VERSION ""

NS_ :

BS_:

BU_: WRCS SRS LECM3 LECM1 ECUspare6 CMS CIOM CCM AlcoLock2

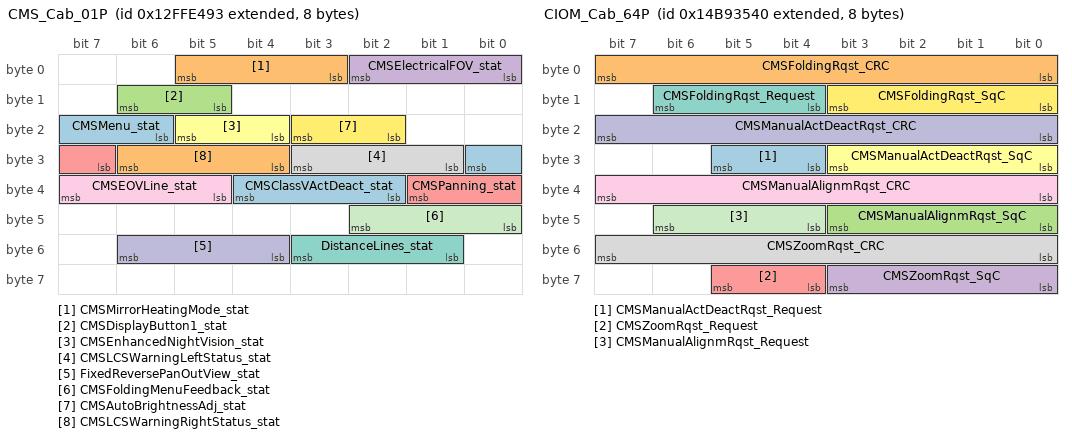
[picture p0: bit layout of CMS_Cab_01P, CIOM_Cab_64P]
BO_ 2466243731 CMS_Cab_01P: 8 CMS
 SG_ CMSMenu_stat : 22|3@1+ (1,0) [0|0] ""  CIOM
 SG_ CMSMirrorHeatingMode_stat : 3|3@1+ (1,0) [0|0] ""  CIOM
 SG_ CMSDisplayButton1_stat : 13|2@1+ (1,0) [0|0] ""  CIOM
 SG_ CMSElectricalFOV_stat : 0|3@1+ (1,0) [0|0] ""  CIOM
 SG_ CMSPanning_stat : 31|3@1+ (1,0) [0|0] ""  CIOM
 SG_ CMSEnhancedNightVision_stat : 20|2@1+ (1,0) [0|0] ""  CIOM
 SG_ DistanceLines_stat : 49|3@1+ (1,0) [0|0] ""  CIOM
 SG_ CMSLCSWarningLeftStatus_stat : 25|3@1+ (1,0) [0|0] ""  CIOM
 SG_ CMSEOVLine_stat : 37|3@1+ (1,0) [0|0] ""  CIOM
 SG_ FixedReversePanOutView_stat : 52|3@1+ (1,0) [0|0] ""  CIOM
 SG_ CMSFoldingMenuFeedback_stat : 40|3@1+ (1,0) [0|0] ""  CIOM
 SG_ CMSAutoBrightnessAdj_stat : 18|2@1+ (1,0) [0|0] ""  CIOM
 SG_ CMSClassVActDeact_stat : 34|3@1+ (1,0) [0|0] ""  CIOM
 SG_ CMSLCSWarningRightStatus_stat : 28|3@1+ (1,0) [0|0] ""  CIOM

BO_ 2495165760 CIOM_Cab_64P: 8 CIOM
 SG_ CMSManualActDeactRqst_Request : 28|2@1+ (1,0) [0|0] ""  CMS
 SG_ CMSFoldingRqst_CRC : 0|8@1+ (1,0) [0|255] ""  CMS
 SG_ CMSManualAlignmRqst_SqC : 40|4@1+ (1,0) [0|14] "NotApplicable"  CMS
 SG_ CMSZoomRqst_SqC : 56|4@1+ (1,0) [0|14] "NotApplicable"  CMS
 SG_ CMSZoomRqst_Request : 60|2@1+ (1,0) [0|0] ""  CMS
 SG_ CMSManualActDeactRqst_SqC : 24|4@1+ (1,0) [0|14] "NotApplicable"  CMS
 SG_ CMSFoldingRqst_Request : 12|3@1+ (1,0) [0|0] ""  CMS
 SG_ CMSZoomRqst_CRC : 48|8@1+ (1,0) [0|255] ""  CMS
 SG_ CMSManualAlignmRqst_CRC : 32|8@1+ (1,0) [0|255] ""  CMS
 SG_ CMSManualActDeactRqst_CRC : 16|8@1+ (1,0) [0|255] ""  CMS
 SG_ CMSManualAlignmRqst_Request : 44|3@1+ (1,0) [0|0] ""  CMS
 SG_ CMSFoldingRqst_SqC : 8|4@1+ (1,0) [0|14] "NotApplicable"  CMS

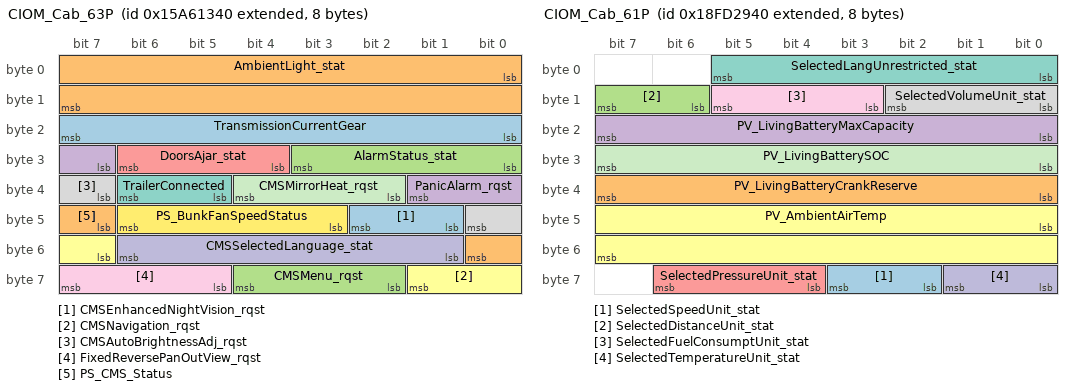
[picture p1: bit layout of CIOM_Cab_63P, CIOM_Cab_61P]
BO_ 2510689088 CIOM_Cab_63P: 8 CIOM
 SG_ CMSEnhancedNightVision_rqst : 41|2@1+ (1,0) [0|0] ""  CMS
 SG_ AmbientLight_stat : 0|16@1+ (1,0) [0|65535] "lx"  CMS
 SG_ CMSMenu_rqst : 58|3@1+ (1,0) [0|0] ""  CMS
 SG_ PanicAlarm_rqst : 31|3@1+ (1,0) [0|0] ""  CMS
 SG_ DoorsAjar_stat : 28|3@1+ (1,0) [0|0] ""  CMS
 SG_ CMSNavigation_rqst : 55|3@1+ (1,0) [0|0] ""  CMS
 SG_ TrailerConnected : 37|2@1+ (1,0) [0|0] ""  CMS
 SG_ CMSAutoBrightnessAdj_rqst : 39|2@1+ (1,0) [0|0] ""  CMS
 SG_ FixedReversePanOutView_rqst : 61|3@1+ (1,0) [0|0] ""  CMS
 SG_ CMSSelectedLanguage_stat : 49|6@1+ (1,0) [0|0] ""  CMS
 SG_ CMSMirrorHeat_rqst : 34|3@1+ (1,0) [0|0] ""  CMS
 SG_ PS_BunkFanSpeedStatus : 43|4@1+ (1,0) [0|0] ""  LECM3
 SG_ TransmissionCurrentGear : 16|8@1+ (1,-125) [-125|130] "GearValue"  CMS
 SG_ PS_CMS_Status : 47|2@1+ (1,0) [0|0] ""  LECM3
 SG_ AlarmStatus_stat : 24|4@1+ (1,0) [0|0] ""  CMS

BO_ 2566730048 CIOM_Cab_62P: 8 CIOM
 SG_ BunkACRequest : 14|2@1+ (1,0) [0|0] ""  CCM
 SG_ ClimateAirDistRequest_Vent : 8|4@1+ (1,0) [0|15] "NotApplicable"  CCM
 SG_ OpLevelItem3 : 56|8@1+ (0.5,0) [0|127.5] "Percent"  CCM
 SG_ AirRecirculationRequest : 28|2@1+ (1,0) [0|0] ""  CCM
 SG_ MaxDefrostRequest : 24|2@1+ (1,0) [0|0] ""  CCM
 SG_ CabTempRequest : 30|7@1+ (0.5,0) [0|63.5] "DegreeC"  CCM
 SG_ HVACBlowerRequest : 44|5@1+ (1,0) [0|31] "NotApplicable"  CCM
 SG_ ClimateAirDistRequest_Defrost : 4|4@1+ (1,0) [0|15] "NotApplicable"  CCM
 SG_ BunkParkClimateRequest : 54|2@1+ (1,0) [0|0] ""  CCM
 SG_ ParkingClimateRequest : 26|2@1+ (1,0) [0|0] ""  CCM
 SG_ BunkClimatePowerRequest : 22|2@1+ (1,0) [0|0] ""  CCM
 SG_ BunkClimateAutoRequest : 18|2@1+ (1,0) [0|0] ""  CCM
 SG_ ClimatePowerRequest : 20|2@1+ (1,0) [0|0] ""  CCM
 SG_ ClimateAirDistRequest_Floor : 0|4@1+ (1,0) [0|15] "NotApplicable"  CCM
 SG_ BunkHVACBlowerRequest : 49|5@1+ (1,0) [0|31] "NotApplicable"  CCM
 SG_ BunkTempRequest : 37|7@1+ (0.5,0) [0|63.5] "DegreeC"  CCM
 SG_ ClimateAutoRequest : 16|2@1+ (1,0) [0|0] ""  CCM
 SG_ ACRequest : 12|2@1+ (1,0) [0|0] ""  CCM

BO_ 2566728000 CIOM_Cab_61P: 8 CIOM
 SG_ SelectedSpeedUnit_stat : 58|2@1+ (1,0) [0|0] ""  LECM3
 SG_ PV_LivingBatteryCrankReserve : 32|8@1+ (0.5,0) [0|127.5] "Percent"  LECM3
 SG_ SelectedDistanceUnit_stat : 14|2@1+ (1,0) [0|0] ""  LECM3
 SG_ PV_LivingBatteryMaxCapacity : 16|8@1+ (0.5,0) [0|127.5] "Percent"  LECM3
 SG_ SelectedPressureUnit_stat : 60|3@1+ (1,0) [0|0] ""  LECM3
 SG_ PV_AmbientAirTemp : 40|16@1+ (0.03125,-273) [-273|1774.96875] "DegreeC"  LECM3
 SG_ SelectedLangUnrestricted_stat : 0|6@1+ (1,0) [0|0] ""  LECM3
 SG_ SelectedVolumeUnit_stat : 8|3@1+ (1,0) [0|0] ""  LECM3
 SG_ SelectedFuelConsumptUnit_stat : 11|3@1+ (1,0) [0|0] ""  LECM3
 SG_ SelectedTemperatureUnit_stat : 56|2@1+ (1,0) [0|0] ""  LECM3
 SG_ PV_LivingBatterySOC : 24|8@1+ (0.5,0) [0|127.5] "Percent"  LECM3

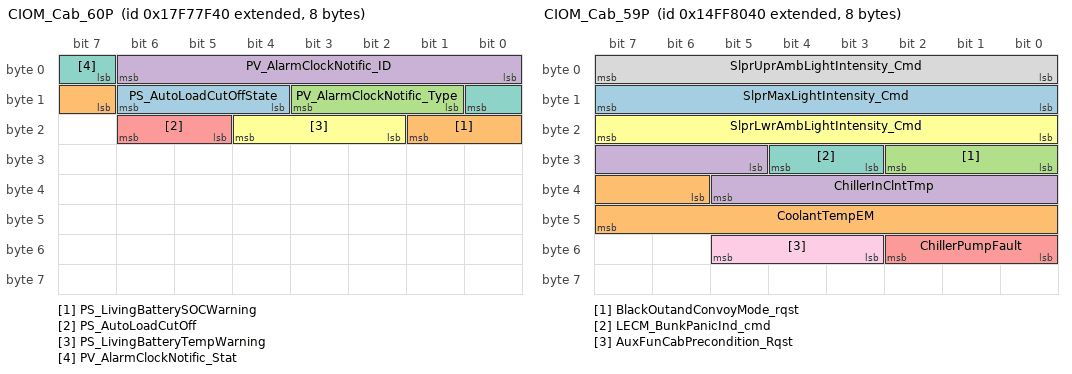
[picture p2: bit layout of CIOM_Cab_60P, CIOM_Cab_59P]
BO_ 2549579584 CIOM_Cab_60P: 8 CIOM
 SG_ PS_AutoLoadCutOffState : 12|3@1+ (1,0) [0|0] ""  LECM3
 SG_ PS_LivingBatterySOCWarning : 15|3@1+ (1,0) [0|0] ""  LECM3
 SG_ PV_AlarmClockNotific_Type : 9|3@1+ (1,0) [0|0] ""  LECM3
 SG_ PV_AlarmClockNotific_ID : 0|7@1+ (1,0) [0|0] ""  LECM3
 SG_ PS_AutoLoadCutOff : 21|2@1+ (1,0) [0|0] ""  LECM3
 SG_ PS_LivingBatteryTempWarning : 18|3@1+ (1,0) [0|0] ""  LECM3
 SG_ PV_AlarmClockNotific_Stat : 7|2@1+ (1,0) [0|0] ""  LECM3

BO_ 2499772480 CIOM_Cab_59P: 8 CIOM
 SG_ SlprMaxLightIntensity_Cmd : 8|8@1+ (1,0) [0|255] "Percent"  LECM3
 SG_ CoolantTempEM : 38|10@1+ (0.1,-10) [-10|92.3] "DegreeC"  CCM
 SG_ BlackOutandConvoyMode_rqst : 24|3@1+ (1,0) [0|0] ""  LECM3
 SG_ ChillerInClntTmp : 29|9@1+ (0.1,0) [0|51.1] "DegreeC"  CCM
 SG_ ChillerPumpFault : 48|3@1+ (1,0) [0|0] ""  CCM
 SG_ SlprLwrAmbLightIntensity_Cmd : 16|8@1+ (1,0) [0|255] "Percent"  LECM3
 SG_ LECM_BunkPanicInd_cmd : 27|2@1+ (1,0) [0|0] ""  LECM3
 SG_ SlprUprAmbLightIntensity_Cmd : 0|8@1+ (1,0) [0|255] "Percent"  LECM3
 SG_ AuxFunCabPrecondition_Rqst : 51|3@1+ (1,0) [0|0] ""  CCM

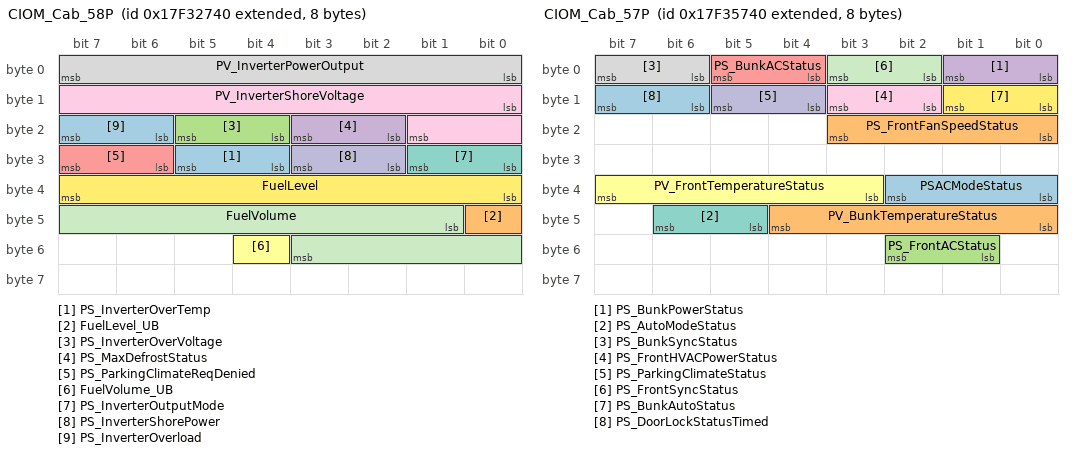
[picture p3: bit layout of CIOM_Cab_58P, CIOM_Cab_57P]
BO_ 2549294912 CIOM_Cab_58P: 8 CIOM
 SG_ PS_InverterOverTemp : 28|2@1+ (1,0) [0|0] ""  LECM3
 SG_ FuelLevel_UB : 40|1@1+ (1,0) [0|0] "" Vector__XXX
 SG_ PS_InverterOverVoltage : 20|2@1+ (1,0) [0|0] ""  LECM3
 SG_ PS_MaxDefrostStatus : 18|2@1+ (1,0) [0|0] ""  LECM3
 SG_ PS_ParkingClimateReqDenied : 30|2@1+ (1,0) [0|0] ""  LECM3
 SG_ FuelVolume_UB : 52|1@1+ (1,0) [0|0] "" Vector__XXX
 SG_ PS_InverterOutputMode : 24|2@1+ (1,0) [0|0] ""  LECM3
 SG_ PV_InverterPowerOutput : 0|8@1+ (10,0) [0|2550] "W"  LECM3
 SG_ PV_InverterShoreVoltage : 8|10@1+ (1,0) [0|1023] "V"  LECM3
 SG_ PS_InverterShorePower : 26|2@1+ (1,0) [0|0] ""  LECM3
 SG_ FuelVolume : 41|11@1+ (1,0) [0|2047] "l"  CCM
 SG_ FuelLevel : 32|8@1+ (0.4,0) [0|102] "Percent"  CCM
 SG_ PS_InverterOverload : 22|2@1+ (1,0) [0|0] ""  LECM3

BO_ 2549307200 CIOM_Cab_57P: 8 CIOM
 SG_ PSACModeStatus : 32|3@1+ (1,0) [0|0] ""  LECM3
 SG_ PS_FrontFanSpeedStatus : 16|4@1+ (1,0) [0|0] ""  LECM3
 SG_ PS_FrontACStatus : 49|2@1+ (1,0) [0|0] ""  LECM3
 SG_ PS_BunkPowerStatus : 0|2@1+ (1,0) [0|0] ""  LECM3
 SG_ PS_BunkACStatus : 4|2@1+ (1,0) [0|0] ""  LECM3
 SG_ PV_FrontTemperatureStatus : 35|5@1+ (1,0) [0|0] ""  LECM3
 SG_ PS_AutoModeStatus : 45|2@1+ (1,0) [0|0] ""  LECM3
 SG_ PS_BunkSyncStatus : 6|2@1+ (1,0) [0|0] ""  LECM3
 SG_ PS_FrontHVACPowerStatus : 10|2@1+ (1,0) [0|0] ""  LECM3
 SG_ PS_ParkingClimateStatus : 12|2@1+ (1,0) [0|0] ""  LECM3
 SG_ PS_FrontSyncStatus : 2|2@1+ (1,0) [0|0] ""  LECM3
 SG_ PS_BunkAutoStatus : 8|2@1+ (1,0) [0|0] ""  LECM3
 SG_ PS_DoorLockStatusTimed : 14|2@1+ (1,0) [0|0] ""  LECM3
 SG_ PV_BunkTemperatureStatus : 40|5@1+ (1,0) [0|0] ""  LECM3

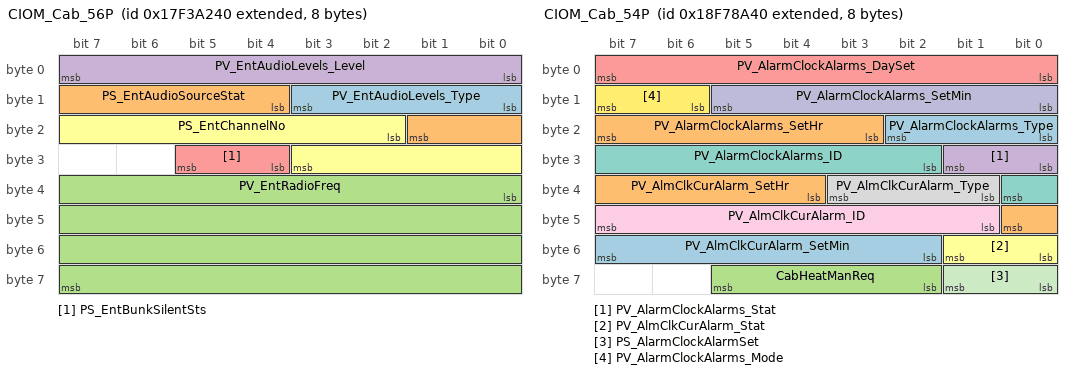
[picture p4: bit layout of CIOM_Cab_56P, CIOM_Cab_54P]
BO_ 2549326400 CIOM_Cab_56P: 8 CIOM
 SG_ PV_EntAudioLevels_Type : 8|4@1+ (1,0) [0|0] ""  LECM3
 SG_ PS_EntAudioSourceStat : 12|6@1+ (1,0) [0|0] ""  LECM3
 SG_ PV_EntRadioFreq : 32|32@1+ (1000,0) [0|4294967295000] "Hz"  LECM3
 SG_ PV_EntAudioLevels_Level : 0|8@1+ (1,-100) [-100|155] "Percent"  LECM3
 SG_ PS_EntBunkSilentSts : 28|2@1+ (1,0) [0|0] ""  LECM3
 SG_ PS_EntChannelNo : 18|10@1+ (1,0) [0|1023] "NotApplicable"  LECM3

BO_ 2566293568 CIOM_Cab_55P: 8 CIOM
 SG_ PSPClimTimStatus_Tue : 3|1@1+ (1,0) [0|0] ""  LECM3
 SG_ PSPClimTimStatus_Min : 8|8@1+ (1,0) [0|255] "min"  LECM3
 SG_ PSPClimTimStatus_TotalNoTimers : 32|8@1+ (1,0) [0|0] ""  LECM3
 SG_ PSPClimTimStatus_TimerNr : 40|8@1+ (1,0) [0|0] ""  LECM3
 SG_ PSPClimTimStatus_Rec : 0|1@1+ (1,0) [0|0] ""  LECM3
 SG_ PSPClimTimStatus_Status : 22|2@1+ (1,0) [0|0] ""  LECM3
 SG_ PSPClimTimStatus_Dur : 56|7@1+ (1,0) [0|127] "min"  LECM3
 SG_ PSPClimTimStatus_Type : 19|3@1+ (1,0) [0|0] ""  LECM3
 SG_ PSPClimTimStatus_Wed : 6|1@1+ (1,0) [0|0] ""  LECM3
 SG_ PSPClimTimStatus_Fri : 1|1@1+ (1,0) [0|0] ""  LECM3
 SG_ PSPClimTimStatus_Thu : 2|1@1+ (1,0) [0|0] ""  LECM3
 SG_ PSPClimTimStatus_Sat : 7|1@1+ (1,0) [0|0] ""  LECM3
 SG_ PSPClimTimStatus_Hrs : 24|8@1+ (1,0) [0|255] "h"  LECM3
 SG_ PSPClimTimStatus_MinRes : 16|3@1+ (1,0) [0|0] ""  LECM3
 SG_ PSPClimTimStatus_Temp : 48|8@1+ (0.5,0) [0|127.5] "DegreeC"  LECM3
 SG_ PSPClimTimStatus_Sun : 5|1@1+ (1,0) [0|0] ""  LECM3
 SG_ PSPClimTimStatus_Mon : 4|1@1+ (1,0) [0|0] ""  LECM3

BO_ 2566359616 CIOM_Cab_54P: 8 CIOM
 SG_ PV_AlarmClockAlarms_Type : 16|3@1+ (1,0) [0|0] ""  LECM3
 SG_ PV_AlmClkCurAlarm_SetHr : 36|5@1+ (1,0) [0|31] "h"  LECM3
 SG_ CabHeatManReq : 58|4@1+ (1,0) [0|15] "NotApplicable"  CCM
 SG_ PV_AlarmClockAlarms_Stat : 24|2@1+ (1,0) [0|0] ""  LECM3
 SG_ PV_AlarmClockAlarms_DaySet : 0|8@1+ (1,0) [0|255] ""  LECM3
 SG_ PV_AlmClkCurAlarm_Stat : 48|2@1+ (1,0) [0|0] ""  LECM3
 SG_ PV_AlarmClockAlarms_ID : 26|7@1+ (1,0) [0|0] ""  LECM3
 SG_ PV_AlmClkCurAlarm_Type : 33|3@1+ (1,0) [0|0] ""  LECM3
 SG_ PV_AlmClkCurAlarm_ID : 41|7@1+ (1,0) [0|0] ""  LECM3
 SG_ PV_AlarmClockAlarms_SetMin : 8|6@1+ (1,0) [0|63] "min"  LECM3
 SG_ PS_AlarmClockAlarmSet : 56|2@1+ (1,0) [0|0] ""  LECM3
 SG_ PV_AlarmClockAlarms_Mode : 14|2@1+ (1,0) [0|0] ""  LECM3
 SG_ PV_AlmClkCurAlarm_SetMin : 50|6@1+ (1,0) [0|63] "min"  LECM3
 SG_ PV_AlarmClockAlarms_SetHr : 19|5@1+ (1,0) [0|31] "h"  LECM3

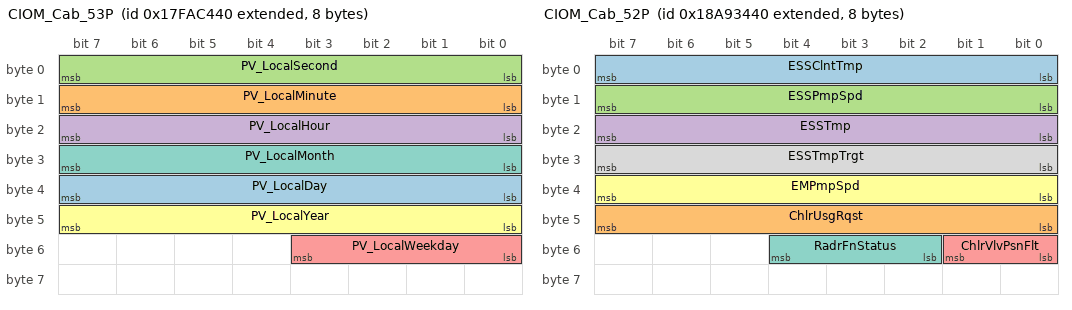
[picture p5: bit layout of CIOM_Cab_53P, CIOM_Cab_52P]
BO_ 2549793856 CIOM_Cab_53P: 8 CIOM
 SG_ PV_LocalDay : 32|8@1+ (1,0) [0|255] "Days"  LECM3
 SG_ PV_LocalMinute : 8|8@1+ (1,0) [0|255] "min"  LECM3
 SG_ PV_LocalSecond : 0|8@1+ (1,0) [0|255] "s"  LECM3
 SG_ PV_LocalHour : 16|8@1+ (1,0) [0|255] "h"  LECM3
 SG_ PV_LocalWeekday : 48|4@1+ (1,0) [0|0] ""  LECM3
 SG_ PV_LocalYear : 40|8@1+ (1,1985) [1985|2240] "Years"  LECM3
 SG_ PV_LocalMonth : 24|8@1+ (1,0) [0|255] "Months"  LECM3

BO_ 2561225792 CIOM_Cab_52P: 8 CIOM
 SG_ ESSClntTmp : 0|8@1+ (0.5,-25) [-25|102.5] "DegreeC"  CCM
 SG_ ChlrUsgRqst : 40|8@1+ (1,0) [0|255] "Percent"  CCM
 SG_ ESSPmpSpd : 8|8@1+ (1,0) [0|255] "Percent"  CCM
 SG_ ESSTmp : 16|8@1+ (0.5,-25) [-25|102.5] "DegreeC"  CCM
 SG_ ChlrVlvPsnFlt : 48|2@1+ (1,0) [0|0] ""  CCM
 SG_ EMPmpSpd : 32|8@1+ (1,0) [0|255] "Percent"  CCM
 SG_ RadrFnStatus : 50|3@1+ (1,0) [0|0] ""  CCM
 SG_ ESSTmpTrgt : 24|8@1+ (1,0) [0|255] "DegreeC"  CCM

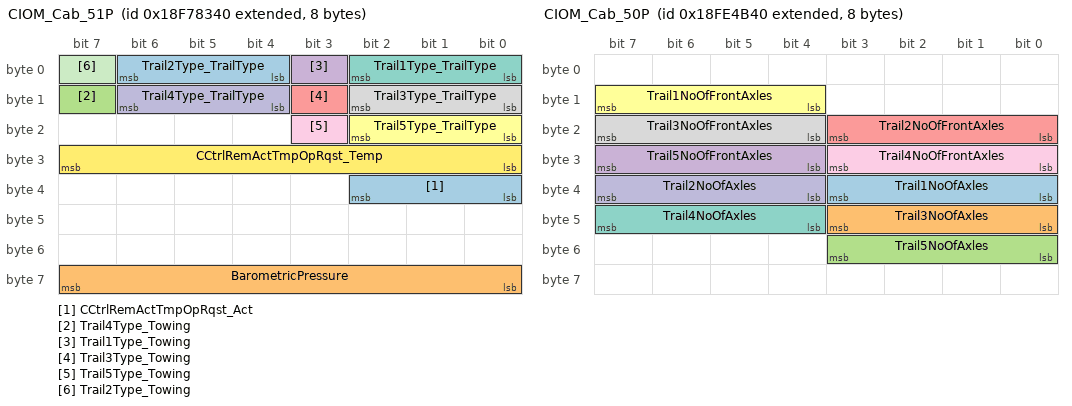
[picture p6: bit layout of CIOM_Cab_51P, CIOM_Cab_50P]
BO_ 2566357824 CIOM_Cab_51P: 8 CIOM
 SG_ CCtrlRemActTmpOpRqst_Act : 32|3@1+ (1,0) [0|0] ""  CCM
 SG_ BarometricPressure : 56|8@1+ (0.5,0) [0|127.5] "kPa"  CCM
 SG_ Trail4Type_Towing : 15|1@1+ (1,0) [0|0] ""  WRCS
 SG_ Trail1Type_Towing : 3|1@1+ (1,0) [0|0] ""  WRCS
 SG_ Trail3Type_Towing : 11|1@1+ (1,0) [0|0] ""  WRCS
 SG_ Trail5Type_TrailType : 16|3@1+ (1,0) [0|0] ""  WRCS
 SG_ Trail1Type_TrailType : 0|3@1+ (1,0) [0|0] ""  WRCS
 SG_ Trail3Type_TrailType : 8|3@1+ (1,0) [0|0] ""  WRCS
 SG_ Trail5Type_Towing : 19|1@1+ (1,0) [0|0] ""  WRCS
 SG_ Trail4Type_TrailType : 12|3@1+ (1,0) [0|0] ""  WRCS
 SG_ Trail2Type_Towing : 7|1@1+ (1,0) [0|0] ""  WRCS
 SG_ CCtrlRemActTmpOpRqst_Temp : 24|8@1+ (0.5,0) [0|127.5] "DegreeC"  CCM
 SG_ Trail2Type_TrailType : 4|3@1+ (1,0) [0|0] ""  WRCS

BO_ 2566802240 CIOM_Cab_50P: 8 CIOM
 SG_ Trail1NoOfAxles : 32|4@1+ (1,0) [0|15] "NotApplicable"  WRCS
 SG_ Trail3NoOfAxles : 40|4@1+ (1,0) [0|15] "NotApplicable"  WRCS
 SG_ Trail5NoOfAxles : 48|4@1+ (1,0) [0|15] "NotApplicable"  WRCS
 SG_ Trail5NoOfFrontAxles : 28|4@1+ (1,0) [0|15] "NotApplicable"  WRCS
 SG_ Trail2NoOfFrontAxles : 16|4@1+ (1,0) [0|15] "NotApplicable"  WRCS
 SG_ Trail1NoOfFrontAxles : 12|4@1+ (1,0) [0|15] "NotApplicable"  WRCS
 SG_ Trail4NoOfAxles : 44|4@1+ (1,0) [0|15] "NotApplicable"  WRCS
 SG_ Trail3NoOfFrontAxles : 20|4@1+ (1,0) [0|15] "NotApplicable"  WRCS
 SG_ Trail4NoOfFrontAxles : 24|4@1+ (1,0) [0|15] "NotApplicable"  WRCS
 SG_ Trail2NoOfAxles : 36|4@1+ (1,0) [0|15] "NotApplicable"  WRCS

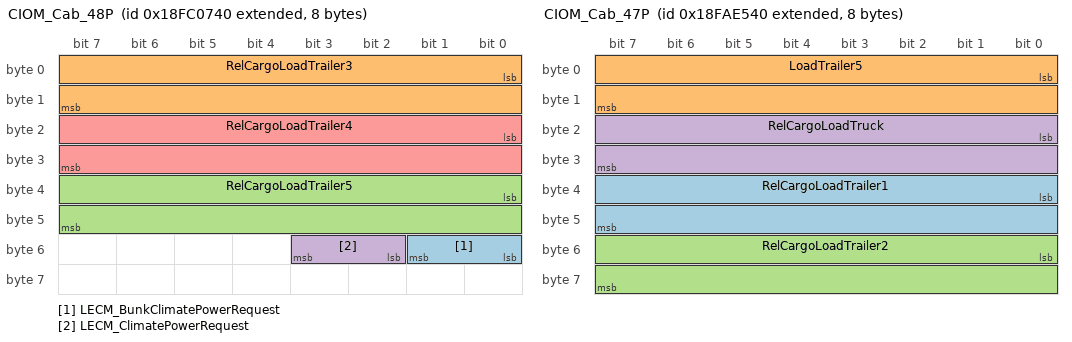
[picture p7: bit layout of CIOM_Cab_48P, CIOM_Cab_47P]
BO_ 2566653760 CIOM_Cab_48P: 8 CIOM
 SG_ LECM_BunkClimatePowerRequest : 48|2@1+ (1,0) [0|0] ""  CCM
 SG_ RelCargoLoadTrailer3 : 0|16@1+ (4,-128508) [-128508|133632] "kg"  WRCS
 SG_ RelCargoLoadTrailer5 : 32|16@1+ (4,-128508) [-128508|133632] "kg"  WRCS
 SG_ LECM_ClimatePowerRequest : 50|2@1+ (1,0) [0|0] ""  CCM
 SG_ RelCargoLoadTrailer4 : 16|16@1+ (4,-128508) [-128508|133632] "kg"  WRCS

BO_ 2566579520 CIOM_Cab_47P: 8 CIOM
 SG_ RelCargoLoadTrailer1 : 32|16@1+ (4,-128508) [-128508|133632] "kg"  WRCS
 SG_ LoadTrailer5 : 0|16@1+ (2,0) [0|131070] "kg"  WRCS
 SG_ RelCargoLoadTrailer2 : 48|16@1+ (4,-128508) [-128508|133632] "kg"  WRCS
 SG_ RelCargoLoadTruck : 16|16@1+ (4,-128508) [-128508|133632] "kg"  WRCS

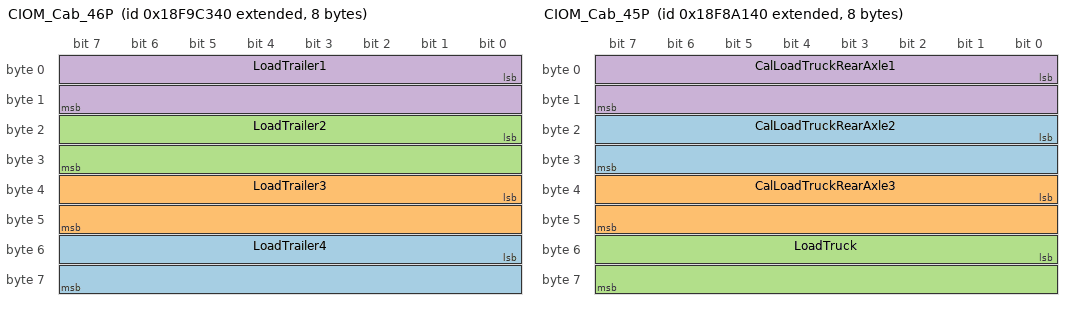
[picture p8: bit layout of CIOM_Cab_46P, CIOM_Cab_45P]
BO_ 2566505280 CIOM_Cab_46P: 8 CIOM
 SG_ LoadTrailer4 : 48|16@1+ (2,0) [0|131070] "kg"  WRCS
 SG_ LoadTrailer3 : 32|16@1+ (2,0) [0|131070] "kg"  WRCS
 SG_ LoadTrailer2 : 16|16@1+ (2,0) [0|131070] "kg"  WRCS
 SG_ LoadTrailer1 : 0|16@1+ (2,0) [0|131070] "kg"  WRCS

BO_ 2566431040 CIOM_Cab_45P: 8 CIOM
 SG_ CalLoadTruckRearAxle2 : 16|16@1+ (0.5,0) [0|32767.5] "kg"  WRCS
 SG_ CalLoadTruckRearAxle3 : 32|16@1+ (0.5,0) [0|32767.5] "kg"  WRCS
 SG_ LoadTruck : 48|16@1+ (2,0) [0|131070] "kg"  WRCS
 SG_ CalLoadTruckRearAxle1 : 0|16@1+ (0.5,0) [0|32767.5] "kg"  WRCS

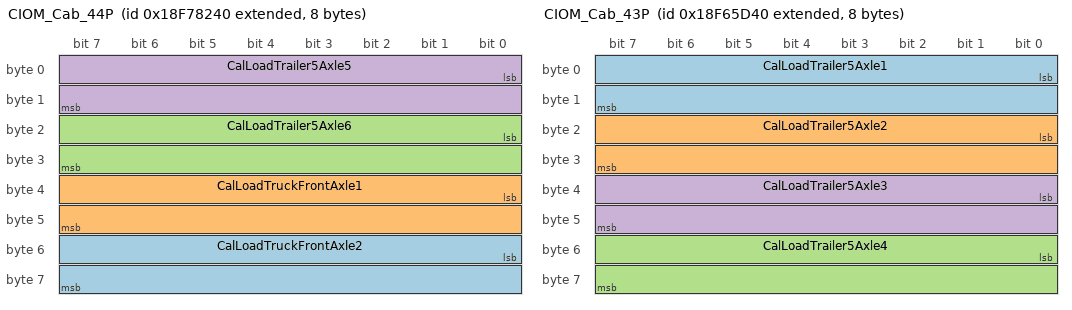
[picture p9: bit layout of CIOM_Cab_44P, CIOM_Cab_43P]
BO_ 2566357568 CIOM_Cab_44P: 8 CIOM
 SG_ CalLoadTruckFrontAxle2 : 48|16@1+ (0.5,0) [0|32767.5] "kg"  WRCS
 SG_ CalLoadTruckFrontAxle1 : 32|16@1+ (0.5,0) [0|32767.5] "kg"  WRCS
 SG_ CalLoadTrailer5Axle6 : 16|16@1+ (0.5,0) [0|32767.5] "kg"  WRCS
 SG_ CalLoadTrailer5Axle5 : 0|16@1+ (0.5,0) [0|32767.5] "kg"  WRCS

BO_ 2566282560 CIOM_Cab_43P: 8 CIOM
 SG_ CalLoadTrailer5Axle1 : 0|16@1+ (0.5,0) [0|32767.5] "kg"  WRCS
 SG_ CalLoadTrailer5Axle2 : 16|16@1+ (0.5,0) [0|32767.5] "kg"  WRCS
 SG_ CalLoadTrailer5Axle4 : 48|16@1+ (0.5,0) [0|32767.5] "kg"  WRCS
 SG_ CalLoadTrailer5Axle3 : 32|16@1+ (0.5,0) [0|32767.5] "kg"  WRCS

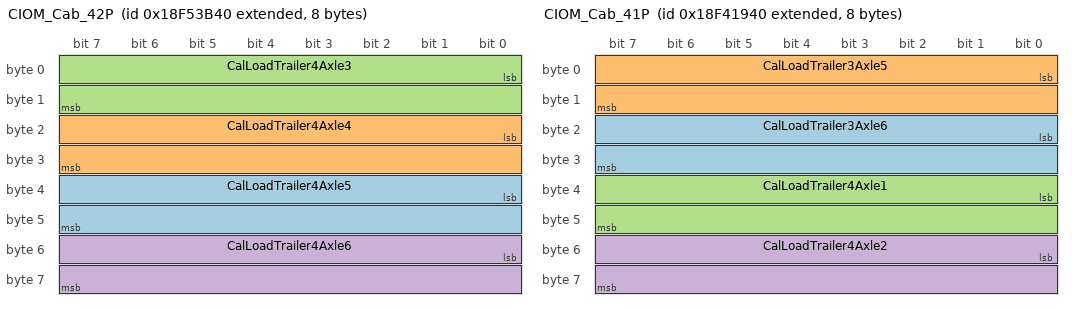
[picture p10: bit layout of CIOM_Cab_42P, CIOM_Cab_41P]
BO_ 2566208320 CIOM_Cab_42P: 8 CIOM
 SG_ CalLoadTrailer4Axle5 : 32|16@1+ (0.5,0) [0|32767.5] "kg"  WRCS
 SG_ CalLoadTrailer4Axle4 : 16|16@1+ (0.5,0) [0|32767.5] "kg"  WRCS
 SG_ CalLoadTrailer4Axle3 : 0|16@1+ (0.5,0) [0|32767.5] "kg"  WRCS
 SG_ CalLoadTrailer4Axle6 : 48|16@1+ (0.5,0) [0|32767.5] "kg"  WRCS

BO_ 2566134080 CIOM_Cab_41P: 8 CIOM
 SG_ CalLoadTrailer3Axle6 : 16|16@1+ (0.5,0) [0|32767.5] "kg"  WRCS
 SG_ CalLoadTrailer3Axle5 : 0|16@1+ (0.5,0) [0|32767.5] "kg"  WRCS
 SG_ CalLoadTrailer4Axle1 : 32|16@1+ (0.5,0) [0|32767.5] "kg"  WRCS
 SG_ CalLoadTrailer4Axle2 : 48|16@1+ (0.5,0) [0|32767.5] "kg"  WRCS

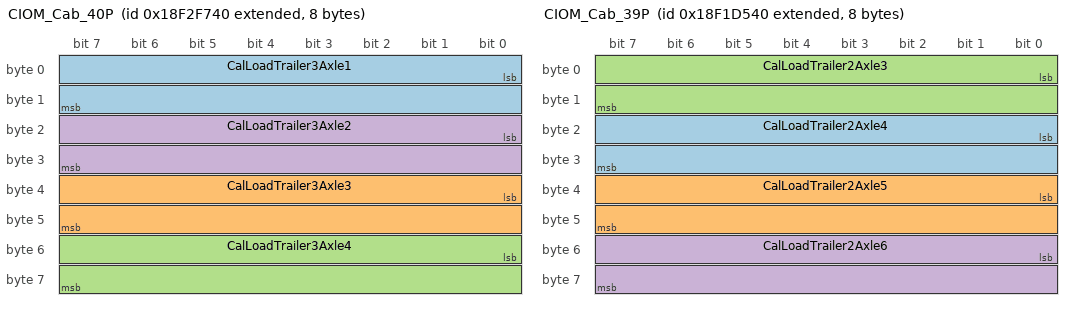
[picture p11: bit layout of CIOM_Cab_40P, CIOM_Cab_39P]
BO_ 2566059840 CIOM_Cab_40P: 8 CIOM
 SG_ CalLoadTrailer3Axle1 : 0|16@1+ (0.5,0) [0|32767.5] "kg"  WRCS
 SG_ CalLoadTrailer3Axle3 : 32|16@1+ (0.5,0) [0|32767.5] "kg"  WRCS
 SG_ CalLoadTrailer3Axle4 : 48|16@1+ (0.5,0) [0|32767.5] "kg"  WRCS
 SG_ CalLoadTrailer3Axle2 : 16|16@1+ (0.5,0) [0|32767.5] "kg"  WRCS

BO_ 2565985600 CIOM_Cab_39P: 8 CIOM
 SG_ CalLoadTrailer2Axle4 : 16|16@1+ (0.5,0) [0|32767.5] "kg"  WRCS
 SG_ CalLoadTrailer2Axle5 : 32|16@1+ (0.5,0) [0|32767.5] "kg"  WRCS
 SG_ CalLoadTrailer2Axle3 : 0|16@1+ (0.5,0) [0|32767.5] "kg"  WRCS
 SG_ CalLoadTrailer2Axle6 : 48|16@1+ (0.5,0) [0|32767.5] "kg"  WRCS

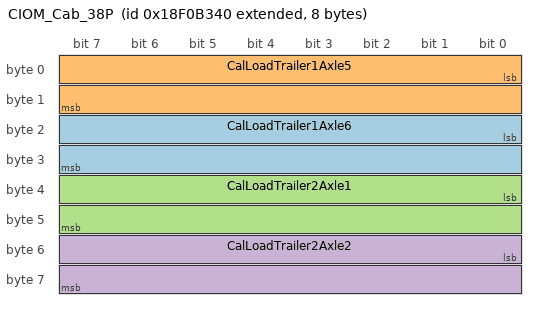
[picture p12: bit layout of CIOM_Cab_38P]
BO_ 2565911360 CIOM_Cab_38P: 8 CIOM
 SG_ CalLoadTrailer1Axle6 : 16|16@1+ (0.5,0) [0|32767.5] "kg"  WRCS
 SG_ CalLoadTrailer1Axle5 : 0|16@1+ (0.5,0) [0|32767.5] "kg"  WRCS
 SG_ CalLoadTrailer2Axle1 : 32|16@1+ (0.5,0) [0|32767.5] "kg"  WRCS
 SG_ CalLoadTrailer2Axle2 : 48|16@1+ (0.5,0) [0|32767.5] "kg"  WRCS

CM_ SG_ 2510689088 TransmissionCurrentGear "254 Error ; 255 Not available";
CM_ SG_ 2549294912 FuelLevel "254 Error ; 255 Not available";
CM_ SG_ 2566357824 BarometricPressure "254 Error ; 255 Not available";
CM_ SG_ 2566802240 Trail1NoOfAxles "15 Not available";
CM_ SG_ 2566802240 Trail3NoOfAxles "15 Not available";
CM_ SG_ 2566802240 Trail5NoOfAxles "15 Not available";
CM_ SG_ 2566802240 Trail5NoOfFrontAxles "15 Not available";
CM_ SG_ 2566802240 Trail2NoOfFrontAxles "15 Not available";
CM_ SG_ 2566802240 Trail1NoOfFrontAxles "15 Not available";
CM_ SG_ 2566802240 Trail4NoOfAxles "15 Not available";
CM_ SG_ 2566802240 Trail3NoOfFrontAxles "15 Not available";
CM_ SG_ 2566802240 Trail4NoOfFrontAxles "15 Not available";
CM_ SG_ 2566802240 Trail2NoOfAxles "15 Not available";
CM_ SG_ 2566579520 LoadTrailer5 "65024 - 65279 Error ; 65280 - 65535 Not Available";
CM_ SG_ 2566505280 LoadTrailer4 "65024 - 65279 Error ; 65280 - 65535 Not Available";
CM_ SG_ 2566505280 LoadTrailer3 "65024 - 65279 Error ; 65280 - 65535 Not Available";
CM_ SG_ 2566505280 LoadTrailer2 "65024 - 65279 Error ; 65280 - 65535 Not Available";
CM_ SG_ 2566505280 LoadTrailer1 "65024 - 65279 Error ; 65280 - 65535 Not Available";
CM_ SG_ 2566431040 CalLoadTruckRearAxle2 "65024 - 65279 Error ; 65280 - 65535 Not available";
CM_ SG_ 2566431040 CalLoadTruckRearAxle3 "65024 - 65279 Error ; 65280 - 65535 Not available";
CM_ SG_ 2566431040 LoadTruck "65024 - 65279 Error ; 65280 - 65535 Not Available";
CM_ SG_ 2566431040 CalLoadTruckRearAxle1 "65024 - 65279 Error ; 65280 - 65535 Not available";
CM_ SG_ 2566357568 CalLoadTruckFrontAxle2 "65024 - 65279 Error ; 65280 - 65535 Not available";
CM_ SG_ 2566357568 CalLoadTruckFrontAxle1 "65024 - 65279 Error ; 65280 - 65535 Not available";
CM_ SG_ 2566357568 CalLoadTrailer5Axle6 "65024 - 65279 Error ; 65280 - 65535 Not available";
CM_ SG_ 2566357568 CalLoadTrailer5Axle5 "65024 - 65279 Error ; 65280 - 65535 Not available";
CM_ SG_ 2566282560 CalLoadTrailer5Axle1 "65024 - 65279 Error ; 65280 - 65535 Not available";
CM_ SG_ 2566282560 CalLoadTrailer5Axle2 "65024 - 65279 Error ; 65280 - 65535 Not available";
CM_ SG_ 2566282560 CalLoadTrailer5Axle4 "65024 - 65279 Error ; 65280 - 65535 Not available";
CM_ SG_ 2566282560 CalLoadTrailer5Axle3 "65024 - 65279 Error ; 65280 - 65535 Not available";
CM_ SG_ 2566208320 CalLoadTrailer4Axle5 "65024 - 65279 Error ; 65280 - 65535 Not available";
CM_ SG_ 2566208320 CalLoadTrailer4Axle4 "65024 - 65279 Error ; 65280 - 65535 Not available";
CM_ SG_ 2566208320 CalLoadTrailer4Axle3 "65024 - 65279 Error ; 65280 - 65535 Not available";
CM_ SG_ 2566208320 CalLoadTrailer4Axle6 "65024 - 65279 Error ; 65280 - 65535 Not available";
CM_ SG_ 2566134080 CalLoadTrailer3Axle6 "65024 - 65279 Error ; 65280 - 65535 Not available";
CM_ SG_ 2566134080 CalLoadTrailer3Axle5 "65024 - 65279 Error ; 65280 - 65535 Not available";
CM_ SG_ 2566134080 CalLoadTrailer4Axle1 "65024 - 65279 Error ; 65280 - 65535 Not available";
CM_ SG_ 2566134080 CalLoadTrailer4Axle2 "65024 - 65279 Error ; 65280 - 65535 Not available";
CM_ SG_ 2566059840 CalLoadTrailer3Axle1 "65024 - 65279 Error ; 65280 - 65535 Not available";
CM_ SG_ 2566059840 CalLoadTrailer3Axle3 "65024 - 65279 Error ; 65280 - 65535 Not available";
CM_ SG_ 2566059840 CalLoadTrailer3Axle4 "65024 - 65279 Error ; 65280 - 65535 Not available";
CM_ SG_ 2566059840 CalLoadTrailer3Axle2 "65024 - 65279 Error ; 65280 - 65535 Not available";
CM_ SG_ 2565985600 CalLoadTrailer2Axle4 "65024 - 65279 Error ; 65280 - 65535 Not available";
CM_ SG_ 2565985600 CalLoadTrailer2Axle5 "65024 - 65279 Error ; 65280 - 65535 Not available";
CM_ SG_ 2565985600 CalLoadTrailer2Axle3 "65024 - 65279 Error ; 65280 - 65535 Not available";
CM_ SG_ 2565985600 CalLoadTrailer2Axle6 "65024 - 65279 Error ; 65280 - 65535 Not available";
CM_ SG_ 2565911360 CalLoadTrailer1Axle6 "65024 - 65279 Error ; 65280 - 65535 Not available";
CM_ SG_ 2565911360 CalLoadTrailer1Axle5 "65024 - 65279 Error ; 65280 - 65535 Not available";
CM_ SG_ 2565911360 CalLoadTrailer2Axle1 "65024 - 65279 Error ; 65280 - 65535 Not available";
CM_ SG_ 2565911360 CalLoadTrailer2Axle2 "65024 - 65279 Error ; 65280 - 65535 Not available";
BA_DEF_ BO_  "GenMsgStartDelayTime" INT 0 0;
BA_DEF_ BO_  "GenMsgDelayTime" INT 0 0;
BA_DEF_ BO_  "GenMsgCycleTime" INT 0 0;
BA_DEF_ BO_  "GenMsgSendType" ENUM  "Cyclic","NotUsed","NotUsed","NotUsed","NotUsed","NotUsed","NotUsed","IfActive","NoMsgSendType","NotUsed";
BA_DEF_ SG_  "GenSigStartValue" INT 0 0;
BA_DEF_ SG_  "GenSigCycleTimeActive" INT 0 0;
BA_DEF_ SG_  "GenSigCycleTime" INT 0 0;
BA_DEF_ SG_  "GenSigSendType" ENUM  "Cyclic","OnWrite","OnWriteWithRepetition","OnChange","OnChangeWithRepetition","IfActive","IfActiveWithRepetition","NoSigSendType","NotUsed","NotUsed","NotUsed","NotUsed","NotUsed";
BA_DEF_ BO_  "VFrameFormat" ENUM  "StandardCAN","ExtendedCAN","reserved","J1939PG","reserved","reserved","reserved","reserved","reserved","reserved","reserved","reserved","reserved","reserved","StandardCAN_FD","ExtendedCAN_FD";
BA_DEF_ SG_  "SigType" ENUM  "Default","Range","RangeSigned","ASCII","Discrete","Control","ReferencePGN","DTC","StringDelimiter","StringLength","StringLengthControl";
BA_DEF_ SG_  "SeToolVersion_SIGNAL" STRING ;
BA_DEF_ SG_  "SeToolUniqueID_SIGNAL" STRING ;
BA_DEF_ SG_  "SeToolOwnerSigGroup_SIGNAL" STRING ;
BA_DEF_ SG_  "SeToolOwnerSigGroupID_SIGNAL" STRING ;
BA_DEF_ SG_  "SeToolName_SIGNAL" STRING ;
BA_DEF_ SG_  "SeToolItemID_SIGNAL" STRING ;
BA_DEF_ SG_  "SeToolAncestorID_SIGNAL" STRING ;
BA_DEF_ SG_  "Platform_VMCU1_Sig" ENUM  "No","Yes";
BA_DEF_ BO_  "NmAsrMessage" ENUM  "No","Yes";
BA_DEF_ SG_  "NeedsUpdateBit" ENUM  "No","Yes";
BA_DEF_ SG_  "MmAnSignal" ENUM  "No","Yes";
BA_DEF_ SG_  "GenSigMaxLatency" INT 0 65535;
BA_DEF_ SG_  "GenSigILSupport" ENUM  "Yes","No";
BA_DEF_ BO_  "GenMsgILSupport" ENUM  "No","Yes";
BA_DEF_ SG_  "E2EProfile" STRING ;
BA_DEF_ SG_  "E2EDataLength" INT 0 65535;
BA_DEF_ SG_  "E2EDataId" INT 0 65535;
BA_DEF_ BO_  "DiagUUDTResponse" ENUM  "No","Yes";
BA_DEF_ BO_  "DiagState" ENUM  "No","Yes";
BA_DEF_ BO_  "DiagResponse" ENUM  "No","Yes";
BA_DEF_ BO_  "DiagRequest" ENUM  "No","Yes";
BA_DEF_ BO_  "DiagConnection" HEX 0 65535;
BA_DEF_ BO_  "CanTpSTmin" INT 0 255;
BA_DEF_ BO_  "CanTpFcFrameId" HEX 0 2147483647;
BA_DEF_ BO_  "CanTpBs" INT 0 255;
BA_DEF_REL_ BU_SG_REL_  "GenSigTimeoutTime" INT 0 65535;
BA_DEF_REL_ BU_SG_REL_  "GenSigFirstTimeoutTime" INT 0 65535;
BA_DEF_DEF_  "GenMsgStartDelayTime" 0;
BA_DEF_DEF_  "GenMsgDelayTime" 0;
BA_DEF_DEF_  "GenMsgCycleTime" 0;
BA_DEF_DEF_  "GenMsgSendType" "Cyclic";
BA_DEF_DEF_  "GenSigStartValue" 0;
BA_DEF_DEF_  "GenSigCycleTimeActive" 0;
BA_DEF_DEF_  "GenSigCycleTime" 0;
BA_DEF_DEF_  "GenSigSendType" "Cyclic";
BA_DEF_DEF_  "VFrameFormat" "ExtendedCAN";
BA_DEF_DEF_  "SigType" "Default";
BA_DEF_DEF_  "SeToolVersion_SIGNAL" "";
BA_DEF_DEF_  "SeToolUniqueID_SIGNAL" "";
BA_DEF_DEF_  "SeToolOwnerSigGroup_SIGNAL" "";
BA_DEF_DEF_  "SeToolOwnerSigGroupID_SIGNAL" "";
BA_DEF_DEF_  "SeToolName_SIGNAL" "";
BA_DEF_DEF_  "SeToolItemID_SIGNAL" "";
BA_DEF_DEF_  "SeToolAncestorID_SIGNAL" "";
BA_DEF_DEF_  "Platform_VMCU1_Sig" "No";
BA_DEF_DEF_  "NmAsrMessage" "No";
BA_DEF_DEF_  "NeedsUpdateBit" "No";
BA_DEF_DEF_  "MmAnSignal" "No";
BA_DEF_DEF_  "GenSigMaxLatency" 0;
BA_DEF_DEF_  "GenSigILSupport" "Yes";
BA_DEF_DEF_  "GenMsgILSupport" "Yes";
BA_DEF_DEF_  "E2EProfile" "none";
BA_DEF_DEF_  "E2EDataLength" 0;
BA_DEF_DEF_  "E2EDataId" 0;
BA_DEF_DEF_  "DiagUUDTResponse" "No";
BA_DEF_DEF_  "DiagState" "No";
BA_DEF_DEF_  "DiagResponse" "No";
BA_DEF_DEF_  "DiagRequest" "No";
BA_DEF_DEF_  "DiagConnection" 0;
BA_DEF_DEF_  "CanTpSTmin" 0;
BA_DEF_DEF_  "CanTpFcFrameId" 2147483647;
BA_DEF_DEF_  "CanTpBs" 255;
BA_DEF_DEF_REL_ "GenSigTimeoutTime" 0;
BA_DEF_DEF_REL_ "GenSigFirstTimeoutTime" 0;
BA_ "GenMsgCycleTime" BO_ 2466243731 30;
BA_ "GenMsgStartDelayTime" BO_ 2466243731 5;
BA_ "GenMsgCycleTime" BO_ 2495165760 50;
BA_ "GenMsgStartDelayTime" BO_ 2495165760 30;
BA_ "GenMsgCycleTime" BO_ 2510689088 100;
BA_ "GenMsgStartDelayTime" BO_ 2510689088 35;
BA_ "GenMsgCycleTime" BO_ 2566730048 500;
BA_ "GenMsgDelayTime" BO_ 2566730048 50;
BA_ "GenMsgStartDelayTime" BO_ 2566730048 125;
BA_ "GenMsgCycleTime" BO_ 2566728000 500;
BA_ "GenMsgStartDelayTime" BO_ 2566728000 90;
BA_ "GenMsgCycleTime" BO_ 2549579584 250;
BA_ "GenMsgStartDelayTime" BO_ 2549579584 70;
BA_ "GenMsgCycleTime" BO_ 2499772480 50;
BA_ "GenMsgStartDelayTime" BO_ 2499772480 15;
BA_ "GenMsgCycleTime" BO_ 2549294912 200;
BA_ "GenMsgStartDelayTime" BO_ 2549294912 5;
BA_ "GenMsgCycleTime" BO_ 2549307200 200;
BA_ "GenMsgDelayTime" BO_ 2549307200 20;
BA_ "GenMsgStartDelayTime" BO_ 2549307200 25;
BA_ "GenMsgCycleTime" BO_ 2549326400 200;
BA_ "GenMsgDelayTime" BO_ 2549326400 20;
BA_ "GenMsgStartDelayTime" BO_ 2549326400 60;
BA_ "GenMsgCycleTime" BO_ 2566293568 500;
BA_ "GenMsgDelayTime" BO_ 2566293568 50;
BA_ "GenMsgStartDelayTime" BO_ 2566293568 25;
BA_ "GenMsgCycleTime" BO_ 2566359616 500;
BA_ "GenMsgDelayTime" BO_ 2566359616 50;
BA_ "GenMsgStartDelayTime" BO_ 2566359616 15;
BA_ "GenMsgCycleTime" BO_ 2549793856 250;
BA_ "GenMsgCycleTime" BO_ 2561225792 1000;
BA_ "GenMsgStartDelayTime" BO_ 2561225792 5;
BA_ "GenMsgCycleTime" BO_ 2566357824 1000;
BA_ "GenMsgStartDelayTime" BO_ 2566357824 705;
BA_ "GenMsgCycleTime" BO_ 2566802240 1000;
BA_ "GenMsgStartDelayTime" BO_ 2566802240 665;
BA_ "GenMsgCycleTime" BO_ 2566653760 1000;
BA_ "GenMsgStartDelayTime" BO_ 2566653760 570;
BA_ "GenMsgCycleTime" BO_ 2566579520 1000;
BA_ "GenMsgStartDelayTime" BO_ 2566579520 515;
BA_ "GenMsgCycleTime" BO_ 2566505280 1000;
BA_ "GenMsgStartDelayTime" BO_ 2566505280 450;
BA_ "GenMsgCycleTime" BO_ 2566431040 1000;
BA_ "GenMsgStartDelayTime" BO_ 2566431040 405;
BA_ "GenMsgCycleTime" BO_ 2566357568 1000;
BA_ "GenMsgStartDelayTime" BO_ 2566357568 365;
BA_ "GenMsgCycleTime" BO_ 2566282560 1000;
BA_ "GenMsgStartDelayTime" BO_ 2566282560 300;
BA_ "GenMsgCycleTime" BO_ 2566208320 1000;
BA_ "GenMsgStartDelayTime" BO_ 2566208320 270;
BA_ "GenMsgCycleTime" BO_ 2566134080 1000;
BA_ "GenMsgStartDelayTime" BO_ 2566134080 225;
BA_ "GenMsgCycleTime" BO_ 2566059840 1000;
BA_ "GenMsgStartDelayTime" BO_ 2566059840 190;
BA_ "GenMsgCycleTime" BO_ 2565985600 1000;
BA_ "GenMsgStartDelayTime" BO_ 2565985600 130;
BA_ "GenMsgCycleTime" BO_ 2565911360 1000;
BA_ "GenMsgStartDelayTime" BO_ 2565911360 85;
BA_ "GenSigCycleTime" SG_ 2466243731 CMSMenu_stat 100;
BA_ "GenSigCycleTimeActive" SG_ 2466243731 CMSMenu_stat 100;
BA_ "GenSigStartValue" SG_ 2466243731 CMSMenu_stat 7;
BA_ "GenSigCycleTime" SG_ 2466243731 CMSMirrorHeatingMode_stat 100;
BA_ "GenSigCycleTimeActive" SG_ 2466243731 CMSMirrorHeatingMode_stat 100;
BA_ "GenSigStartValue" SG_ 2466243731 CMSMirrorHeatingMode_stat 7;
BA_ "GenSigCycleTime" SG_ 2466243731 CMSDisplayButton1_stat 100;
BA_ "GenSigCycleTimeActive" SG_ 2466243731 CMSDisplayButton1_stat 100;
BA_ "GenSigStartValue" SG_ 2466243731 CMSDisplayButton1_stat 3;
BA_ "GenSigCycleTime" SG_ 2466243731 CMSElectricalFOV_stat 100;
BA_ "GenSigCycleTimeActive" SG_ 2466243731 CMSElectricalFOV_stat 100;
BA_ "GenSigStartValue" SG_ 2466243731 CMSElectricalFOV_stat 7;
BA_ "GenSigCycleTime" SG_ 2466243731 CMSPanning_stat 100;
BA_ "GenSigCycleTimeActive" SG_ 2466243731 CMSPanning_stat 100;
BA_ "GenSigStartValue" SG_ 2466243731 CMSPanning_stat 7;
BA_ "GenSigCycleTime" SG_ 2466243731 CMSEnhancedNightVision_stat 100;
BA_ "GenSigCycleTimeActive" SG_ 2466243731 CMSEnhancedNightVision_stat 100;
BA_ "GenSigStartValue" SG_ 2466243731 CMSEnhancedNightVision_stat 3;
BA_ "GenSigCycleTime" SG_ 2466243731 DistanceLines_stat 100;
BA_ "GenSigCycleTimeActive" SG_ 2466243731 DistanceLines_stat 100;
BA_ "GenSigStartValue" SG_ 2466243731 DistanceLines_stat 7;
BA_ "GenSigCycleTime" SG_ 2466243731 CMSLCSWarningLeftStatus_stat 100;
BA_ "GenSigCycleTimeActive" SG_ 2466243731 CMSLCSWarningLeftStatus_stat 100;
BA_ "GenSigStartValue" SG_ 2466243731 CMSLCSWarningLeftStatus_stat 7;
BA_ "GenSigCycleTime" SG_ 2466243731 CMSEOVLine_stat 100;
BA_ "GenSigCycleTimeActive" SG_ 2466243731 CMSEOVLine_stat 100;
BA_ "GenSigStartValue" SG_ 2466243731 CMSEOVLine_stat 7;
BA_ "GenSigCycleTime" SG_ 2466243731 FixedReversePanOutView_stat 100;
BA_ "GenSigCycleTimeActive" SG_ 2466243731 FixedReversePanOutView_stat 100;
BA_ "GenSigStartValue" SG_ 2466243731 FixedReversePanOutView_stat 7;
BA_ "GenSigCycleTime" SG_ 2466243731 CMSFoldingMenuFeedback_stat 100;
BA_ "GenSigCycleTimeActive" SG_ 2466243731 CMSFoldingMenuFeedback_stat 100;
BA_ "GenSigStartValue" SG_ 2466243731 CMSFoldingMenuFeedback_stat 7;
BA_ "GenSigCycleTime" SG_ 2466243731 CMSAutoBrightnessAdj_stat 100;
BA_ "GenSigCycleTimeActive" SG_ 2466243731 CMSAutoBrightnessAdj_stat 100;
BA_ "GenSigStartValue" SG_ 2466243731 CMSAutoBrightnessAdj_stat 3;
BA_ "GenSigCycleTime" SG_ 2466243731 CMSClassVActDeact_stat 100;
BA_ "GenSigCycleTimeActive" SG_ 2466243731 CMSClassVActDeact_stat 100;
BA_ "GenSigStartValue" SG_ 2466243731 CMSClassVActDeact_stat 7;
BA_ "GenSigCycleTime" SG_ 2466243731 CMSLCSWarningRightStatus_stat 100;
BA_ "GenSigCycleTimeActive" SG_ 2466243731 CMSLCSWarningRightStatus_stat 100;
BA_ "GenSigStartValue" SG_ 2466243731 CMSLCSWarningRightStatus_stat 7;
BA_ "GenSigCycleTime" SG_ 2495165760 CMSManualActDeactRqst_Request 100;
BA_ "GenSigCycleTimeActive" SG_ 2495165760 CMSManualActDeactRqst_Request 100;
BA_ "GenSigStartValue" SG_ 2495165760 CMSManualActDeactRqst_Request 3;
BA_ "GenSigCycleTime" SG_ 2495165760 CMSFoldingRqst_CRC 100;
BA_ "GenSigCycleTimeActive" SG_ 2495165760 CMSFoldingRqst_CRC 100;
BA_ "E2EDataId" SG_ 2495165760 CMSFoldingRqst_CRC 312;
BA_ "E2EDataLength" SG_ 2495165760 CMSFoldingRqst_CRC 16;
BA_ "E2EProfile" SG_ 2495165760 CMSFoldingRqst_CRC "P01";
BA_ "GenSigCycleTime" SG_ 2495165760 CMSManualAlignmRqst_SqC 100;
BA_ "GenSigCycleTimeActive" SG_ 2495165760 CMSManualAlignmRqst_SqC 100;
BA_ "GenSigCycleTime" SG_ 2495165760 CMSZoomRqst_SqC 100;
BA_ "GenSigCycleTimeActive" SG_ 2495165760 CMSZoomRqst_SqC 100;
BA_ "GenSigCycleTime" SG_ 2495165760 CMSZoomRqst_Request 100;
BA_ "GenSigCycleTimeActive" SG_ 2495165760 CMSZoomRqst_Request 100;
BA_ "GenSigStartValue" SG_ 2495165760 CMSZoomRqst_Request 3;
BA_ "GenSigCycleTime" SG_ 2495165760 CMSManualActDeactRqst_SqC 100;
BA_ "GenSigCycleTimeActive" SG_ 2495165760 CMSManualActDeactRqst_SqC 100;
BA_ "GenSigCycleTime" SG_ 2495165760 CMSFoldingRqst_Request 100;
BA_ "GenSigCycleTimeActive" SG_ 2495165760 CMSFoldingRqst_Request 100;
BA_ "GenSigStartValue" SG_ 2495165760 CMSFoldingRqst_Request 7;
BA_ "GenSigCycleTime" SG_ 2495165760 CMSZoomRqst_CRC 100;
BA_ "GenSigCycleTimeActive" SG_ 2495165760 CMSZoomRqst_CRC 100;
BA_ "E2EDataId" SG_ 2495165760 CMSZoomRqst_CRC 311;
BA_ "E2EDataLength" SG_ 2495165760 CMSZoomRqst_CRC 16;
BA_ "E2EProfile" SG_ 2495165760 CMSZoomRqst_CRC "P01";
BA_ "GenSigCycleTime" SG_ 2495165760 CMSManualAlignmRqst_CRC 100;
BA_ "GenSigCycleTimeActive" SG_ 2495165760 CMSManualAlignmRqst_CRC 100;
BA_ "E2EDataId" SG_ 2495165760 CMSManualAlignmRqst_CRC 317;
BA_ "E2EDataLength" SG_ 2495165760 CMSManualAlignmRqst_CRC 16;
BA_ "E2EProfile" SG_ 2495165760 CMSManualAlignmRqst_CRC "P01";
BA_ "GenSigCycleTime" SG_ 2495165760 CMSManualActDeactRqst_CRC 100;
BA_ "GenSigCycleTimeActive" SG_ 2495165760 CMSManualActDeactRqst_CRC 100;
BA_ "E2EDataId" SG_ 2495165760 CMSManualActDeactRqst_CRC 319;
BA_ "E2EDataLength" SG_ 2495165760 CMSManualActDeactRqst_CRC 16;
BA_ "E2EProfile" SG_ 2495165760 CMSManualActDeactRqst_CRC "P01";
BA_ "GenSigCycleTime" SG_ 2495165760 CMSManualAlignmRqst_Request 100;
BA_ "GenSigCycleTimeActive" SG_ 2495165760 CMSManualAlignmRqst_Request 100;
BA_ "GenSigStartValue" SG_ 2495165760 CMSManualAlignmRqst_Request 7;
BA_ "GenSigCycleTime" SG_ 2495165760 CMSFoldingRqst_SqC 100;
BA_ "GenSigCycleTimeActive" SG_ 2495165760 CMSFoldingRqst_SqC 100;
BA_ "GenSigCycleTime" SG_ 2510689088 CMSEnhancedNightVision_rqst 100;
BA_ "GenSigCycleTimeActive" SG_ 2510689088 CMSEnhancedNightVision_rqst 100;
BA_ "GenSigStartValue" SG_ 2510689088 CMSEnhancedNightVision_rqst 3;
BA_ "GenSigCycleTime" SG_ 2510689088 AmbientLight_stat 100;
BA_ "GenSigCycleTimeActive" SG_ 2510689088 AmbientLight_stat 100;
BA_ "GenSigStartValue" SG_ 2510689088 AmbientLight_stat 65535;
BA_ "GenSigMaxLatency" SG_ 2510689088 AmbientLight_stat 100;
BA_ "GenSigCycleTime" SG_ 2510689088 CMSMenu_rqst 100;
BA_ "GenSigCycleTimeActive" SG_ 2510689088 CMSMenu_rqst 100;
BA_ "GenSigStartValue" SG_ 2510689088 CMSMenu_rqst 7;
BA_ "GenSigCycleTime" SG_ 2510689088 PanicAlarm_rqst 100;
BA_ "GenSigCycleTimeActive" SG_ 2510689088 PanicAlarm_rqst 100;
BA_ "GenSigStartValue" SG_ 2510689088 PanicAlarm_rqst 7;
BA_ "GenSigMaxLatency" SG_ 2510689088 PanicAlarm_rqst 100;
BA_ "GenSigCycleTime" SG_ 2510689088 DoorsAjar_stat 100;
BA_ "GenSigCycleTimeActive" SG_ 2510689088 DoorsAjar_stat 100;
BA_ "GenSigStartValue" SG_ 2510689088 DoorsAjar_stat 7;
BA_ "GenSigMaxLatency" SG_ 2510689088 DoorsAjar_stat 100;
BA_ "GenSigCycleTime" SG_ 2510689088 CMSNavigation_rqst 100;
BA_ "GenSigCycleTimeActive" SG_ 2510689088 CMSNavigation_rqst 100;
BA_ "GenSigStartValue" SG_ 2510689088 CMSNavigation_rqst 7;
BA_ "GenSigCycleTime" SG_ 2510689088 TrailerConnected 100;
BA_ "GenSigCycleTimeActive" SG_ 2510689088 TrailerConnected 100;
BA_ "GenSigStartValue" SG_ 2510689088 TrailerConnected 3;
BA_ "GenSigMaxLatency" SG_ 2510689088 TrailerConnected 100;
BA_ "GenSigCycleTime" SG_ 2510689088 CMSAutoBrightnessAdj_rqst 100;
BA_ "GenSigCycleTimeActive" SG_ 2510689088 CMSAutoBrightnessAdj_rqst 100;
BA_ "GenSigStartValue" SG_ 2510689088 CMSAutoBrightnessAdj_rqst 3;
BA_ "GenSigCycleTime" SG_ 2510689088 FixedReversePanOutView_rqst 100;
BA_ "GenSigCycleTimeActive" SG_ 2510689088 FixedReversePanOutView_rqst 100;
BA_ "GenSigStartValue" SG_ 2510689088 FixedReversePanOutView_rqst 7;
BA_ "GenSigCycleTime" SG_ 2510689088 CMSSelectedLanguage_stat 100;
BA_ "GenSigCycleTimeActive" SG_ 2510689088 CMSSelectedLanguage_stat 100;
BA_ "GenSigStartValue" SG_ 2510689088 CMSSelectedLanguage_stat 63;
BA_ "GenSigCycleTime" SG_ 2510689088 CMSMirrorHeat_rqst 100;
BA_ "GenSigCycleTimeActive" SG_ 2510689088 CMSMirrorHeat_rqst 100;
BA_ "GenSigStartValue" SG_ 2510689088 CMSMirrorHeat_rqst 7;
BA_ "GenSigMaxLatency" SG_ 2510689088 CMSMirrorHeat_rqst 100;
BA_ "GenSigCycleTime" SG_ 2510689088 PS_BunkFanSpeedStatus 100;
BA_ "GenSigCycleTimeActive" SG_ 2510689088 PS_BunkFanSpeedStatus 100;
BA_ "GenSigStartValue" SG_ 2510689088 PS_BunkFanSpeedStatus 15;
BA_ "GenSigCycleTime" SG_ 2510689088 TransmissionCurrentGear 100;
BA_ "GenSigCycleTimeActive" SG_ 2510689088 TransmissionCurrentGear 100;
BA_ "GenSigStartValue" SG_ 2510689088 TransmissionCurrentGear 255;
BA_ "GenSigMaxLatency" SG_ 2510689088 TransmissionCurrentGear 100;
BA_ "SeToolAncestorID_SIGNAL" SG_ 2510689088 TransmissionCurrentGear "x0000001D0412E700";
BA_ "SeToolItemID_SIGNAL" SG_ 2510689088 TransmissionCurrentGear "x0000001D0412E700";
BA_ "SeToolName_SIGNAL" SG_ 2510689088 TransmissionCurrentGear "TransmissionCurrentGear";
BA_ "SeToolVersion_SIGNAL" SG_ 2510689088 TransmissionCurrentGear "1";
BA_ "GenSigCycleTime" SG_ 2510689088 PS_CMS_Status 100;
BA_ "GenSigCycleTimeActive" SG_ 2510689088 PS_CMS_Status 100;
BA_ "GenSigStartValue" SG_ 2510689088 PS_CMS_Status 3;
BA_ "GenSigCycleTime" SG_ 2510689088 AlarmStatus_stat 100;
BA_ "GenSigCycleTimeActive" SG_ 2510689088 AlarmStatus_stat 100;
BA_ "GenSigStartValue" SG_ 2510689088 AlarmStatus_stat 15;
BA_ "GenSigMaxLatency" SG_ 2510689088 AlarmStatus_stat 100;
BA_ "GenSigSendType" SG_ 2566730048 BunkACRequest 3;
BA_ "GenSigStartValue" SG_ 2566730048 BunkACRequest 3;
BA_ "GenSigSendType" SG_ 2566730048 ClimateAirDistRequest_Vent 3;
BA_ "GenSigStartValue" SG_ 2566730048 ClimateAirDistRequest_Vent 15;
BA_ "GenSigCycleTime" SG_ 2566730048 OpLevelItem3 100;
BA_ "GenSigCycleTimeActive" SG_ 2566730048 OpLevelItem3 100;
BA_ "GenSigStartValue" SG_ 2566730048 OpLevelItem3 255;
BA_ "GenSigSendType" SG_ 2566730048 AirRecirculationRequest 3;
BA_ "GenSigStartValue" SG_ 2566730048 AirRecirculationRequest 3;
BA_ "GenSigSendType" SG_ 2566730048 MaxDefrostRequest 3;
BA_ "GenSigStartValue" SG_ 2566730048 MaxDefrostRequest 3;
BA_ "GenSigSendType" SG_ 2566730048 CabTempRequest 3;
BA_ "GenSigStartValue" SG_ 2566730048 CabTempRequest 127;
BA_ "GenSigSendType" SG_ 2566730048 HVACBlowerRequest 3;
BA_ "GenSigStartValue" SG_ 2566730048 HVACBlowerRequest 31;
BA_ "GenSigSendType" SG_ 2566730048 ClimateAirDistRequest_Defrost 3;
BA_ "GenSigStartValue" SG_ 2566730048 ClimateAirDistRequest_Defrost 15;
BA_ "GenSigCycleTime" SG_ 2566730048 BunkParkClimateRequest 100;
BA_ "GenSigCycleTimeActive" SG_ 2566730048 BunkParkClimateRequest 100;
BA_ "GenSigStartValue" SG_ 2566730048 BunkParkClimateRequest 3;
BA_ "GenSigSendType" SG_ 2566730048 ParkingClimateRequest 3;
BA_ "GenSigStartValue" SG_ 2566730048 ParkingClimateRequest 3;
BA_ "GenSigSendType" SG_ 2566730048 BunkClimatePowerRequest 3;
BA_ "GenSigStartValue" SG_ 2566730048 BunkClimatePowerRequest 3;
BA_ "GenSigSendType" SG_ 2566730048 BunkClimateAutoRequest 3;
BA_ "GenSigStartValue" SG_ 2566730048 BunkClimateAutoRequest 3;
BA_ "GenSigSendType" SG_ 2566730048 ClimatePowerRequest 3;
BA_ "GenSigStartValue" SG_ 2566730048 ClimatePowerRequest 3;
BA_ "GenSigSendType" SG_ 2566730048 ClimateAirDistRequest_Floor 3;
BA_ "GenSigStartValue" SG_ 2566730048 ClimateAirDistRequest_Floor 15;
BA_ "GenSigSendType" SG_ 2566730048 BunkHVACBlowerRequest 3;
BA_ "GenSigStartValue" SG_ 2566730048 BunkHVACBlowerRequest 31;
BA_ "GenSigSendType" SG_ 2566730048 BunkTempRequest 3;
BA_ "GenSigStartValue" SG_ 2566730048 BunkTempRequest 127;
BA_ "GenSigSendType" SG_ 2566730048 ClimateAutoRequest 3;
BA_ "GenSigStartValue" SG_ 2566730048 ClimateAutoRequest 3;
BA_ "GenSigSendType" SG_ 2566730048 ACRequest 3;
BA_ "GenSigStartValue" SG_ 2566730048 ACRequest 3;
BA_ "GenSigCycleTime" SG_ 2566728000 SelectedSpeedUnit_stat 100;
BA_ "GenSigCycleTimeActive" SG_ 2566728000 SelectedSpeedUnit_stat 100;
BA_ "GenSigStartValue" SG_ 2566728000 SelectedSpeedUnit_stat 3;
BA_ "GenSigMaxLatency" SG_ 2566728000 SelectedSpeedUnit_stat 500;
BA_ "GenSigCycleTime" SG_ 2566728000 PV_LivingBatteryCrankReserve 100;
BA_ "GenSigCycleTimeActive" SG_ 2566728000 PV_LivingBatteryCrankReserve 100;
BA_ "GenSigStartValue" SG_ 2566728000 PV_LivingBatteryCrankReserve 255;
BA_ "GenSigMaxLatency" SG_ 2566728000 PV_LivingBatteryCrankReserve 500;
BA_ "GenSigCycleTime" SG_ 2566728000 SelectedDistanceUnit_stat 100;
BA_ "GenSigCycleTimeActive" SG_ 2566728000 SelectedDistanceUnit_stat 100;
BA_ "GenSigStartValue" SG_ 2566728000 SelectedDistanceUnit_stat 3;
BA_ "GenSigMaxLatency" SG_ 2566728000 SelectedDistanceUnit_stat 500;
BA_ "GenSigCycleTime" SG_ 2566728000 PV_LivingBatteryMaxCapacity 100;
BA_ "GenSigCycleTimeActive" SG_ 2566728000 PV_LivingBatteryMaxCapacity 100;
BA_ "GenSigStartValue" SG_ 2566728000 PV_LivingBatteryMaxCapacity 255;
BA_ "GenSigMaxLatency" SG_ 2566728000 PV_LivingBatteryMaxCapacity 500;
BA_ "GenSigCycleTime" SG_ 2566728000 SelectedPressureUnit_stat 100;
BA_ "GenSigCycleTimeActive" SG_ 2566728000 SelectedPressureUnit_stat 100;
BA_ "GenSigStartValue" SG_ 2566728000 SelectedPressureUnit_stat 7;
BA_ "GenSigMaxLatency" SG_ 2566728000 SelectedPressureUnit_stat 500;
BA_ "GenSigCycleTime" SG_ 2566728000 PV_AmbientAirTemp 100;
BA_ "GenSigCycleTimeActive" SG_ 2566728000 PV_AmbientAirTemp 100;
BA_ "GenSigStartValue" SG_ 2566728000 PV_AmbientAirTemp 65535;
BA_ "GenSigMaxLatency" SG_ 2566728000 PV_AmbientAirTemp 500;
BA_ "GenSigCycleTime" SG_ 2566728000 SelectedLangUnrestricted_stat 100;
BA_ "GenSigCycleTimeActive" SG_ 2566728000 SelectedLangUnrestricted_stat 100;
BA_ "GenSigStartValue" SG_ 2566728000 SelectedLangUnrestricted_stat 63;
BA_ "GenSigMaxLatency" SG_ 2566728000 SelectedLangUnrestricted_stat 500;
BA_ "GenSigCycleTime" SG_ 2566728000 SelectedVolumeUnit_stat 100;
BA_ "GenSigCycleTimeActive" SG_ 2566728000 SelectedVolumeUnit_stat 100;
BA_ "GenSigStartValue" SG_ 2566728000 SelectedVolumeUnit_stat 7;
BA_ "GenSigMaxLatency" SG_ 2566728000 SelectedVolumeUnit_stat 500;
BA_ "GenSigCycleTime" SG_ 2566728000 SelectedFuelConsumptUnit_stat 100;
BA_ "GenSigCycleTimeActive" SG_ 2566728000 SelectedFuelConsumptUnit_stat 100;
BA_ "GenSigStartValue" SG_ 2566728000 SelectedFuelConsumptUnit_stat 7;
BA_ "GenSigMaxLatency" SG_ 2566728000 SelectedFuelConsumptUnit_stat 500;
BA_ "GenSigCycleTime" SG_ 2566728000 SelectedTemperatureUnit_stat 100;
BA_ "GenSigCycleTimeActive" SG_ 2566728000 SelectedTemperatureUnit_stat 100;
BA_ "GenSigStartValue" SG_ 2566728000 SelectedTemperatureUnit_stat 3;
BA_ "GenSigMaxLatency" SG_ 2566728000 SelectedTemperatureUnit_stat 500;
BA_ "GenSigCycleTime" SG_ 2566728000 PV_LivingBatterySOC 100;
BA_ "GenSigCycleTimeActive" SG_ 2566728000 PV_LivingBatterySOC 100;
BA_ "GenSigStartValue" SG_ 2566728000 PV_LivingBatterySOC 255;
BA_ "GenSigMaxLatency" SG_ 2566728000 PV_LivingBatterySOC 500;
BA_ "GenSigCycleTime" SG_ 2549579584 PS_AutoLoadCutOffState 100;
BA_ "GenSigCycleTimeActive" SG_ 2549579584 PS_AutoLoadCutOffState 100;
BA_ "GenSigStartValue" SG_ 2549579584 PS_AutoLoadCutOffState 7;
BA_ "GenSigCycleTime" SG_ 2549579584 PS_LivingBatterySOCWarning 100;
BA_ "GenSigCycleTimeActive" SG_ 2549579584 PS_LivingBatterySOCWarning 100;
BA_ "GenSigStartValue" SG_ 2549579584 PS_LivingBatterySOCWarning 7;
BA_ "GenSigCycleTime" SG_ 2549579584 PV_AlarmClockNotific_Type 100;
BA_ "GenSigCycleTimeActive" SG_ 2549579584 PV_AlarmClockNotific_Type 100;
BA_ "GenSigStartValue" SG_ 2549579584 PV_AlarmClockNotific_Type 7;
BA_ "GenSigMaxLatency" SG_ 2549579584 PV_AlarmClockNotific_Type 250;
BA_ "GenSigCycleTime" SG_ 2549579584 PV_AlarmClockNotific_ID 100;
BA_ "GenSigCycleTimeActive" SG_ 2549579584 PV_AlarmClockNotific_ID 100;
BA_ "GenSigStartValue" SG_ 2549579584 PV_AlarmClockNotific_ID 127;
BA_ "GenSigMaxLatency" SG_ 2549579584 PV_AlarmClockNotific_ID 250;
BA_ "GenSigCycleTime" SG_ 2549579584 PS_AutoLoadCutOff 100;
BA_ "GenSigCycleTimeActive" SG_ 2549579584 PS_AutoLoadCutOff 100;
BA_ "GenSigStartValue" SG_ 2549579584 PS_AutoLoadCutOff 3;
BA_ "GenSigCycleTime" SG_ 2549579584 PS_LivingBatteryTempWarning 100;
BA_ "GenSigCycleTimeActive" SG_ 2549579584 PS_LivingBatteryTempWarning 100;
BA_ "GenSigStartValue" SG_ 2549579584 PS_LivingBatteryTempWarning 7;
BA_ "GenSigCycleTime" SG_ 2549579584 PV_AlarmClockNotific_Stat 100;
BA_ "GenSigCycleTimeActive" SG_ 2549579584 PV_AlarmClockNotific_Stat 100;
BA_ "GenSigMaxLatency" SG_ 2549579584 PV_AlarmClockNotific_Stat 250;
BA_ "GenSigCycleTime" SG_ 2499772480 SlprMaxLightIntensity_Cmd 100;
BA_ "GenSigCycleTimeActive" SG_ 2499772480 SlprMaxLightIntensity_Cmd 100;
BA_ "GenSigStartValue" SG_ 2499772480 SlprMaxLightIntensity_Cmd 255;
BA_ "GenSigMaxLatency" SG_ 2499772480 SlprMaxLightIntensity_Cmd 50;
BA_ "GenSigCycleTime" SG_ 2499772480 CoolantTempEM 100;
BA_ "GenSigCycleTimeActive" SG_ 2499772480 CoolantTempEM 100;
BA_ "GenSigStartValue" SG_ 2499772480 CoolantTempEM 1023;
BA_ "GenSigCycleTime" SG_ 2499772480 BlackOutandConvoyMode_rqst 100;
BA_ "GenSigCycleTimeActive" SG_ 2499772480 BlackOutandConvoyMode_rqst 100;
BA_ "GenSigStartValue" SG_ 2499772480 BlackOutandConvoyMode_rqst 7;
BA_ "GenSigMaxLatency" SG_ 2499772480 BlackOutandConvoyMode_rqst 50;
BA_ "GenSigCycleTime" SG_ 2499772480 ChillerInClntTmp 100;
BA_ "GenSigCycleTimeActive" SG_ 2499772480 ChillerInClntTmp 100;
BA_ "GenSigStartValue" SG_ 2499772480 ChillerInClntTmp 511;
BA_ "GenSigCycleTime" SG_ 2499772480 ChillerPumpFault 100;
BA_ "GenSigCycleTimeActive" SG_ 2499772480 ChillerPumpFault 100;
BA_ "GenSigStartValue" SG_ 2499772480 ChillerPumpFault 7;
BA_ "GenSigCycleTime" SG_ 2499772480 SlprLwrAmbLightIntensity_Cmd 100;
BA_ "GenSigCycleTimeActive" SG_ 2499772480 SlprLwrAmbLightIntensity_Cmd 100;
BA_ "GenSigStartValue" SG_ 2499772480 SlprLwrAmbLightIntensity_Cmd 255;
BA_ "GenSigMaxLatency" SG_ 2499772480 SlprLwrAmbLightIntensity_Cmd 50;
BA_ "GenSigCycleTime" SG_ 2499772480 LECM_BunkPanicInd_cmd 100;
BA_ "GenSigCycleTimeActive" SG_ 2499772480 LECM_BunkPanicInd_cmd 100;
BA_ "GenSigStartValue" SG_ 2499772480 LECM_BunkPanicInd_cmd 3;
BA_ "GenSigMaxLatency" SG_ 2499772480 LECM_BunkPanicInd_cmd 50;
BA_ "GenSigCycleTime" SG_ 2499772480 SlprUprAmbLightIntensity_Cmd 100;
BA_ "GenSigCycleTimeActive" SG_ 2499772480 SlprUprAmbLightIntensity_Cmd 100;
BA_ "GenSigStartValue" SG_ 2499772480 SlprUprAmbLightIntensity_Cmd 255;
BA_ "GenSigMaxLatency" SG_ 2499772480 SlprUprAmbLightIntensity_Cmd 50;
BA_ "GenSigCycleTime" SG_ 2499772480 AuxFunCabPrecondition_Rqst 100;
BA_ "GenSigCycleTimeActive" SG_ 2499772480 AuxFunCabPrecondition_Rqst 100;
BA_ "GenSigStartValue" SG_ 2499772480 AuxFunCabPrecondition_Rqst 7;
BA_ "GenSigCycleTime" SG_ 2549294912 PS_InverterOverTemp 100;
BA_ "GenSigCycleTimeActive" SG_ 2549294912 PS_InverterOverTemp 100;
BA_ "GenSigStartValue" SG_ 2549294912 PS_InverterOverTemp 3;
BA_ "GenSigCycleTime" SG_ 2549294912 FuelLevel_UB 100;
BA_ "GenSigCycleTimeActive" SG_ 2549294912 FuelLevel_UB 100;
BA_ "GenSigCycleTime" SG_ 2549294912 PS_InverterOverVoltage 100;
BA_ "GenSigCycleTimeActive" SG_ 2549294912 PS_InverterOverVoltage 100;
BA_ "GenSigStartValue" SG_ 2549294912 PS_InverterOverVoltage 3;
BA_ "GenSigCycleTime" SG_ 2549294912 PS_MaxDefrostStatus 100;
BA_ "GenSigCycleTimeActive" SG_ 2549294912 PS_MaxDefrostStatus 100;
BA_ "GenSigStartValue" SG_ 2549294912 PS_MaxDefrostStatus 3;
BA_ "GenSigCycleTime" SG_ 2549294912 PS_ParkingClimateReqDenied 100;
BA_ "GenSigCycleTimeActive" SG_ 2549294912 PS_ParkingClimateReqDenied 100;
BA_ "GenSigStartValue" SG_ 2549294912 PS_ParkingClimateReqDenied 3;
BA_ "GenSigCycleTime" SG_ 2549294912 FuelVolume_UB 100;
BA_ "GenSigCycleTimeActive" SG_ 2549294912 FuelVolume_UB 100;
BA_ "GenSigCycleTime" SG_ 2549294912 PS_InverterOutputMode 100;
BA_ "GenSigCycleTimeActive" SG_ 2549294912 PS_InverterOutputMode 100;
BA_ "GenSigStartValue" SG_ 2549294912 PS_InverterOutputMode 3;
BA_ "GenSigCycleTime" SG_ 2549294912 PV_InverterPowerOutput 100;
BA_ "GenSigCycleTimeActive" SG_ 2549294912 PV_InverterPowerOutput 100;
BA_ "GenSigStartValue" SG_ 2549294912 PV_InverterPowerOutput 255;
BA_ "GenSigCycleTime" SG_ 2549294912 PV_InverterShoreVoltage 100;
BA_ "GenSigCycleTimeActive" SG_ 2549294912 PV_InverterShoreVoltage 100;
BA_ "GenSigStartValue" SG_ 2549294912 PV_InverterShoreVoltage 1023;
BA_ "GenSigCycleTime" SG_ 2549294912 PS_InverterShorePower 100;
BA_ "GenSigCycleTimeActive" SG_ 2549294912 PS_InverterShorePower 100;
BA_ "GenSigStartValue" SG_ 2549294912 PS_InverterShorePower 3;
BA_ "GenSigCycleTime" SG_ 2549294912 FuelVolume 100;
BA_ "GenSigCycleTimeActive" SG_ 2549294912 FuelVolume 100;
BA_ "GenSigStartValue" SG_ 2549294912 FuelVolume 2047;
BA_ "GenSigCycleTime" SG_ 2549294912 FuelLevel 100;
BA_ "GenSigCycleTimeActive" SG_ 2549294912 FuelLevel 100;
BA_ "GenSigStartValue" SG_ 2549294912 FuelLevel 255;
BA_ "SeToolAncestorID_SIGNAL" SG_ 2549294912 FuelLevel "x0000001D0416974D";
BA_ "SeToolItemID_SIGNAL" SG_ 2549294912 FuelLevel "x0000001D0416974D";
BA_ "SeToolName_SIGNAL" SG_ 2549294912 FuelLevel "FuelLevel";
BA_ "SeToolVersion_SIGNAL" SG_ 2549294912 FuelLevel "1";
BA_ "GenSigCycleTime" SG_ 2549294912 PS_InverterOverload 100;
BA_ "GenSigCycleTimeActive" SG_ 2549294912 PS_InverterOverload 100;
BA_ "GenSigStartValue" SG_ 2549294912 PS_InverterOverload 3;
BA_ "GenSigSendType" SG_ 2549307200 PSACModeStatus 3;
BA_ "GenSigStartValue" SG_ 2549307200 PSACModeStatus 7;
BA_ "GenSigSendType" SG_ 2549307200 PS_FrontFanSpeedStatus 3;
BA_ "GenSigStartValue" SG_ 2549307200 PS_FrontFanSpeedStatus 15;
BA_ "GenSigCycleTime" SG_ 2549307200 PS_FrontACStatus 100;
BA_ "GenSigCycleTimeActive" SG_ 2549307200 PS_FrontACStatus 100;
BA_ "GenSigStartValue" SG_ 2549307200 PS_FrontACStatus 3;
BA_ "GenSigSendType" SG_ 2549307200 PS_BunkPowerStatus 3;
BA_ "GenSigStartValue" SG_ 2549307200 PS_BunkPowerStatus 3;
BA_ "GenSigSendType" SG_ 2549307200 PS_BunkACStatus 3;
BA_ "GenSigStartValue" SG_ 2549307200 PS_BunkACStatus 3;
BA_ "GenSigSendType" SG_ 2549307200 PV_FrontTemperatureStatus 3;
BA_ "GenSigStartValue" SG_ 2549307200 PV_FrontTemperatureStatus 31;
BA_ "GenSigSendType" SG_ 2549307200 PS_AutoModeStatus 3;
BA_ "GenSigStartValue" SG_ 2549307200 PS_AutoModeStatus 3;
BA_ "GenSigSendType" SG_ 2549307200 PS_BunkSyncStatus 3;
BA_ "GenSigStartValue" SG_ 2549307200 PS_BunkSyncStatus 3;
BA_ "GenSigSendType" SG_ 2549307200 PS_FrontHVACPowerStatus 3;
BA_ "GenSigStartValue" SG_ 2549307200 PS_FrontHVACPowerStatus 3;
BA_ "GenSigSendType" SG_ 2549307200 PS_ParkingClimateStatus 3;
BA_ "GenSigStartValue" SG_ 2549307200 PS_ParkingClimateStatus 3;
BA_ "GenSigSendType" SG_ 2549307200 PS_FrontSyncStatus 3;
BA_ "GenSigStartValue" SG_ 2549307200 PS_FrontSyncStatus 3;
BA_ "GenSigSendType" SG_ 2549307200 PS_BunkAutoStatus 3;
BA_ "GenSigStartValue" SG_ 2549307200 PS_BunkAutoStatus 3;
BA_ "GenSigSendType" SG_ 2549307200 PS_DoorLockStatusTimed 3;
BA_ "GenSigStartValue" SG_ 2549307200 PS_DoorLockStatusTimed 3;
BA_ "GenSigSendType" SG_ 2549307200 PV_BunkTemperatureStatus 3;
BA_ "GenSigStartValue" SG_ 2549307200 PV_BunkTemperatureStatus 31;
BA_ "GenSigSendType" SG_ 2549326400 PV_EntAudioLevels_Type 3;
BA_ "GenSigStartValue" SG_ 2549326400 PV_EntAudioLevels_Type 15;
BA_ "GenSigSendType" SG_ 2549326400 PS_EntAudioSourceStat 3;
BA_ "GenSigStartValue" SG_ 2549326400 PS_EntAudioSourceStat 63;
BA_ "GenSigSendType" SG_ 2549326400 PV_EntRadioFreq 3;
BA_ "GenSigStartValue" SG_ 2549326400 PV_EntRadioFreq 4294967295;
BA_ "GenSigSendType" SG_ 2549326400 PV_EntAudioLevels_Level 3;
BA_ "GenSigStartValue" SG_ 2549326400 PV_EntAudioLevels_Level 255;
BA_ "GenSigSendType" SG_ 2549326400 PS_EntBunkSilentSts 3;
BA_ "GenSigStartValue" SG_ 2549326400 PS_EntBunkSilentSts 3;
BA_ "GenSigSendType" SG_ 2549326400 PS_EntChannelNo 3;
BA_ "GenSigStartValue" SG_ 2549326400 PS_EntChannelNo 1023;
BA_ "GenSigSendType" SG_ 2566293568 PSPClimTimStatus_Tue 3;
BA_ "GenSigMaxLatency" SG_ 2566293568 PSPClimTimStatus_Tue 1010;
BA_ "GenSigSendType" SG_ 2566293568 PSPClimTimStatus_Min 3;
BA_ "GenSigStartValue" SG_ 2566293568 PSPClimTimStatus_Min 255;
BA_ "GenSigMaxLatency" SG_ 2566293568 PSPClimTimStatus_Min 1010;
BA_ "GenSigSendType" SG_ 2566293568 PSPClimTimStatus_TotalNoTimers 3;
BA_ "GenSigStartValue" SG_ 2566293568 PSPClimTimStatus_TotalNoTimers 255;
BA_ "GenSigMaxLatency" SG_ 2566293568 PSPClimTimStatus_TotalNoTimers 1010;
BA_ "GenSigSendType" SG_ 2566293568 PSPClimTimStatus_TimerNr 3;
BA_ "GenSigStartValue" SG_ 2566293568 PSPClimTimStatus_TimerNr 255;
BA_ "GenSigMaxLatency" SG_ 2566293568 PSPClimTimStatus_TimerNr 1010;
BA_ "GenSigSendType" SG_ 2566293568 PSPClimTimStatus_Rec 3;
BA_ "GenSigMaxLatency" SG_ 2566293568 PSPClimTimStatus_Rec 1010;
BA_ "GenSigSendType" SG_ 2566293568 PSPClimTimStatus_Status 3;
BA_ "GenSigStartValue" SG_ 2566293568 PSPClimTimStatus_Status 3;
BA_ "GenSigMaxLatency" SG_ 2566293568 PSPClimTimStatus_Status 1010;
BA_ "GenSigSendType" SG_ 2566293568 PSPClimTimStatus_Dur 3;
BA_ "GenSigStartValue" SG_ 2566293568 PSPClimTimStatus_Dur 127;
BA_ "GenSigMaxLatency" SG_ 2566293568 PSPClimTimStatus_Dur 1010;
BA_ "GenSigSendType" SG_ 2566293568 PSPClimTimStatus_Type 3;
BA_ "GenSigStartValue" SG_ 2566293568 PSPClimTimStatus_Type 7;
BA_ "GenSigMaxLatency" SG_ 2566293568 PSPClimTimStatus_Type 1010;
BA_ "GenSigSendType" SG_ 2566293568 PSPClimTimStatus_Wed 3;
BA_ "GenSigMaxLatency" SG_ 2566293568 PSPClimTimStatus_Wed 1010;
BA_ "GenSigSendType" SG_ 2566293568 PSPClimTimStatus_Fri 3;
BA_ "GenSigMaxLatency" SG_ 2566293568 PSPClimTimStatus_Fri 1010;
BA_ "GenSigSendType" SG_ 2566293568 PSPClimTimStatus_Thu 3;
BA_ "GenSigMaxLatency" SG_ 2566293568 PSPClimTimStatus_Thu 1010;
BA_ "GenSigSendType" SG_ 2566293568 PSPClimTimStatus_Sat 3;
BA_ "GenSigMaxLatency" SG_ 2566293568 PSPClimTimStatus_Sat 1010;
BA_ "GenSigSendType" SG_ 2566293568 PSPClimTimStatus_Hrs 3;
BA_ "GenSigStartValue" SG_ 2566293568 PSPClimTimStatus_Hrs 255;
BA_ "GenSigMaxLatency" SG_ 2566293568 PSPClimTimStatus_Hrs 1010;
BA_ "GenSigSendType" SG_ 2566293568 PSPClimTimStatus_MinRes 3;
BA_ "GenSigStartValue" SG_ 2566293568 PSPClimTimStatus_MinRes 7;
BA_ "GenSigMaxLatency" SG_ 2566293568 PSPClimTimStatus_MinRes 1010;
BA_ "GenSigSendType" SG_ 2566293568 PSPClimTimStatus_Temp 3;
BA_ "GenSigStartValue" SG_ 2566293568 PSPClimTimStatus_Temp 255;
BA_ "GenSigMaxLatency" SG_ 2566293568 PSPClimTimStatus_Temp 1010;
BA_ "GenSigSendType" SG_ 2566293568 PSPClimTimStatus_Sun 3;
BA_ "GenSigMaxLatency" SG_ 2566293568 PSPClimTimStatus_Sun 1010;
BA_ "GenSigSendType" SG_ 2566293568 PSPClimTimStatus_Mon 3;
BA_ "GenSigMaxLatency" SG_ 2566293568 PSPClimTimStatus_Mon 1010;
BA_ "GenSigSendType" SG_ 2566359616 PV_AlarmClockAlarms_Type 3;
BA_ "GenSigStartValue" SG_ 2566359616 PV_AlarmClockAlarms_Type 7;
BA_ "GenSigMaxLatency" SG_ 2566359616 PV_AlarmClockAlarms_Type 1015;
BA_ "GenSigSendType" SG_ 2566359616 PV_AlmClkCurAlarm_SetHr 3;
BA_ "GenSigStartValue" SG_ 2566359616 PV_AlmClkCurAlarm_SetHr 31;
BA_ "GenSigMaxLatency" SG_ 2566359616 PV_AlmClkCurAlarm_SetHr 1015;
BA_ "GenSigCycleTime" SG_ 2566359616 CabHeatManReq 100;
BA_ "GenSigCycleTimeActive" SG_ 2566359616 CabHeatManReq 100;
BA_ "GenSigStartValue" SG_ 2566359616 CabHeatManReq 15;
BA_ "GenSigSendType" SG_ 2566359616 PV_AlarmClockAlarms_Stat 3;
BA_ "GenSigMaxLatency" SG_ 2566359616 PV_AlarmClockAlarms_Stat 1015;
BA_ "GenSigSendType" SG_ 2566359616 PV_AlarmClockAlarms_DaySet 3;
BA_ "GenSigStartValue" SG_ 2566359616 PV_AlarmClockAlarms_DaySet 255;
BA_ "GenSigMaxLatency" SG_ 2566359616 PV_AlarmClockAlarms_DaySet 1015;
BA_ "GenSigSendType" SG_ 2566359616 PV_AlmClkCurAlarm_Stat 3;
BA_ "GenSigMaxLatency" SG_ 2566359616 PV_AlmClkCurAlarm_Stat 1015;
BA_ "GenSigSendType" SG_ 2566359616 PV_AlarmClockAlarms_ID 3;
BA_ "GenSigStartValue" SG_ 2566359616 PV_AlarmClockAlarms_ID 127;
BA_ "GenSigMaxLatency" SG_ 2566359616 PV_AlarmClockAlarms_ID 1015;
BA_ "GenSigSendType" SG_ 2566359616 PV_AlmClkCurAlarm_Type 3;
BA_ "GenSigStartValue" SG_ 2566359616 PV_AlmClkCurAlarm_Type 7;
BA_ "GenSigMaxLatency" SG_ 2566359616 PV_AlmClkCurAlarm_Type 1015;
BA_ "GenSigSendType" SG_ 2566359616 PV_AlmClkCurAlarm_ID 3;
BA_ "GenSigStartValue" SG_ 2566359616 PV_AlmClkCurAlarm_ID 127;
BA_ "GenSigMaxLatency" SG_ 2566359616 PV_AlmClkCurAlarm_ID 1015;
BA_ "GenSigSendType" SG_ 2566359616 PV_AlarmClockAlarms_SetMin 3;
BA_ "GenSigStartValue" SG_ 2566359616 PV_AlarmClockAlarms_SetMin 63;
BA_ "GenSigMaxLatency" SG_ 2566359616 PV_AlarmClockAlarms_SetMin 1015;
BA_ "GenSigSendType" SG_ 2566359616 PS_AlarmClockAlarmSet 3;
BA_ "GenSigStartValue" SG_ 2566359616 PS_AlarmClockAlarmSet 3;
BA_ "GenSigSendType" SG_ 2566359616 PV_AlarmClockAlarms_Mode 3;
BA_ "GenSigMaxLatency" SG_ 2566359616 PV_AlarmClockAlarms_Mode 1015;
BA_ "GenSigSendType" SG_ 2566359616 PV_AlmClkCurAlarm_SetMin 3;
BA_ "GenSigStartValue" SG_ 2566359616 PV_AlmClkCurAlarm_SetMin 63;
BA_ "GenSigMaxLatency" SG_ 2566359616 PV_AlmClkCurAlarm_SetMin 1015;
BA_ "GenSigSendType" SG_ 2566359616 PV_AlarmClockAlarms_SetHr 3;
BA_ "GenSigStartValue" SG_ 2566359616 PV_AlarmClockAlarms_SetHr 31;
BA_ "GenSigMaxLatency" SG_ 2566359616 PV_AlarmClockAlarms_SetHr 1015;
BA_ "GenSigCycleTime" SG_ 2549793856 PV_LocalDay 100;
BA_ "GenSigCycleTimeActive" SG_ 2549793856 PV_LocalDay 100;
BA_ "GenSigStartValue" SG_ 2549793856 PV_LocalDay 255;
BA_ "GenSigMaxLatency" SG_ 2549793856 PV_LocalDay 250;
BA_ "GenSigCycleTime" SG_ 2549793856 PV_LocalMinute 100;
BA_ "GenSigCycleTimeActive" SG_ 2549793856 PV_LocalMinute 100;
BA_ "GenSigStartValue" SG_ 2549793856 PV_LocalMinute 255;
BA_ "GenSigMaxLatency" SG_ 2549793856 PV_LocalMinute 250;
BA_ "GenSigCycleTime" SG_ 2549793856 PV_LocalSecond 100;
BA_ "GenSigCycleTimeActive" SG_ 2549793856 PV_LocalSecond 100;
BA_ "GenSigStartValue" SG_ 2549793856 PV_LocalSecond 255;
BA_ "GenSigMaxLatency" SG_ 2549793856 PV_LocalSecond 250;
BA_ "GenSigCycleTime" SG_ 2549793856 PV_LocalHour 100;
BA_ "GenSigCycleTimeActive" SG_ 2549793856 PV_LocalHour 100;
BA_ "GenSigStartValue" SG_ 2549793856 PV_LocalHour 255;
BA_ "GenSigMaxLatency" SG_ 2549793856 PV_LocalHour 250;
BA_ "GenSigCycleTime" SG_ 2549793856 PV_LocalWeekday 100;
BA_ "GenSigCycleTimeActive" SG_ 2549793856 PV_LocalWeekday 100;
BA_ "GenSigStartValue" SG_ 2549793856 PV_LocalWeekday 15;
BA_ "GenSigMaxLatency" SG_ 2549793856 PV_LocalWeekday 250;
BA_ "GenSigCycleTime" SG_ 2549793856 PV_LocalYear 100;
BA_ "GenSigCycleTimeActive" SG_ 2549793856 PV_LocalYear 100;
BA_ "GenSigStartValue" SG_ 2549793856 PV_LocalYear 255;
BA_ "GenSigMaxLatency" SG_ 2549793856 PV_LocalYear 250;
BA_ "GenSigCycleTime" SG_ 2549793856 PV_LocalMonth 100;
BA_ "GenSigCycleTimeActive" SG_ 2549793856 PV_LocalMonth 100;
BA_ "GenSigStartValue" SG_ 2549793856 PV_LocalMonth 255;
BA_ "GenSigMaxLatency" SG_ 2549793856 PV_LocalMonth 250;
BA_ "GenSigCycleTime" SG_ 2561225792 ESSClntTmp 100;
BA_ "GenSigCycleTimeActive" SG_ 2561225792 ESSClntTmp 100;
BA_ "GenSigStartValue" SG_ 2561225792 ESSClntTmp 255;
BA_ "GenSigCycleTime" SG_ 2561225792 ChlrUsgRqst 100;
BA_ "GenSigCycleTimeActive" SG_ 2561225792 ChlrUsgRqst 100;
BA_ "GenSigStartValue" SG_ 2561225792 ChlrUsgRqst 255;
BA_ "GenSigCycleTime" SG_ 2561225792 ESSPmpSpd 100;
BA_ "GenSigCycleTimeActive" SG_ 2561225792 ESSPmpSpd 100;
BA_ "GenSigStartValue" SG_ 2561225792 ESSPmpSpd 255;
BA_ "GenSigCycleTime" SG_ 2561225792 ESSTmp 100;
BA_ "GenSigCycleTimeActive" SG_ 2561225792 ESSTmp 100;
BA_ "GenSigStartValue" SG_ 2561225792 ESSTmp 255;
BA_ "GenSigCycleTime" SG_ 2561225792 ChlrVlvPsnFlt 100;
BA_ "GenSigCycleTimeActive" SG_ 2561225792 ChlrVlvPsnFlt 100;
BA_ "GenSigStartValue" SG_ 2561225792 ChlrVlvPsnFlt 3;
BA_ "GenSigCycleTime" SG_ 2561225792 EMPmpSpd 100;
BA_ "GenSigCycleTimeActive" SG_ 2561225792 EMPmpSpd 100;
BA_ "GenSigStartValue" SG_ 2561225792 EMPmpSpd 255;
BA_ "GenSigCycleTime" SG_ 2561225792 RadrFnStatus 100;
BA_ "GenSigCycleTimeActive" SG_ 2561225792 RadrFnStatus 100;
BA_ "GenSigStartValue" SG_ 2561225792 RadrFnStatus 7;
BA_ "GenSigCycleTime" SG_ 2561225792 ESSTmpTrgt 100;
BA_ "GenSigCycleTimeActive" SG_ 2561225792 ESSTmpTrgt 100;
BA_ "GenSigStartValue" SG_ 2561225792 ESSTmpTrgt 255;
BA_ "GenSigCycleTime" SG_ 2566357824 CCtrlRemActTmpOpRqst_Act 100;
BA_ "GenSigCycleTimeActive" SG_ 2566357824 CCtrlRemActTmpOpRqst_Act 100;
BA_ "GenSigStartValue" SG_ 2566357824 CCtrlRemActTmpOpRqst_Act 7;
BA_ "GenSigCycleTime" SG_ 2566357824 BarometricPressure 100;
BA_ "GenSigCycleTimeActive" SG_ 2566357824 BarometricPressure 100;
BA_ "GenSigStartValue" SG_ 2566357824 BarometricPressure 255;
BA_ "SeToolAncestorID_SIGNAL" SG_ 2566357824 BarometricPressure "x0000001D040FEBBD";
BA_ "SeToolItemID_SIGNAL" SG_ 2566357824 BarometricPressure "x0000001D040FEBBD";
BA_ "SeToolName_SIGNAL" SG_ 2566357824 BarometricPressure "BarometricPressure";
BA_ "SeToolVersion_SIGNAL" SG_ 2566357824 BarometricPressure "1";
BA_ "GenSigCycleTime" SG_ 2566357824 Trail4Type_Towing 100;
BA_ "GenSigCycleTimeActive" SG_ 2566357824 Trail4Type_Towing 100;
BA_ "GenSigMaxLatency" SG_ 2566357824 Trail4Type_Towing 1000;
BA_ "GenSigCycleTime" SG_ 2566357824 Trail1Type_Towing 100;
BA_ "GenSigCycleTimeActive" SG_ 2566357824 Trail1Type_Towing 100;
BA_ "GenSigMaxLatency" SG_ 2566357824 Trail1Type_Towing 1000;
BA_ "GenSigCycleTime" SG_ 2566357824 Trail3Type_Towing 100;
BA_ "GenSigCycleTimeActive" SG_ 2566357824 Trail3Type_Towing 100;
BA_ "GenSigMaxLatency" SG_ 2566357824 Trail3Type_Towing 1000;
BA_ "GenSigCycleTime" SG_ 2566357824 Trail5Type_TrailType 100;
BA_ "GenSigCycleTimeActive" SG_ 2566357824 Trail5Type_TrailType 100;
BA_ "GenSigStartValue" SG_ 2566357824 Trail5Type_TrailType 7;
BA_ "GenSigMaxLatency" SG_ 2566357824 Trail5Type_TrailType 1000;
BA_ "GenSigCycleTime" SG_ 2566357824 Trail1Type_TrailType 100;
BA_ "GenSigCycleTimeActive" SG_ 2566357824 Trail1Type_TrailType 100;
BA_ "GenSigStartValue" SG_ 2566357824 Trail1Type_TrailType 7;
BA_ "GenSigMaxLatency" SG_ 2566357824 Trail1Type_TrailType 1000;
BA_ "GenSigCycleTime" SG_ 2566357824 Trail3Type_TrailType 100;
BA_ "GenSigCycleTimeActive" SG_ 2566357824 Trail3Type_TrailType 100;
BA_ "GenSigStartValue" SG_ 2566357824 Trail3Type_TrailType 7;
BA_ "GenSigMaxLatency" SG_ 2566357824 Trail3Type_TrailType 1000;
BA_ "GenSigCycleTime" SG_ 2566357824 Trail5Type_Towing 100;
BA_ "GenSigCycleTimeActive" SG_ 2566357824 Trail5Type_Towing 100;
BA_ "GenSigMaxLatency" SG_ 2566357824 Trail5Type_Towing 1000;
BA_ "GenSigCycleTime" SG_ 2566357824 Trail4Type_TrailType 100;
BA_ "GenSigCycleTimeActive" SG_ 2566357824 Trail4Type_TrailType 100;
BA_ "GenSigStartValue" SG_ 2566357824 Trail4Type_TrailType 7;
BA_ "GenSigMaxLatency" SG_ 2566357824 Trail4Type_TrailType 1000;
BA_ "GenSigCycleTime" SG_ 2566357824 Trail2Type_Towing 100;
BA_ "GenSigCycleTimeActive" SG_ 2566357824 Trail2Type_Towing 100;
BA_ "GenSigMaxLatency" SG_ 2566357824 Trail2Type_Towing 1000;
BA_ "GenSigCycleTime" SG_ 2566357824 CCtrlRemActTmpOpRqst_Temp 100;
BA_ "GenSigCycleTimeActive" SG_ 2566357824 CCtrlRemActTmpOpRqst_Temp 100;
BA_ "GenSigStartValue" SG_ 2566357824 CCtrlRemActTmpOpRqst_Temp 255;
BA_ "GenSigCycleTime" SG_ 2566357824 Trail2Type_TrailType 100;
BA_ "GenSigCycleTimeActive" SG_ 2566357824 Trail2Type_TrailType 100;
BA_ "GenSigStartValue" SG_ 2566357824 Trail2Type_TrailType 7;
BA_ "GenSigMaxLatency" SG_ 2566357824 Trail2Type_TrailType 1000;
BA_ "GenSigCycleTime" SG_ 2566802240 Trail1NoOfAxles 100;
BA_ "GenSigCycleTimeActive" SG_ 2566802240 Trail1NoOfAxles 100;
BA_ "GenSigStartValue" SG_ 2566802240 Trail1NoOfAxles 15;
BA_ "GenSigCycleTime" SG_ 2566802240 Trail3NoOfAxles 100;
BA_ "GenSigCycleTimeActive" SG_ 2566802240 Trail3NoOfAxles 100;
BA_ "GenSigStartValue" SG_ 2566802240 Trail3NoOfAxles 15;
BA_ "GenSigCycleTime" SG_ 2566802240 Trail5NoOfAxles 100;
BA_ "GenSigCycleTimeActive" SG_ 2566802240 Trail5NoOfAxles 100;
BA_ "GenSigStartValue" SG_ 2566802240 Trail5NoOfAxles 15;
BA_ "GenSigCycleTime" SG_ 2566802240 Trail5NoOfFrontAxles 100;
BA_ "GenSigCycleTimeActive" SG_ 2566802240 Trail5NoOfFrontAxles 100;
BA_ "GenSigStartValue" SG_ 2566802240 Trail5NoOfFrontAxles 15;
BA_ "GenSigMaxLatency" SG_ 2566802240 Trail5NoOfFrontAxles 1001;
BA_ "GenSigCycleTime" SG_ 2566802240 Trail2NoOfFrontAxles 100;
BA_ "GenSigCycleTimeActive" SG_ 2566802240 Trail2NoOfFrontAxles 100;
BA_ "GenSigStartValue" SG_ 2566802240 Trail2NoOfFrontAxles 15;
BA_ "GenSigMaxLatency" SG_ 2566802240 Trail2NoOfFrontAxles 1001;
BA_ "GenSigCycleTime" SG_ 2566802240 Trail1NoOfFrontAxles 100;
BA_ "GenSigCycleTimeActive" SG_ 2566802240 Trail1NoOfFrontAxles 100;
BA_ "GenSigStartValue" SG_ 2566802240 Trail1NoOfFrontAxles 15;
BA_ "GenSigMaxLatency" SG_ 2566802240 Trail1NoOfFrontAxles 1001;
BA_ "GenSigCycleTime" SG_ 2566802240 Trail4NoOfAxles 100;
BA_ "GenSigCycleTimeActive" SG_ 2566802240 Trail4NoOfAxles 100;
BA_ "GenSigStartValue" SG_ 2566802240 Trail4NoOfAxles 15;
BA_ "GenSigCycleTime" SG_ 2566802240 Trail3NoOfFrontAxles 100;
BA_ "GenSigCycleTimeActive" SG_ 2566802240 Trail3NoOfFrontAxles 100;
BA_ "GenSigStartValue" SG_ 2566802240 Trail3NoOfFrontAxles 15;
BA_ "GenSigMaxLatency" SG_ 2566802240 Trail3NoOfFrontAxles 1001;
BA_ "GenSigCycleTime" SG_ 2566802240 Trail4NoOfFrontAxles 100;
BA_ "GenSigCycleTimeActive" SG_ 2566802240 Trail4NoOfFrontAxles 100;
BA_ "GenSigStartValue" SG_ 2566802240 Trail4NoOfFrontAxles 15;
BA_ "GenSigMaxLatency" SG_ 2566802240 Trail4NoOfFrontAxles 1001;
BA_ "GenSigCycleTime" SG_ 2566802240 Trail2NoOfAxles 100;
BA_ "GenSigCycleTimeActive" SG_ 2566802240 Trail2NoOfAxles 100;
BA_ "GenSigStartValue" SG_ 2566802240 Trail2NoOfAxles 15;
BA_ "GenSigSendType" SG_ 2566653760 LECM_BunkClimatePowerRequest 3;
BA_ "GenSigStartValue" SG_ 2566653760 LECM_BunkClimatePowerRequest 3;
BA_ "GenSigCycleTime" SG_ 2566653760 RelCargoLoadTrailer3 100;
BA_ "GenSigCycleTimeActive" SG_ 2566653760 RelCargoLoadTrailer3 100;
BA_ "GenSigStartValue" SG_ 2566653760 RelCargoLoadTrailer3 65535;
BA_ "GenSigMaxLatency" SG_ 2566653760 RelCargoLoadTrailer3 1001;
BA_ "GenSigCycleTime" SG_ 2566653760 RelCargoLoadTrailer5 100;
BA_ "GenSigCycleTimeActive" SG_ 2566653760 RelCargoLoadTrailer5 100;
BA_ "GenSigStartValue" SG_ 2566653760 RelCargoLoadTrailer5 65535;
BA_ "GenSigMaxLatency" SG_ 2566653760 RelCargoLoadTrailer5 1001;
BA_ "GenSigSendType" SG_ 2566653760 LECM_ClimatePowerRequest 3;
BA_ "GenSigStartValue" SG_ 2566653760 LECM_ClimatePowerRequest 3;
BA_ "GenSigCycleTime" SG_ 2566653760 RelCargoLoadTrailer4 100;
BA_ "GenSigCycleTimeActive" SG_ 2566653760 RelCargoLoadTrailer4 100;
BA_ "GenSigStartValue" SG_ 2566653760 RelCargoLoadTrailer4 65535;
BA_ "GenSigMaxLatency" SG_ 2566653760 RelCargoLoadTrailer4 1001;
BA_ "GenSigCycleTime" SG_ 2566579520 RelCargoLoadTrailer1 100;
BA_ "GenSigCycleTimeActive" SG_ 2566579520 RelCargoLoadTrailer1 100;
BA_ "GenSigStartValue" SG_ 2566579520 RelCargoLoadTrailer1 65535;
BA_ "GenSigMaxLatency" SG_ 2566579520 RelCargoLoadTrailer1 1001;
BA_ "GenSigCycleTime" SG_ 2566579520 LoadTrailer5 100;
BA_ "GenSigCycleTimeActive" SG_ 2566579520 LoadTrailer5 100;
BA_ "GenSigStartValue" SG_ 2566579520 LoadTrailer5 65535;
BA_ "GenSigMaxLatency" SG_ 2566579520 LoadTrailer5 1001;
BA_ "GenSigCycleTime" SG_ 2566579520 RelCargoLoadTrailer2 100;
BA_ "GenSigCycleTimeActive" SG_ 2566579520 RelCargoLoadTrailer2 100;
BA_ "GenSigStartValue" SG_ 2566579520 RelCargoLoadTrailer2 65535;
BA_ "GenSigMaxLatency" SG_ 2566579520 RelCargoLoadTrailer2 1001;
BA_ "GenSigCycleTime" SG_ 2566579520 RelCargoLoadTruck 100;
BA_ "GenSigCycleTimeActive" SG_ 2566579520 RelCargoLoadTruck 100;
BA_ "GenSigStartValue" SG_ 2566579520 RelCargoLoadTruck 65535;
BA_ "GenSigMaxLatency" SG_ 2566579520 RelCargoLoadTruck 1001;
BA_ "GenSigCycleTime" SG_ 2566505280 LoadTrailer4 100;
BA_ "GenSigCycleTimeActive" SG_ 2566505280 LoadTrailer4 100;
BA_ "GenSigStartValue" SG_ 2566505280 LoadTrailer4 65535;
BA_ "GenSigMaxLatency" SG_ 2566505280 LoadTrailer4 1001;
BA_ "GenSigCycleTime" SG_ 2566505280 LoadTrailer3 100;
BA_ "GenSigCycleTimeActive" SG_ 2566505280 LoadTrailer3 100;
BA_ "GenSigStartValue" SG_ 2566505280 LoadTrailer3 65535;
BA_ "GenSigMaxLatency" SG_ 2566505280 LoadTrailer3 1001;
BA_ "GenSigCycleTime" SG_ 2566505280 LoadTrailer2 100;
BA_ "GenSigCycleTimeActive" SG_ 2566505280 LoadTrailer2 100;
BA_ "GenSigStartValue" SG_ 2566505280 LoadTrailer2 65535;
BA_ "GenSigMaxLatency" SG_ 2566505280 LoadTrailer2 1001;
BA_ "GenSigCycleTime" SG_ 2566505280 LoadTrailer1 100;
BA_ "GenSigCycleTimeActive" SG_ 2566505280 LoadTrailer1 100;
BA_ "GenSigStartValue" SG_ 2566505280 LoadTrailer1 65535;
BA_ "GenSigMaxLatency" SG_ 2566505280 LoadTrailer1 1001;
BA_ "GenSigCycleTime" SG_ 2566431040 CalLoadTruckRearAxle2 100;
BA_ "GenSigCycleTimeActive" SG_ 2566431040 CalLoadTruckRearAxle2 100;
BA_ "GenSigStartValue" SG_ 2566431040 CalLoadTruckRearAxle2 65535;
BA_ "GenSigMaxLatency" SG_ 2566431040 CalLoadTruckRearAxle2 1001;
BA_ "GenSigCycleTime" SG_ 2566431040 CalLoadTruckRearAxle3 100;
BA_ "GenSigCycleTimeActive" SG_ 2566431040 CalLoadTruckRearAxle3 100;
BA_ "GenSigStartValue" SG_ 2566431040 CalLoadTruckRearAxle3 65535;
BA_ "GenSigMaxLatency" SG_ 2566431040 CalLoadTruckRearAxle3 1001;
BA_ "GenSigCycleTime" SG_ 2566431040 LoadTruck 100;
BA_ "GenSigCycleTimeActive" SG_ 2566431040 LoadTruck 100;
BA_ "GenSigStartValue" SG_ 2566431040 LoadTruck 65535;
BA_ "GenSigMaxLatency" SG_ 2566431040 LoadTruck 1001;
BA_ "GenSigCycleTime" SG_ 2566431040 CalLoadTruckRearAxle1 100;
BA_ "GenSigCycleTimeActive" SG_ 2566431040 CalLoadTruckRearAxle1 100;
BA_ "GenSigStartValue" SG_ 2566431040 CalLoadTruckRearAxle1 65535;
BA_ "GenSigMaxLatency" SG_ 2566431040 CalLoadTruckRearAxle1 1001;
BA_ "GenSigCycleTime" SG_ 2566357568 CalLoadTruckFrontAxle2 100;
BA_ "GenSigCycleTimeActive" SG_ 2566357568 CalLoadTruckFrontAxle2 100;
BA_ "GenSigStartValue" SG_ 2566357568 CalLoadTruckFrontAxle2 65535;
BA_ "GenSigMaxLatency" SG_ 2566357568 CalLoadTruckFrontAxle2 1001;
BA_ "GenSigCycleTime" SG_ 2566357568 CalLoadTruckFrontAxle1 100;
BA_ "GenSigCycleTimeActive" SG_ 2566357568 CalLoadTruckFrontAxle1 100;
BA_ "GenSigStartValue" SG_ 2566357568 CalLoadTruckFrontAxle1 65535;
BA_ "GenSigMaxLatency" SG_ 2566357568 CalLoadTruckFrontAxle1 1001;
BA_ "GenSigCycleTime" SG_ 2566357568 CalLoadTrailer5Axle6 100;
BA_ "GenSigCycleTimeActive" SG_ 2566357568 CalLoadTrailer5Axle6 100;
BA_ "GenSigStartValue" SG_ 2566357568 CalLoadTrailer5Axle6 65535;
BA_ "GenSigMaxLatency" SG_ 2566357568 CalLoadTrailer5Axle6 1001;
BA_ "GenSigCycleTime" SG_ 2566357568 CalLoadTrailer5Axle5 100;
BA_ "GenSigCycleTimeActive" SG_ 2566357568 CalLoadTrailer5Axle5 100;
BA_ "GenSigStartValue" SG_ 2566357568 CalLoadTrailer5Axle5 65535;
BA_ "GenSigMaxLatency" SG_ 2566357568 CalLoadTrailer5Axle5 1001;
BA_ "GenSigCycleTime" SG_ 2566282560 CalLoadTrailer5Axle1 100;
BA_ "GenSigCycleTimeActive" SG_ 2566282560 CalLoadTrailer5Axle1 100;
BA_ "GenSigStartValue" SG_ 2566282560 CalLoadTrailer5Axle1 65535;
BA_ "GenSigMaxLatency" SG_ 2566282560 CalLoadTrailer5Axle1 1001;
BA_ "GenSigCycleTime" SG_ 2566282560 CalLoadTrailer5Axle2 100;
BA_ "GenSigCycleTimeActive" SG_ 2566282560 CalLoadTrailer5Axle2 100;
BA_ "GenSigStartValue" SG_ 2566282560 CalLoadTrailer5Axle2 65535;
BA_ "GenSigMaxLatency" SG_ 2566282560 CalLoadTrailer5Axle2 1001;
BA_ "GenSigCycleTime" SG_ 2566282560 CalLoadTrailer5Axle4 100;
BA_ "GenSigCycleTimeActive" SG_ 2566282560 CalLoadTrailer5Axle4 100;
BA_ "GenSigStartValue" SG_ 2566282560 CalLoadTrailer5Axle4 65535;
BA_ "GenSigMaxLatency" SG_ 2566282560 CalLoadTrailer5Axle4 1001;
BA_ "GenSigCycleTime" SG_ 2566282560 CalLoadTrailer5Axle3 100;
BA_ "GenSigCycleTimeActive" SG_ 2566282560 CalLoadTrailer5Axle3 100;
BA_ "GenSigStartValue" SG_ 2566282560 CalLoadTrailer5Axle3 65535;
BA_ "GenSigMaxLatency" SG_ 2566282560 CalLoadTrailer5Axle3 1001;
BA_ "GenSigCycleTime" SG_ 2566208320 CalLoadTrailer4Axle5 100;
BA_ "GenSigCycleTimeActive" SG_ 2566208320 CalLoadTrailer4Axle5 100;
BA_ "GenSigStartValue" SG_ 2566208320 CalLoadTrailer4Axle5 65535;
BA_ "GenSigMaxLatency" SG_ 2566208320 CalLoadTrailer4Axle5 1001;
BA_ "GenSigCycleTime" SG_ 2566208320 CalLoadTrailer4Axle4 100;
BA_ "GenSigCycleTimeActive" SG_ 2566208320 CalLoadTrailer4Axle4 100;
BA_ "GenSigStartValue" SG_ 2566208320 CalLoadTrailer4Axle4 65535;
BA_ "GenSigMaxLatency" SG_ 2566208320 CalLoadTrailer4Axle4 1001;
BA_ "GenSigCycleTime" SG_ 2566208320 CalLoadTrailer4Axle3 100;
BA_ "GenSigCycleTimeActive" SG_ 2566208320 CalLoadTrailer4Axle3 100;
BA_ "GenSigStartValue" SG_ 2566208320 CalLoadTrailer4Axle3 65535;
BA_ "GenSigMaxLatency" SG_ 2566208320 CalLoadTrailer4Axle3 1001;
BA_ "GenSigCycleTime" SG_ 2566208320 CalLoadTrailer4Axle6 100;
BA_ "GenSigCycleTimeActive" SG_ 2566208320 CalLoadTrailer4Axle6 100;
BA_ "GenSigStartValue" SG_ 2566208320 CalLoadTrailer4Axle6 65535;
BA_ "GenSigMaxLatency" SG_ 2566208320 CalLoadTrailer4Axle6 1001;
BA_ "GenSigCycleTime" SG_ 2566134080 CalLoadTrailer3Axle6 100;
BA_ "GenSigCycleTimeActive" SG_ 2566134080 CalLoadTrailer3Axle6 100;
BA_ "GenSigStartValue" SG_ 2566134080 CalLoadTrailer3Axle6 65535;
BA_ "GenSigMaxLatency" SG_ 2566134080 CalLoadTrailer3Axle6 1001;
BA_ "GenSigCycleTime" SG_ 2566134080 CalLoadTrailer3Axle5 100;
BA_ "GenSigCycleTimeActive" SG_ 2566134080 CalLoadTrailer3Axle5 100;
BA_ "GenSigStartValue" SG_ 2566134080 CalLoadTrailer3Axle5 65535;
BA_ "GenSigMaxLatency" SG_ 2566134080 CalLoadTrailer3Axle5 1001;
BA_ "GenSigCycleTime" SG_ 2566134080 CalLoadTrailer4Axle1 100;
BA_ "GenSigCycleTimeActive" SG_ 2566134080 CalLoadTrailer4Axle1 100;
BA_ "GenSigStartValue" SG_ 2566134080 CalLoadTrailer4Axle1 65535;
BA_ "GenSigMaxLatency" SG_ 2566134080 CalLoadTrailer4Axle1 1001;
BA_ "GenSigCycleTime" SG_ 2566134080 CalLoadTrailer4Axle2 100;
BA_ "GenSigCycleTimeActive" SG_ 2566134080 CalLoadTrailer4Axle2 100;
BA_ "GenSigStartValue" SG_ 2566134080 CalLoadTrailer4Axle2 65535;
BA_ "GenSigMaxLatency" SG_ 2566134080 CalLoadTrailer4Axle2 1001;
BA_ "GenSigCycleTime" SG_ 2566059840 CalLoadTrailer3Axle1 100;
BA_ "GenSigCycleTimeActive" SG_ 2566059840 CalLoadTrailer3Axle1 100;
BA_ "GenSigStartValue" SG_ 2566059840 CalLoadTrailer3Axle1 65535;
BA_ "GenSigMaxLatency" SG_ 2566059840 CalLoadTrailer3Axle1 1001;
BA_ "GenSigCycleTime" SG_ 2566059840 CalLoadTrailer3Axle3 100;
BA_ "GenSigCycleTimeActive" SG_ 2566059840 CalLoadTrailer3Axle3 100;
BA_ "GenSigStartValue" SG_ 2566059840 CalLoadTrailer3Axle3 65535;
BA_ "GenSigMaxLatency" SG_ 2566059840 CalLoadTrailer3Axle3 1001;
BA_ "GenSigCycleTime" SG_ 2566059840 CalLoadTrailer3Axle4 100;
BA_ "GenSigCycleTimeActive" SG_ 2566059840 CalLoadTrailer3Axle4 100;
BA_ "GenSigStartValue" SG_ 2566059840 CalLoadTrailer3Axle4 65535;
BA_ "GenSigMaxLatency" SG_ 2566059840 CalLoadTrailer3Axle4 1001;
BA_ "GenSigCycleTime" SG_ 2566059840 CalLoadTrailer3Axle2 100;
BA_ "GenSigCycleTimeActive" SG_ 2566059840 CalLoadTrailer3Axle2 100;
BA_ "GenSigStartValue" SG_ 2566059840 CalLoadTrailer3Axle2 65535;
BA_ "GenSigMaxLatency" SG_ 2566059840 CalLoadTrailer3Axle2 1001;
BA_ "GenSigCycleTime" SG_ 2565985600 CalLoadTrailer2Axle4 100;
BA_ "GenSigCycleTimeActive" SG_ 2565985600 CalLoadTrailer2Axle4 100;
BA_ "GenSigStartValue" SG_ 2565985600 CalLoadTrailer2Axle4 65535;
BA_ "GenSigMaxLatency" SG_ 2565985600 CalLoadTrailer2Axle4 1001;
BA_ "GenSigCycleTime" SG_ 2565985600 CalLoadTrailer2Axle5 100;
BA_ "GenSigCycleTimeActive" SG_ 2565985600 CalLoadTrailer2Axle5 100;
BA_ "GenSigStartValue" SG_ 2565985600 CalLoadTrailer2Axle5 65535;
BA_ "GenSigMaxLatency" SG_ 2565985600 CalLoadTrailer2Axle5 1001;
BA_ "GenSigCycleTime" SG_ 2565985600 CalLoadTrailer2Axle3 100;
BA_ "GenSigCycleTimeActive" SG_ 2565985600 CalLoadTrailer2Axle3 100;
BA_ "GenSigStartValue" SG_ 2565985600 CalLoadTrailer2Axle3 65535;
BA_ "GenSigMaxLatency" SG_ 2565985600 CalLoadTrailer2Axle3 1001;
BA_ "GenSigCycleTime" SG_ 2565985600 CalLoadTrailer2Axle6 100;
BA_ "GenSigCycleTimeActive" SG_ 2565985600 CalLoadTrailer2Axle6 100;
BA_ "GenSigStartValue" SG_ 2565985600 CalLoadTrailer2Axle6 65535;
BA_ "GenSigMaxLatency" SG_ 2565985600 CalLoadTrailer2Axle6 1001;
BA_ "GenSigCycleTime" SG_ 2565911360 CalLoadTrailer1Axle6 100;
BA_ "GenSigCycleTimeActive" SG_ 2565911360 CalLoadTrailer1Axle6 100;
BA_ "GenSigStartValue" SG_ 2565911360 CalLoadTrailer1Axle6 65535;
BA_ "GenSigMaxLatency" SG_ 2565911360 CalLoadTrailer1Axle6 1001;
BA_ "GenSigCycleTime" SG_ 2565911360 CalLoadTrailer1Axle5 100;
BA_ "GenSigCycleTimeActive" SG_ 2565911360 CalLoadTrailer1Axle5 100;
BA_ "GenSigStartValue" SG_ 2565911360 CalLoadTrailer1Axle5 65535;
BA_ "GenSigMaxLatency" SG_ 2565911360 CalLoadTrailer1Axle5 1001;
BA_ "GenSigCycleTime" SG_ 2565911360 CalLoadTrailer2Axle1 100;
BA_ "GenSigCycleTimeActive" SG_ 2565911360 CalLoadTrailer2Axle1 100;
BA_ "GenSigStartValue" SG_ 2565911360 CalLoadTrailer2Axle1 65535;
BA_ "GenSigMaxLatency" SG_ 2565911360 CalLoadTrailer2Axle1 1001;
BA_ "GenSigCycleTime" SG_ 2565911360 CalLoadTrailer2Axle2 100;
BA_ "GenSigCycleTimeActive" SG_ 2565911360 CalLoadTrailer2Axle2 100;
BA_ "GenSigStartValue" SG_ 2565911360 CalLoadTrailer2Axle2 65535;
BA_ "GenSigMaxLatency" SG_ 2565911360 CalLoadTrailer2Axle2 1001;
BA_REL_ "GenSigFirstTimeoutTime" BU_SG_REL_ CIOM SG_ 2466243731 CMSMenu_stat 3000;
BA_REL_ "GenSigTimeoutTime" BU_SG_REL_ CIOM SG_ 2466243731 CMSMenu_stat 180;
BA_REL_ "GenSigFirstTimeoutTime" BU_SG_REL_ CIOM SG_ 2466243731 CMSMirrorHeatingMode_stat 3000;
BA_REL_ "GenSigTimeoutTime" BU_SG_REL_ CIOM SG_ 2466243731 CMSMirrorHeatingMode_stat 180;
BA_REL_ "GenSigFirstTimeoutTime" BU_SG_REL_ CIOM SG_ 2466243731 CMSDisplayButton1_stat 3000;
BA_REL_ "GenSigTimeoutTime" BU_SG_REL_ CIOM SG_ 2466243731 CMSDisplayButton1_stat 180;
BA_REL_ "GenSigFirstTimeoutTime" BU_SG_REL_ CIOM SG_ 2466243731 CMSElectricalFOV_stat 3000;
BA_REL_ "GenSigTimeoutTime" BU_SG_REL_ CIOM SG_ 2466243731 CMSElectricalFOV_stat 180;
BA_REL_ "GenSigFirstTimeoutTime" BU_SG_REL_ CIOM SG_ 2466243731 CMSPanning_stat 3000;
BA_REL_ "GenSigTimeoutTime" BU_SG_REL_ CIOM SG_ 2466243731 CMSPanning_stat 180;
BA_REL_ "GenSigFirstTimeoutTime" BU_SG_REL_ CIOM SG_ 2466243731 CMSEnhancedNightVision_stat 3000;
BA_REL_ "GenSigTimeoutTime" BU_SG_REL_ CIOM SG_ 2466243731 CMSEnhancedNightVision_stat 180;
BA_REL_ "GenSigFirstTimeoutTime" BU_SG_REL_ CIOM SG_ 2466243731 DistanceLines_stat 3000;
BA_REL_ "GenSigTimeoutTime" BU_SG_REL_ CIOM SG_ 2466243731 DistanceLines_stat 180;
BA_REL_ "GenSigFirstTimeoutTime" BU_SG_REL_ CIOM SG_ 2466243731 CMSLCSWarningLeftStatus_stat 3000;
BA_REL_ "GenSigTimeoutTime" BU_SG_REL_ CIOM SG_ 2466243731 CMSLCSWarningLeftStatus_stat 180;
BA_REL_ "GenSigFirstTimeoutTime" BU_SG_REL_ CIOM SG_ 2466243731 CMSEOVLine_stat 3000;
BA_REL_ "GenSigTimeoutTime" BU_SG_REL_ CIOM SG_ 2466243731 CMSEOVLine_stat 180;
BA_REL_ "GenSigFirstTimeoutTime" BU_SG_REL_ CIOM SG_ 2466243731 FixedReversePanOutView_stat 3000;
BA_REL_ "GenSigTimeoutTime" BU_SG_REL_ CIOM SG_ 2466243731 FixedReversePanOutView_stat 180;
BA_REL_ "GenSigFirstTimeoutTime" BU_SG_REL_ CIOM SG_ 2466243731 CMSFoldingMenuFeedback_stat 3000;
BA_REL_ "GenSigTimeoutTime" BU_SG_REL_ CIOM SG_ 2466243731 CMSFoldingMenuFeedback_stat 180;
BA_REL_ "GenSigFirstTimeoutTime" BU_SG_REL_ CIOM SG_ 2466243731 CMSAutoBrightnessAdj_stat 3000;
BA_REL_ "GenSigTimeoutTime" BU_SG_REL_ CIOM SG_ 2466243731 CMSAutoBrightnessAdj_stat 180;
BA_REL_ "GenSigFirstTimeoutTime" BU_SG_REL_ CIOM SG_ 2466243731 CMSClassVActDeact_stat 3000;
BA_REL_ "GenSigTimeoutTime" BU_SG_REL_ CIOM SG_ 2466243731 CMSClassVActDeact_stat 180;
BA_REL_ "GenSigFirstTimeoutTime" BU_SG_REL_ CIOM SG_ 2466243731 CMSLCSWarningRightStatus_stat 3000;
BA_REL_ "GenSigTimeoutTime" BU_SG_REL_ CIOM SG_ 2466243731 CMSLCSWarningRightStatus_stat 180;
BA_REL_ "GenSigFirstTimeoutTime" BU_SG_REL_ CMS SG_ 2495165760 CMSManualActDeactRqst_Request 3000;
BA_REL_ "GenSigTimeoutTime" BU_SG_REL_ CMS SG_ 2495165760 CMSManualActDeactRqst_Request 300;
BA_REL_ "GenSigFirstTimeoutTime" BU_SG_REL_ CMS SG_ 2495165760 CMSFoldingRqst_CRC 3000;
BA_REL_ "GenSigTimeoutTime" BU_SG_REL_ CMS SG_ 2495165760 CMSFoldingRqst_CRC 300;
BA_REL_ "GenSigFirstTimeoutTime" BU_SG_REL_ CMS SG_ 2495165760 CMSManualAlignmRqst_SqC 3000;
BA_REL_ "GenSigTimeoutTime" BU_SG_REL_ CMS SG_ 2495165760 CMSManualAlignmRqst_SqC 300;
BA_REL_ "GenSigFirstTimeoutTime" BU_SG_REL_ CMS SG_ 2495165760 CMSZoomRqst_SqC 3000;
BA_REL_ "GenSigTimeoutTime" BU_SG_REL_ CMS SG_ 2495165760 CMSZoomRqst_SqC 300;
BA_REL_ "GenSigFirstTimeoutTime" BU_SG_REL_ CMS SG_ 2495165760 CMSZoomRqst_Request 3000;
BA_REL_ "GenSigTimeoutTime" BU_SG_REL_ CMS SG_ 2495165760 CMSZoomRqst_Request 300;
BA_REL_ "GenSigFirstTimeoutTime" BU_SG_REL_ CMS SG_ 2495165760 CMSManualActDeactRqst_SqC 3000;
BA_REL_ "GenSigTimeoutTime" BU_SG_REL_ CMS SG_ 2495165760 CMSManualActDeactRqst_SqC 300;
BA_REL_ "GenSigFirstTimeoutTime" BU_SG_REL_ CMS SG_ 2495165760 CMSFoldingRqst_Request 3000;
BA_REL_ "GenSigTimeoutTime" BU_SG_REL_ CMS SG_ 2495165760 CMSFoldingRqst_Request 300;
BA_REL_ "GenSigFirstTimeoutTime" BU_SG_REL_ CMS SG_ 2495165760 CMSZoomRqst_CRC 3000;
BA_REL_ "GenSigTimeoutTime" BU_SG_REL_ CMS SG_ 2495165760 CMSZoomRqst_CRC 300;
BA_REL_ "GenSigFirstTimeoutTime" BU_SG_REL_ CMS SG_ 2495165760 CMSManualAlignmRqst_CRC 3000;
BA_REL_ "GenSigTimeoutTime" BU_SG_REL_ CMS SG_ 2495165760 CMSManualAlignmRqst_CRC 300;
BA_REL_ "GenSigFirstTimeoutTime" BU_SG_REL_ CMS SG_ 2495165760 CMSManualActDeactRqst_CRC 3000;
BA_REL_ "GenSigTimeoutTime" BU_SG_REL_ CMS SG_ 2495165760 CMSManualActDeactRqst_CRC 300;
BA_REL_ "GenSigFirstTimeoutTime" BU_SG_REL_ CMS SG_ 2495165760 CMSManualAlignmRqst_Request 3000;
BA_REL_ "GenSigTimeoutTime" BU_SG_REL_ CMS SG_ 2495165760 CMSManualAlignmRqst_Request 300;
BA_REL_ "GenSigFirstTimeoutTime" BU_SG_REL_ CMS SG_ 2495165760 CMSFoldingRqst_SqC 3000;
BA_REL_ "GenSigTimeoutTime" BU_SG_REL_ CMS SG_ 2495165760 CMSFoldingRqst_SqC 300;
BA_REL_ "GenSigFirstTimeoutTime" BU_SG_REL_ CMS SG_ 2510689088 CMSEnhancedNightVision_rqst 3000;
BA_REL_ "GenSigTimeoutTime" BU_SG_REL_ CMS SG_ 2510689088 CMSEnhancedNightVision_rqst 600;
BA_REL_ "GenSigFirstTimeoutTime" BU_SG_REL_ CMS SG_ 2510689088 AmbientLight_stat 3000;
BA_REL_ "GenSigTimeoutTime" BU_SG_REL_ CMS SG_ 2510689088 AmbientLight_stat 600;
BA_REL_ "GenSigFirstTimeoutTime" BU_SG_REL_ CMS SG_ 2510689088 CMSMenu_rqst 3000;
BA_REL_ "GenSigTimeoutTime" BU_SG_REL_ CMS SG_ 2510689088 CMSMenu_rqst 600;
BA_REL_ "GenSigFirstTimeoutTime" BU_SG_REL_ CMS SG_ 2510689088 PanicAlarm_rqst 3000;
BA_REL_ "GenSigTimeoutTime" BU_SG_REL_ CMS SG_ 2510689088 PanicAlarm_rqst 600;
BA_REL_ "GenSigFirstTimeoutTime" BU_SG_REL_ CMS SG_ 2510689088 DoorsAjar_stat 3000;
BA_REL_ "GenSigTimeoutTime" BU_SG_REL_ CMS SG_ 2510689088 DoorsAjar_stat 600;
BA_REL_ "GenSigFirstTimeoutTime" BU_SG_REL_ CMS SG_ 2510689088 CMSNavigation_rqst 3000;
BA_REL_ "GenSigTimeoutTime" BU_SG_REL_ CMS SG_ 2510689088 CMSNavigation_rqst 600;
BA_REL_ "GenSigFirstTimeoutTime" BU_SG_REL_ CMS SG_ 2510689088 TrailerConnected 3000;
BA_REL_ "GenSigTimeoutTime" BU_SG_REL_ CMS SG_ 2510689088 TrailerConnected 600;
BA_REL_ "GenSigFirstTimeoutTime" BU_SG_REL_ CMS SG_ 2510689088 CMSAutoBrightnessAdj_rqst 3000;
BA_REL_ "GenSigTimeoutTime" BU_SG_REL_ CMS SG_ 2510689088 CMSAutoBrightnessAdj_rqst 600;
BA_REL_ "GenSigFirstTimeoutTime" BU_SG_REL_ CMS SG_ 2510689088 FixedReversePanOutView_rqst 3000;
BA_REL_ "GenSigTimeoutTime" BU_SG_REL_ CMS SG_ 2510689088 FixedReversePanOutView_rqst 600;
BA_REL_ "GenSigFirstTimeoutTime" BU_SG_REL_ CMS SG_ 2510689088 CMSSelectedLanguage_stat 3000;
BA_REL_ "GenSigTimeoutTime" BU_SG_REL_ CMS SG_ 2510689088 CMSSelectedLanguage_stat 600;
BA_REL_ "GenSigFirstTimeoutTime" BU_SG_REL_ CMS SG_ 2510689088 CMSMirrorHeat_rqst 3000;
BA_REL_ "GenSigTimeoutTime" BU_SG_REL_ CMS SG_ 2510689088 CMSMirrorHeat_rqst 600;
BA_REL_ "GenSigFirstTimeoutTime" BU_SG_REL_ LECM3 SG_ 2510689088 PS_BunkFanSpeedStatus 3000;
BA_REL_ "GenSigTimeoutTime" BU_SG_REL_ LECM3 SG_ 2510689088 PS_BunkFanSpeedStatus 600;
BA_REL_ "GenSigFirstTimeoutTime" BU_SG_REL_ CMS SG_ 2510689088 TransmissionCurrentGear 3000;
BA_REL_ "GenSigTimeoutTime" BU_SG_REL_ CMS SG_ 2510689088 TransmissionCurrentGear 600;
BA_REL_ "GenSigFirstTimeoutTime" BU_SG_REL_ LECM3 SG_ 2510689088 PS_CMS_Status 3000;
BA_REL_ "GenSigTimeoutTime" BU_SG_REL_ LECM3 SG_ 2510689088 PS_CMS_Status 600;
BA_REL_ "GenSigFirstTimeoutTime" BU_SG_REL_ CMS SG_ 2510689088 AlarmStatus_stat 3000;
BA_REL_ "GenSigTimeoutTime" BU_SG_REL_ CMS SG_ 2510689088 AlarmStatus_stat 600;
BA_REL_ "GenSigFirstTimeoutTime" BU_SG_REL_ CCM SG_ 2566730048 BunkACRequest 24000;
BA_REL_ "GenSigTimeoutTime" BU_SG_REL_ CCM SG_ 2566730048 BunkACRequest 3000;
BA_REL_ "GenSigFirstTimeoutTime" BU_SG_REL_ CCM SG_ 2566730048 ClimateAirDistRequest_Vent 24000;
BA_REL_ "GenSigTimeoutTime" BU_SG_REL_ CCM SG_ 2566730048 ClimateAirDistRequest_Vent 3000;
BA_REL_ "GenSigFirstTimeoutTime" BU_SG_REL_ CCM SG_ 2566730048 OpLevelItem3 24000;
BA_REL_ "GenSigTimeoutTime" BU_SG_REL_ CCM SG_ 2566730048 OpLevelItem3 3000;
BA_REL_ "GenSigFirstTimeoutTime" BU_SG_REL_ CCM SG_ 2566730048 AirRecirculationRequest 24000;
BA_REL_ "GenSigTimeoutTime" BU_SG_REL_ CCM SG_ 2566730048 AirRecirculationRequest 3000;
BA_REL_ "GenSigFirstTimeoutTime" BU_SG_REL_ CCM SG_ 2566730048 MaxDefrostRequest 24000;
BA_REL_ "GenSigTimeoutTime" BU_SG_REL_ CCM SG_ 2566730048 MaxDefrostRequest 3000;
BA_REL_ "GenSigFirstTimeoutTime" BU_SG_REL_ CCM SG_ 2566730048 CabTempRequest 24000;
BA_REL_ "GenSigTimeoutTime" BU_SG_REL_ CCM SG_ 2566730048 CabTempRequest 3000;
BA_REL_ "GenSigFirstTimeoutTime" BU_SG_REL_ CCM SG_ 2566730048 HVACBlowerRequest 24000;
BA_REL_ "GenSigTimeoutTime" BU_SG_REL_ CCM SG_ 2566730048 HVACBlowerRequest 3000;
BA_REL_ "GenSigFirstTimeoutTime" BU_SG_REL_ CCM SG_ 2566730048 ClimateAirDistRequest_Defrost 24000;
BA_REL_ "GenSigTimeoutTime" BU_SG_REL_ CCM SG_ 2566730048 ClimateAirDistRequest_Defrost 3000;
BA_REL_ "GenSigFirstTimeoutTime" BU_SG_REL_ CCM SG_ 2566730048 BunkParkClimateRequest 24000;
BA_REL_ "GenSigTimeoutTime" BU_SG_REL_ CCM SG_ 2566730048 BunkParkClimateRequest 3000;
BA_REL_ "GenSigFirstTimeoutTime" BU_SG_REL_ CCM SG_ 2566730048 ParkingClimateRequest 24000;
BA_REL_ "GenSigTimeoutTime" BU_SG_REL_ CCM SG_ 2566730048 ParkingClimateRequest 3000;
BA_REL_ "GenSigFirstTimeoutTime" BU_SG_REL_ CCM SG_ 2566730048 BunkClimatePowerRequest 24000;
BA_REL_ "GenSigTimeoutTime" BU_SG_REL_ CCM SG_ 2566730048 BunkClimatePowerRequest 3000;
BA_REL_ "GenSigFirstTimeoutTime" BU_SG_REL_ CCM SG_ 2566730048 BunkClimateAutoRequest 24000;
BA_REL_ "GenSigTimeoutTime" BU_SG_REL_ CCM SG_ 2566730048 BunkClimateAutoRequest 3000;
BA_REL_ "GenSigFirstTimeoutTime" BU_SG_REL_ CCM SG_ 2566730048 ClimatePowerRequest 24000;
BA_REL_ "GenSigTimeoutTime" BU_SG_REL_ CCM SG_ 2566730048 ClimatePowerRequest 3000;
BA_REL_ "GenSigFirstTimeoutTime" BU_SG_REL_ CCM SG_ 2566730048 ClimateAirDistRequest_Floor 24000;
BA_REL_ "GenSigTimeoutTime" BU_SG_REL_ CCM SG_ 2566730048 ClimateAirDistRequest_Floor 3000;
BA_REL_ "GenSigFirstTimeoutTime" BU_SG_REL_ CCM SG_ 2566730048 BunkHVACBlowerRequest 24000;
BA_REL_ "GenSigTimeoutTime" BU_SG_REL_ CCM SG_ 2566730048 BunkHVACBlowerRequest 3000;
BA_REL_ "GenSigFirstTimeoutTime" BU_SG_REL_ CCM SG_ 2566730048 BunkTempRequest 24000;
BA_REL_ "GenSigTimeoutTime" BU_SG_REL_ CCM SG_ 2566730048 BunkTempRequest 3000;
BA_REL_ "GenSigFirstTimeoutTime" BU_SG_REL_ CCM SG_ 2566730048 ClimateAutoRequest 24000;
BA_REL_ "GenSigTimeoutTime" BU_SG_REL_ CCM SG_ 2566730048 ClimateAutoRequest 3000;
BA_REL_ "GenSigFirstTimeoutTime" BU_SG_REL_ CCM SG_ 2566730048 ACRequest 24000;
BA_REL_ "GenSigTimeoutTime" BU_SG_REL_ CCM SG_ 2566730048 ACRequest 3000;
BA_REL_ "GenSigFirstTimeoutTime" BU_SG_REL_ LECM3 SG_ 2566728000 SelectedSpeedUnit_stat 12000;
BA_REL_ "GenSigTimeoutTime" BU_SG_REL_ LECM3 SG_ 2566728000 SelectedSpeedUnit_stat 3000;
BA_REL_ "GenSigFirstTimeoutTime" BU_SG_REL_ LECM3 SG_ 2566728000 PV_LivingBatteryCrankReserve 12000;
BA_REL_ "GenSigTimeoutTime" BU_SG_REL_ LECM3 SG_ 2566728000 PV_LivingBatteryCrankReserve 3000;
BA_REL_ "GenSigFirstTimeoutTime" BU_SG_REL_ LECM3 SG_ 2566728000 SelectedDistanceUnit_stat 12000;
BA_REL_ "GenSigTimeoutTime" BU_SG_REL_ LECM3 SG_ 2566728000 SelectedDistanceUnit_stat 3000;
BA_REL_ "GenSigFirstTimeoutTime" BU_SG_REL_ LECM3 SG_ 2566728000 PV_LivingBatteryMaxCapacity 12000;
BA_REL_ "GenSigTimeoutTime" BU_SG_REL_ LECM3 SG_ 2566728000 PV_LivingBatteryMaxCapacity 3000;
BA_REL_ "GenSigFirstTimeoutTime" BU_SG_REL_ LECM3 SG_ 2566728000 SelectedPressureUnit_stat 12000;
BA_REL_ "GenSigTimeoutTime" BU_SG_REL_ LECM3 SG_ 2566728000 SelectedPressureUnit_stat 3000;
BA_REL_ "GenSigFirstTimeoutTime" BU_SG_REL_ LECM3 SG_ 2566728000 PV_AmbientAirTemp 12000;
BA_REL_ "GenSigTimeoutTime" BU_SG_REL_ LECM3 SG_ 2566728000 PV_AmbientAirTemp 3000;
BA_REL_ "GenSigFirstTimeoutTime" BU_SG_REL_ LECM3 SG_ 2566728000 SelectedLangUnrestricted_stat 12000;
BA_REL_ "GenSigTimeoutTime" BU_SG_REL_ LECM3 SG_ 2566728000 SelectedLangUnrestricted_stat 3000;
BA_REL_ "GenSigFirstTimeoutTime" BU_SG_REL_ LECM3 SG_ 2566728000 SelectedVolumeUnit_stat 12000;
BA_REL_ "GenSigTimeoutTime" BU_SG_REL_ LECM3 SG_ 2566728000 SelectedVolumeUnit_stat 3000;
BA_REL_ "GenSigFirstTimeoutTime" BU_SG_REL_ LECM3 SG_ 2566728000 SelectedFuelConsumptUnit_stat 12000;
BA_REL_ "GenSigTimeoutTime" BU_SG_REL_ LECM3 SG_ 2566728000 SelectedFuelConsumptUnit_stat 3000;
BA_REL_ "GenSigFirstTimeoutTime" BU_SG_REL_ LECM3 SG_ 2566728000 SelectedTemperatureUnit_stat 12000;
BA_REL_ "GenSigTimeoutTime" BU_SG_REL_ LECM3 SG_ 2566728000 SelectedTemperatureUnit_stat 3000;
BA_REL_ "GenSigFirstTimeoutTime" BU_SG_REL_ LECM3 SG_ 2566728000 PV_LivingBatterySOC 12000;
BA_REL_ "GenSigTimeoutTime" BU_SG_REL_ LECM3 SG_ 2566728000 PV_LivingBatterySOC 3000;
BA_REL_ "GenSigFirstTimeoutTime" BU_SG_REL_ LECM3 SG_ 2549579584 PS_AutoLoadCutOffState 6000;
BA_REL_ "GenSigTimeoutTime" BU_SG_REL_ LECM3 SG_ 2549579584 PS_AutoLoadCutOffState 1500;
BA_REL_ "GenSigFirstTimeoutTime" BU_SG_REL_ LECM3 SG_ 2549579584 PS_LivingBatterySOCWarning 6000;
BA_REL_ "GenSigTimeoutTime" BU_SG_REL_ LECM3 SG_ 2549579584 PS_LivingBatterySOCWarning 1500;
BA_REL_ "GenSigFirstTimeoutTime" BU_SG_REL_ LECM3 SG_ 2549579584 PV_AlarmClockNotific_Type 6000;
BA_REL_ "GenSigTimeoutTime" BU_SG_REL_ LECM3 SG_ 2549579584 PV_AlarmClockNotific_Type 1500;
BA_REL_ "GenSigFirstTimeoutTime" BU_SG_REL_ LECM3 SG_ 2549579584 PV_AlarmClockNotific_ID 6000;
BA_REL_ "GenSigTimeoutTime" BU_SG_REL_ LECM3 SG_ 2549579584 PV_AlarmClockNotific_ID 1500;
BA_REL_ "GenSigFirstTimeoutTime" BU_SG_REL_ LECM3 SG_ 2549579584 PS_AutoLoadCutOff 6000;
BA_REL_ "GenSigTimeoutTime" BU_SG_REL_ LECM3 SG_ 2549579584 PS_AutoLoadCutOff 1500;
BA_REL_ "GenSigFirstTimeoutTime" BU_SG_REL_ LECM3 SG_ 2549579584 PS_LivingBatteryTempWarning 6000;
BA_REL_ "GenSigTimeoutTime" BU_SG_REL_ LECM3 SG_ 2549579584 PS_LivingBatteryTempWarning 1500;
BA_REL_ "GenSigFirstTimeoutTime" BU_SG_REL_ LECM3 SG_ 2549579584 PV_AlarmClockNotific_Stat 6000;
BA_REL_ "GenSigTimeoutTime" BU_SG_REL_ LECM3 SG_ 2549579584 PV_AlarmClockNotific_Stat 1500;
BA_REL_ "GenSigFirstTimeoutTime" BU_SG_REL_ LECM3 SG_ 2499772480 SlprMaxLightIntensity_Cmd 3000;
BA_REL_ "GenSigTimeoutTime" BU_SG_REL_ LECM3 SG_ 2499772480 SlprMaxLightIntensity_Cmd 300;
BA_REL_ "GenSigFirstTimeoutTime" BU_SG_REL_ CCM SG_ 2499772480 CoolantTempEM 3000;
BA_REL_ "GenSigTimeoutTime" BU_SG_REL_ CCM SG_ 2499772480 CoolantTempEM 300;
BA_REL_ "GenSigFirstTimeoutTime" BU_SG_REL_ LECM3 SG_ 2499772480 BlackOutandConvoyMode_rqst 3000;
BA_REL_ "GenSigTimeoutTime" BU_SG_REL_ LECM3 SG_ 2499772480 BlackOutandConvoyMode_rqst 300;
BA_REL_ "GenSigFirstTimeoutTime" BU_SG_REL_ CCM SG_ 2499772480 ChillerInClntTmp 3000;
BA_REL_ "GenSigTimeoutTime" BU_SG_REL_ CCM SG_ 2499772480 ChillerInClntTmp 300;
BA_REL_ "GenSigFirstTimeoutTime" BU_SG_REL_ CCM SG_ 2499772480 ChillerPumpFault 3000;
BA_REL_ "GenSigTimeoutTime" BU_SG_REL_ CCM SG_ 2499772480 ChillerPumpFault 300;
BA_REL_ "GenSigFirstTimeoutTime" BU_SG_REL_ LECM3 SG_ 2499772480 SlprLwrAmbLightIntensity_Cmd 3000;
BA_REL_ "GenSigTimeoutTime" BU_SG_REL_ LECM3 SG_ 2499772480 SlprLwrAmbLightIntensity_Cmd 300;
BA_REL_ "GenSigFirstTimeoutTime" BU_SG_REL_ LECM3 SG_ 2499772480 LECM_BunkPanicInd_cmd 3000;
BA_REL_ "GenSigTimeoutTime" BU_SG_REL_ LECM3 SG_ 2499772480 LECM_BunkPanicInd_cmd 300;
BA_REL_ "GenSigFirstTimeoutTime" BU_SG_REL_ LECM3 SG_ 2499772480 SlprUprAmbLightIntensity_Cmd 3000;
BA_REL_ "GenSigTimeoutTime" BU_SG_REL_ LECM3 SG_ 2499772480 SlprUprAmbLightIntensity_Cmd 300;
BA_REL_ "GenSigFirstTimeoutTime" BU_SG_REL_ CCM SG_ 2499772480 AuxFunCabPrecondition_Rqst 3000;
BA_REL_ "GenSigTimeoutTime" BU_SG_REL_ CCM SG_ 2499772480 AuxFunCabPrecondition_Rqst 300;
BA_REL_ "GenSigFirstTimeoutTime" BU_SG_REL_ LECM3 SG_ 2549294912 PS_InverterOverTemp 4800;
BA_REL_ "GenSigTimeoutTime" BU_SG_REL_ LECM3 SG_ 2549294912 PS_InverterOverTemp 1200;
BA_REL_ "GenSigFirstTimeoutTime" BU_SG_REL_ LECM3 SG_ 2549294912 PS_InverterOverVoltage 4800;
BA_REL_ "GenSigTimeoutTime" BU_SG_REL_ LECM3 SG_ 2549294912 PS_InverterOverVoltage 1200;
BA_REL_ "GenSigFirstTimeoutTime" BU_SG_REL_ LECM3 SG_ 2549294912 PS_MaxDefrostStatus 4800;
BA_REL_ "GenSigTimeoutTime" BU_SG_REL_ LECM3 SG_ 2549294912 PS_MaxDefrostStatus 1200;
BA_REL_ "GenSigFirstTimeoutTime" BU_SG_REL_ LECM3 SG_ 2549294912 PS_ParkingClimateReqDenied 4800;
BA_REL_ "GenSigTimeoutTime" BU_SG_REL_ LECM3 SG_ 2549294912 PS_ParkingClimateReqDenied 1200;
BA_REL_ "GenSigFirstTimeoutTime" BU_SG_REL_ LECM3 SG_ 2549294912 PS_InverterOutputMode 4800;
BA_REL_ "GenSigTimeoutTime" BU_SG_REL_ LECM3 SG_ 2549294912 PS_InverterOutputMode 1200;
BA_REL_ "GenSigFirstTimeoutTime" BU_SG_REL_ LECM3 SG_ 2549294912 PV_InverterPowerOutput 4800;
BA_REL_ "GenSigTimeoutTime" BU_SG_REL_ LECM3 SG_ 2549294912 PV_InverterPowerOutput 1200;
BA_REL_ "GenSigFirstTimeoutTime" BU_SG_REL_ LECM3 SG_ 2549294912 PV_InverterShoreVoltage 4800;
BA_REL_ "GenSigTimeoutTime" BU_SG_REL_ LECM3 SG_ 2549294912 PV_InverterShoreVoltage 1200;
BA_REL_ "GenSigFirstTimeoutTime" BU_SG_REL_ LECM3 SG_ 2549294912 PS_InverterShorePower 4800;
BA_REL_ "GenSigTimeoutTime" BU_SG_REL_ LECM3 SG_ 2549294912 PS_InverterShorePower 1200;
BA_REL_ "GenSigFirstTimeoutTime" BU_SG_REL_ CCM SG_ 2549294912 FuelVolume 4800;
BA_REL_ "GenSigTimeoutTime" BU_SG_REL_ CCM SG_ 2549294912 FuelVolume 1200;
BA_REL_ "GenSigFirstTimeoutTime" BU_SG_REL_ CCM SG_ 2549294912 FuelLevel 4800;
BA_REL_ "GenSigTimeoutTime" BU_SG_REL_ CCM SG_ 2549294912 FuelLevel 1200;
BA_REL_ "GenSigFirstTimeoutTime" BU_SG_REL_ LECM3 SG_ 2549294912 PS_InverterOverload 4800;
BA_REL_ "GenSigTimeoutTime" BU_SG_REL_ LECM3 SG_ 2549294912 PS_InverterOverload 1200;
BA_REL_ "GenSigFirstTimeoutTime" BU_SG_REL_ LECM3 SG_ 2549307200 PSACModeStatus 4800;
BA_REL_ "GenSigTimeoutTime" BU_SG_REL_ LECM3 SG_ 2549307200 PSACModeStatus 1200;
BA_REL_ "GenSigFirstTimeoutTime" BU_SG_REL_ LECM3 SG_ 2549307200 PS_FrontFanSpeedStatus 4800;
BA_REL_ "GenSigTimeoutTime" BU_SG_REL_ LECM3 SG_ 2549307200 PS_FrontFanSpeedStatus 1200;
BA_REL_ "GenSigFirstTimeoutTime" BU_SG_REL_ LECM3 SG_ 2549307200 PS_FrontACStatus 4800;
BA_REL_ "GenSigTimeoutTime" BU_SG_REL_ LECM3 SG_ 2549307200 PS_FrontACStatus 1200;
BA_REL_ "GenSigFirstTimeoutTime" BU_SG_REL_ LECM3 SG_ 2549307200 PS_BunkPowerStatus 4800;
BA_REL_ "GenSigTimeoutTime" BU_SG_REL_ LECM3 SG_ 2549307200 PS_BunkPowerStatus 1200;
BA_REL_ "GenSigFirstTimeoutTime" BU_SG_REL_ LECM3 SG_ 2549307200 PS_BunkACStatus 4800;
BA_REL_ "GenSigTimeoutTime" BU_SG_REL_ LECM3 SG_ 2549307200 PS_BunkACStatus 1200;
BA_REL_ "GenSigFirstTimeoutTime" BU_SG_REL_ LECM3 SG_ 2549307200 PV_FrontTemperatureStatus 4800;
BA_REL_ "GenSigTimeoutTime" BU_SG_REL_ LECM3 SG_ 2549307200 PV_FrontTemperatureStatus 1200;
BA_REL_ "GenSigFirstTimeoutTime" BU_SG_REL_ LECM3 SG_ 2549307200 PS_AutoModeStatus 4800;
BA_REL_ "GenSigTimeoutTime" BU_SG_REL_ LECM3 SG_ 2549307200 PS_AutoModeStatus 1200;
BA_REL_ "GenSigFirstTimeoutTime" BU_SG_REL_ LECM3 SG_ 2549307200 PS_BunkSyncStatus 4800;
BA_REL_ "GenSigTimeoutTime" BU_SG_REL_ LECM3 SG_ 2549307200 PS_BunkSyncStatus 1200;
BA_REL_ "GenSigFirstTimeoutTime" BU_SG_REL_ LECM3 SG_ 2549307200 PS_FrontHVACPowerStatus 4800;
BA_REL_ "GenSigTimeoutTime" BU_SG_REL_ LECM3 SG_ 2549307200 PS_FrontHVACPowerStatus 1200;
BA_REL_ "GenSigFirstTimeoutTime" BU_SG_REL_ LECM3 SG_ 2549307200 PS_ParkingClimateStatus 4800;
BA_REL_ "GenSigTimeoutTime" BU_SG_REL_ LECM3 SG_ 2549307200 PS_ParkingClimateStatus 1200;
BA_REL_ "GenSigFirstTimeoutTime" BU_SG_REL_ LECM3 SG_ 2549307200 PS_FrontSyncStatus 4800;
BA_REL_ "GenSigTimeoutTime" BU_SG_REL_ LECM3 SG_ 2549307200 PS_FrontSyncStatus 1200;
BA_REL_ "GenSigFirstTimeoutTime" BU_SG_REL_ LECM3 SG_ 2549307200 PS_BunkAutoStatus 4800;
BA_REL_ "GenSigTimeoutTime" BU_SG_REL_ LECM3 SG_ 2549307200 PS_BunkAutoStatus 1200;
BA_REL_ "GenSigFirstTimeoutTime" BU_SG_REL_ LECM3 SG_ 2549307200 PS_DoorLockStatusTimed 4800;
BA_REL_ "GenSigTimeoutTime" BU_SG_REL_ LECM3 SG_ 2549307200 PS_DoorLockStatusTimed 1200;
BA_REL_ "GenSigFirstTimeoutTime" BU_SG_REL_ LECM3 SG_ 2549307200 PV_BunkTemperatureStatus 4800;
BA_REL_ "GenSigTimeoutTime" BU_SG_REL_ LECM3 SG_ 2549307200 PV_BunkTemperatureStatus 1200;
BA_REL_ "GenSigFirstTimeoutTime" BU_SG_REL_ LECM3 SG_ 2549326400 PV_EntAudioLevels_Type 4800;
BA_REL_ "GenSigTimeoutTime" BU_SG_REL_ LECM3 SG_ 2549326400 PV_EntAudioLevels_Type 1200;
BA_REL_ "GenSigFirstTimeoutTime" BU_SG_REL_ LECM3 SG_ 2549326400 PS_EntAudioSourceStat 4800;
BA_REL_ "GenSigTimeoutTime" BU_SG_REL_ LECM3 SG_ 2549326400 PS_EntAudioSourceStat 1200;
BA_REL_ "GenSigFirstTimeoutTime" BU_SG_REL_ LECM3 SG_ 2549326400 PV_EntRadioFreq 4800;
BA_REL_ "GenSigTimeoutTime" BU_SG_REL_ LECM3 SG_ 2549326400 PV_EntRadioFreq 1200;
BA_REL_ "GenSigFirstTimeoutTime" BU_SG_REL_ LECM3 SG_ 2549326400 PV_EntAudioLevels_Level 4800;
BA_REL_ "GenSigTimeoutTime" BU_SG_REL_ LECM3 SG_ 2549326400 PV_EntAudioLevels_Level 1200;
BA_REL_ "GenSigFirstTimeoutTime" BU_SG_REL_ LECM3 SG_ 2549326400 PS_EntBunkSilentSts 4800;
BA_REL_ "GenSigTimeoutTime" BU_SG_REL_ LECM3 SG_ 2549326400 PS_EntBunkSilentSts 1200;
BA_REL_ "GenSigFirstTimeoutTime" BU_SG_REL_ LECM3 SG_ 2549326400 PS_EntChannelNo 4800;
BA_REL_ "GenSigTimeoutTime" BU_SG_REL_ LECM3 SG_ 2549326400 PS_EntChannelNo 1200;
BA_REL_ "GenSigFirstTimeoutTime" BU_SG_REL_ LECM3 SG_ 2566293568 PSPClimTimStatus_Tue 12000;
BA_REL_ "GenSigTimeoutTime" BU_SG_REL_ LECM3 SG_ 2566293568 PSPClimTimStatus_Tue 3000;
BA_REL_ "GenSigFirstTimeoutTime" BU_SG_REL_ LECM3 SG_ 2566293568 PSPClimTimStatus_Min 12000;
BA_REL_ "GenSigTimeoutTime" BU_SG_REL_ LECM3 SG_ 2566293568 PSPClimTimStatus_Min 3000;
BA_REL_ "GenSigFirstTimeoutTime" BU_SG_REL_ LECM3 SG_ 2566293568 PSPClimTimStatus_TotalNoTimers 12000;
BA_REL_ "GenSigTimeoutTime" BU_SG_REL_ LECM3 SG_ 2566293568 PSPClimTimStatus_TotalNoTimers 3000;
BA_REL_ "GenSigFirstTimeoutTime" BU_SG_REL_ LECM3 SG_ 2566293568 PSPClimTimStatus_TimerNr 12000;
BA_REL_ "GenSigTimeoutTime" BU_SG_REL_ LECM3 SG_ 2566293568 PSPClimTimStatus_TimerNr 3000;
BA_REL_ "GenSigFirstTimeoutTime" BU_SG_REL_ LECM3 SG_ 2566293568 PSPClimTimStatus_Rec 12000;
BA_REL_ "GenSigTimeoutTime" BU_SG_REL_ LECM3 SG_ 2566293568 PSPClimTimStatus_Rec 3000;
BA_REL_ "GenSigFirstTimeoutTime" BU_SG_REL_ LECM3 SG_ 2566293568 PSPClimTimStatus_Status 12000;
BA_REL_ "GenSigTimeoutTime" BU_SG_REL_ LECM3 SG_ 2566293568 PSPClimTimStatus_Status 3000;
BA_REL_ "GenSigFirstTimeoutTime" BU_SG_REL_ LECM3 SG_ 2566293568 PSPClimTimStatus_Dur 12000;
BA_REL_ "GenSigTimeoutTime" BU_SG_REL_ LECM3 SG_ 2566293568 PSPClimTimStatus_Dur 3000;
BA_REL_ "GenSigFirstTimeoutTime" BU_SG_REL_ LECM3 SG_ 2566293568 PSPClimTimStatus_Type 12000;
BA_REL_ "GenSigTimeoutTime" BU_SG_REL_ LECM3 SG_ 2566293568 PSPClimTimStatus_Type 3000;
BA_REL_ "GenSigFirstTimeoutTime" BU_SG_REL_ LECM3 SG_ 2566293568 PSPClimTimStatus_Wed 12000;
BA_REL_ "GenSigTimeoutTime" BU_SG_REL_ LECM3 SG_ 2566293568 PSPClimTimStatus_Wed 3000;
BA_REL_ "GenSigFirstTimeoutTime" BU_SG_REL_ LECM3 SG_ 2566293568 PSPClimTimStatus_Fri 12000;
BA_REL_ "GenSigTimeoutTime" BU_SG_REL_ LECM3 SG_ 2566293568 PSPClimTimStatus_Fri 3000;
BA_REL_ "GenSigFirstTimeoutTime" BU_SG_REL_ LECM3 SG_ 2566293568 PSPClimTimStatus_Thu 12000;
BA_REL_ "GenSigTimeoutTime" BU_SG_REL_ LECM3 SG_ 2566293568 PSPClimTimStatus_Thu 3000;
BA_REL_ "GenSigFirstTimeoutTime" BU_SG_REL_ LECM3 SG_ 2566293568 PSPClimTimStatus_Sat 12000;
BA_REL_ "GenSigTimeoutTime" BU_SG_REL_ LECM3 SG_ 2566293568 PSPClimTimStatus_Sat 3000;
BA_REL_ "GenSigFirstTimeoutTime" BU_SG_REL_ LECM3 SG_ 2566293568 PSPClimTimStatus_Hrs 12000;
BA_REL_ "GenSigTimeoutTime" BU_SG_REL_ LECM3 SG_ 2566293568 PSPClimTimStatus_Hrs 3000;
BA_REL_ "GenSigFirstTimeoutTime" BU_SG_REL_ LECM3 SG_ 2566293568 PSPClimTimStatus_MinRes 12000;
BA_REL_ "GenSigTimeoutTime" BU_SG_REL_ LECM3 SG_ 2566293568 PSPClimTimStatus_MinRes 3000;
BA_REL_ "GenSigFirstTimeoutTime" BU_SG_REL_ LECM3 SG_ 2566293568 PSPClimTimStatus_Temp 12000;
BA_REL_ "GenSigTimeoutTime" BU_SG_REL_ LECM3 SG_ 2566293568 PSPClimTimStatus_Temp 3000;
BA_REL_ "GenSigFirstTimeoutTime" BU_SG_REL_ LECM3 SG_ 2566293568 PSPClimTimStatus_Sun 12000;
BA_REL_ "GenSigTimeoutTime" BU_SG_REL_ LECM3 SG_ 2566293568 PSPClimTimStatus_Sun 3000;
BA_REL_ "GenSigFirstTimeoutTime" BU_SG_REL_ LECM3 SG_ 2566293568 PSPClimTimStatus_Mon 12000;
BA_REL_ "GenSigTimeoutTime" BU_SG_REL_ LECM3 SG_ 2566293568 PSPClimTimStatus_Mon 3000;
BA_REL_ "GenSigFirstTimeoutTime" BU_SG_REL_ LECM3 SG_ 2566359616 PV_AlarmClockAlarms_Type 12000;
BA_REL_ "GenSigTimeoutTime" BU_SG_REL_ LECM3 SG_ 2566359616 PV_AlarmClockAlarms_Type 3000;
BA_REL_ "GenSigFirstTimeoutTime" BU_SG_REL_ LECM3 SG_ 2566359616 PV_AlmClkCurAlarm_SetHr 12000;
BA_REL_ "GenSigTimeoutTime" BU_SG_REL_ LECM3 SG_ 2566359616 PV_AlmClkCurAlarm_SetHr 3000;
BA_REL_ "GenSigFirstTimeoutTime" BU_SG_REL_ CCM SG_ 2566359616 CabHeatManReq 24000;
BA_REL_ "GenSigTimeoutTime" BU_SG_REL_ CCM SG_ 2566359616 CabHeatManReq 3000;
BA_REL_ "GenSigFirstTimeoutTime" BU_SG_REL_ LECM3 SG_ 2566359616 PV_AlarmClockAlarms_Stat 12000;
BA_REL_ "GenSigTimeoutTime" BU_SG_REL_ LECM3 SG_ 2566359616 PV_AlarmClockAlarms_Stat 3000;
BA_REL_ "GenSigFirstTimeoutTime" BU_SG_REL_ LECM3 SG_ 2566359616 PV_AlarmClockAlarms_DaySet 12000;
BA_REL_ "GenSigTimeoutTime" BU_SG_REL_ LECM3 SG_ 2566359616 PV_AlarmClockAlarms_DaySet 3000;
BA_REL_ "GenSigFirstTimeoutTime" BU_SG_REL_ LECM3 SG_ 2566359616 PV_AlmClkCurAlarm_Stat 12000;
BA_REL_ "GenSigTimeoutTime" BU_SG_REL_ LECM3 SG_ 2566359616 PV_AlmClkCurAlarm_Stat 3000;
BA_REL_ "GenSigFirstTimeoutTime" BU_SG_REL_ LECM3 SG_ 2566359616 PV_AlarmClockAlarms_ID 12000;
BA_REL_ "GenSigTimeoutTime" BU_SG_REL_ LECM3 SG_ 2566359616 PV_AlarmClockAlarms_ID 3000;
BA_REL_ "GenSigFirstTimeoutTime" BU_SG_REL_ LECM3 SG_ 2566359616 PV_AlmClkCurAlarm_Type 12000;
BA_REL_ "GenSigTimeoutTime" BU_SG_REL_ LECM3 SG_ 2566359616 PV_AlmClkCurAlarm_Type 3000;
BA_REL_ "GenSigFirstTimeoutTime" BU_SG_REL_ LECM3 SG_ 2566359616 PV_AlmClkCurAlarm_ID 12000;
BA_REL_ "GenSigTimeoutTime" BU_SG_REL_ LECM3 SG_ 2566359616 PV_AlmClkCurAlarm_ID 3000;
BA_REL_ "GenSigFirstTimeoutTime" BU_SG_REL_ LECM3 SG_ 2566359616 PV_AlarmClockAlarms_SetMin 12000;
BA_REL_ "GenSigTimeoutTime" BU_SG_REL_ LECM3 SG_ 2566359616 PV_AlarmClockAlarms_SetMin 3000;
BA_REL_ "GenSigFirstTimeoutTime" BU_SG_REL_ LECM3 SG_ 2566359616 PS_AlarmClockAlarmSet 12000;
BA_REL_ "GenSigTimeoutTime" BU_SG_REL_ LECM3 SG_ 2566359616 PS_AlarmClockAlarmSet 3000;
BA_REL_ "GenSigFirstTimeoutTime" BU_SG_REL_ LECM3 SG_ 2566359616 PV_AlarmClockAlarms_Mode 12000;
BA_REL_ "GenSigTimeoutTime" BU_SG_REL_ LECM3 SG_ 2566359616 PV_AlarmClockAlarms_Mode 3000;
BA_REL_ "GenSigFirstTimeoutTime" BU_SG_REL_ LECM3 SG_ 2566359616 PV_AlmClkCurAlarm_SetMin 12000;
BA_REL_ "GenSigTimeoutTime" BU_SG_REL_ LECM3 SG_ 2566359616 PV_AlmClkCurAlarm_SetMin 3000;
BA_REL_ "GenSigFirstTimeoutTime" BU_SG_REL_ LECM3 SG_ 2566359616 PV_AlarmClockAlarms_SetHr 12000;
BA_REL_ "GenSigTimeoutTime" BU_SG_REL_ LECM3 SG_ 2566359616 PV_AlarmClockAlarms_SetHr 3000;
BA_REL_ "GenSigFirstTimeoutTime" BU_SG_REL_ LECM3 SG_ 2549793856 PV_LocalDay 6000;
BA_REL_ "GenSigTimeoutTime" BU_SG_REL_ LECM3 SG_ 2549793856 PV_LocalDay 1500;
BA_REL_ "GenSigFirstTimeoutTime" BU_SG_REL_ LECM3 SG_ 2549793856 PV_LocalMinute 6000;
BA_REL_ "GenSigTimeoutTime" BU_SG_REL_ LECM3 SG_ 2549793856 PV_LocalMinute 1500;
BA_REL_ "GenSigFirstTimeoutTime" BU_SG_REL_ LECM3 SG_ 2549793856 PV_LocalSecond 6000;
BA_REL_ "GenSigTimeoutTime" BU_SG_REL_ LECM3 SG_ 2549793856 PV_LocalSecond 1500;
BA_REL_ "GenSigFirstTimeoutTime" BU_SG_REL_ LECM3 SG_ 2549793856 PV_LocalHour 6000;
BA_REL_ "GenSigTimeoutTime" BU_SG_REL_ LECM3 SG_ 2549793856 PV_LocalHour 1500;
BA_REL_ "GenSigFirstTimeoutTime" BU_SG_REL_ LECM3 SG_ 2549793856 PV_LocalWeekday 6000;
BA_REL_ "GenSigTimeoutTime" BU_SG_REL_ LECM3 SG_ 2549793856 PV_LocalWeekday 1500;
BA_REL_ "GenSigFirstTimeoutTime" BU_SG_REL_ LECM3 SG_ 2549793856 PV_LocalYear 6000;
BA_REL_ "GenSigTimeoutTime" BU_SG_REL_ LECM3 SG_ 2549793856 PV_LocalYear 1500;
BA_REL_ "GenSigFirstTimeoutTime" BU_SG_REL_ LECM3 SG_ 2549793856 PV_LocalMonth 6000;
BA_REL_ "GenSigTimeoutTime" BU_SG_REL_ LECM3 SG_ 2549793856 PV_LocalMonth 1500;
BA_REL_ "GenSigFirstTimeoutTime" BU_SG_REL_ CCM SG_ 2561225792 ESSClntTmp 24000;
BA_REL_ "GenSigTimeoutTime" BU_SG_REL_ CCM SG_ 2561225792 ESSClntTmp 6000;
BA_REL_ "GenSigFirstTimeoutTime" BU_SG_REL_ CCM SG_ 2561225792 ChlrUsgRqst 24000;
BA_REL_ "GenSigTimeoutTime" BU_SG_REL_ CCM SG_ 2561225792 ChlrUsgRqst 6000;
BA_REL_ "GenSigFirstTimeoutTime" BU_SG_REL_ CCM SG_ 2561225792 ESSPmpSpd 24000;
BA_REL_ "GenSigTimeoutTime" BU_SG_REL_ CCM SG_ 2561225792 ESSPmpSpd 6000;
BA_REL_ "GenSigFirstTimeoutTime" BU_SG_REL_ CCM SG_ 2561225792 ESSTmp 24000;
BA_REL_ "GenSigTimeoutTime" BU_SG_REL_ CCM SG_ 2561225792 ESSTmp 6000;
BA_REL_ "GenSigFirstTimeoutTime" BU_SG_REL_ CCM SG_ 2561225792 ChlrVlvPsnFlt 24000;
BA_REL_ "GenSigTimeoutTime" BU_SG_REL_ CCM SG_ 2561225792 ChlrVlvPsnFlt 6000;
BA_REL_ "GenSigFirstTimeoutTime" BU_SG_REL_ CCM SG_ 2561225792 EMPmpSpd 24000;
BA_REL_ "GenSigTimeoutTime" BU_SG_REL_ CCM SG_ 2561225792 EMPmpSpd 6000;
BA_REL_ "GenSigFirstTimeoutTime" BU_SG_REL_ CCM SG_ 2561225792 RadrFnStatus 24000;
BA_REL_ "GenSigTimeoutTime" BU_SG_REL_ CCM SG_ 2561225792 RadrFnStatus 6000;
BA_REL_ "GenSigFirstTimeoutTime" BU_SG_REL_ CCM SG_ 2561225792 ESSTmpTrgt 24000;
BA_REL_ "GenSigTimeoutTime" BU_SG_REL_ CCM SG_ 2561225792 ESSTmpTrgt 6000;
BA_REL_ "GenSigFirstTimeoutTime" BU_SG_REL_ CCM SG_ 2566357824 CCtrlRemActTmpOpRqst_Act 24000;
BA_REL_ "GenSigTimeoutTime" BU_SG_REL_ CCM SG_ 2566357824 CCtrlRemActTmpOpRqst_Act 6000;
BA_REL_ "GenSigFirstTimeoutTime" BU_SG_REL_ CCM SG_ 2566357824 BarometricPressure 24000;
BA_REL_ "GenSigTimeoutTime" BU_SG_REL_ CCM SG_ 2566357824 BarometricPressure 6000;
BA_REL_ "GenSigFirstTimeoutTime" BU_SG_REL_ WRCS SG_ 2566357824 Trail4Type_Towing 24000;
BA_REL_ "GenSigTimeoutTime" BU_SG_REL_ WRCS SG_ 2566357824 Trail4Type_Towing 6000;
BA_REL_ "GenSigFirstTimeoutTime" BU_SG_REL_ WRCS SG_ 2566357824 Trail1Type_Towing 24000;
BA_REL_ "GenSigTimeoutTime" BU_SG_REL_ WRCS SG_ 2566357824 Trail1Type_Towing 6000;
BA_REL_ "GenSigFirstTimeoutTime" BU_SG_REL_ WRCS SG_ 2566357824 Trail3Type_Towing 24000;
BA_REL_ "GenSigTimeoutTime" BU_SG_REL_ WRCS SG_ 2566357824 Trail3Type_Towing 6000;
BA_REL_ "GenSigFirstTimeoutTime" BU_SG_REL_ WRCS SG_ 2566357824 Trail5Type_TrailType 24000;
BA_REL_ "GenSigTimeoutTime" BU_SG_REL_ WRCS SG_ 2566357824 Trail5Type_TrailType 6000;
BA_REL_ "GenSigFirstTimeoutTime" BU_SG_REL_ WRCS SG_ 2566357824 Trail1Type_TrailType 24000;
BA_REL_ "GenSigTimeoutTime" BU_SG_REL_ WRCS SG_ 2566357824 Trail1Type_TrailType 6000;
BA_REL_ "GenSigFirstTimeoutTime" BU_SG_REL_ WRCS SG_ 2566357824 Trail3Type_TrailType 24000;
BA_REL_ "GenSigTimeoutTime" BU_SG_REL_ WRCS SG_ 2566357824 Trail3Type_TrailType 6000;
BA_REL_ "GenSigFirstTimeoutTime" BU_SG_REL_ WRCS SG_ 2566357824 Trail5Type_Towing 24000;
BA_REL_ "GenSigTimeoutTime" BU_SG_REL_ WRCS SG_ 2566357824 Trail5Type_Towing 6000;
BA_REL_ "GenSigFirstTimeoutTime" BU_SG_REL_ WRCS SG_ 2566357824 Trail4Type_TrailType 24000;
BA_REL_ "GenSigTimeoutTime" BU_SG_REL_ WRCS SG_ 2566357824 Trail4Type_TrailType 6000;
BA_REL_ "GenSigFirstTimeoutTime" BU_SG_REL_ WRCS SG_ 2566357824 Trail2Type_Towing 24000;
BA_REL_ "GenSigTimeoutTime" BU_SG_REL_ WRCS SG_ 2566357824 Trail2Type_Towing 6000;
BA_REL_ "GenSigFirstTimeoutTime" BU_SG_REL_ CCM SG_ 2566357824 CCtrlRemActTmpOpRqst_Temp 24000;
BA_REL_ "GenSigTimeoutTime" BU_SG_REL_ CCM SG_ 2566357824 CCtrlRemActTmpOpRqst_Temp 6000;
BA_REL_ "GenSigFirstTimeoutTime" BU_SG_REL_ WRCS SG_ 2566357824 Trail2Type_TrailType 24000;
BA_REL_ "GenSigTimeoutTime" BU_SG_REL_ WRCS SG_ 2566357824 Trail2Type_TrailType 6000;
BA_REL_ "GenSigFirstTimeoutTime" BU_SG_REL_ WRCS SG_ 2566802240 Trail1NoOfAxles 24000;
BA_REL_ "GenSigTimeoutTime" BU_SG_REL_ WRCS SG_ 2566802240 Trail1NoOfAxles 6000;
BA_REL_ "GenSigFirstTimeoutTime" BU_SG_REL_ WRCS SG_ 2566802240 Trail3NoOfAxles 24000;
BA_REL_ "GenSigTimeoutTime" BU_SG_REL_ WRCS SG_ 2566802240 Trail3NoOfAxles 6000;
BA_REL_ "GenSigFirstTimeoutTime" BU_SG_REL_ WRCS SG_ 2566802240 Trail5NoOfAxles 24000;
BA_REL_ "GenSigTimeoutTime" BU_SG_REL_ WRCS SG_ 2566802240 Trail5NoOfAxles 6000;
BA_REL_ "GenSigFirstTimeoutTime" BU_SG_REL_ WRCS SG_ 2566802240 Trail5NoOfFrontAxles 24000;
BA_REL_ "GenSigTimeoutTime" BU_SG_REL_ WRCS SG_ 2566802240 Trail5NoOfFrontAxles 6000;
BA_REL_ "GenSigFirstTimeoutTime" BU_SG_REL_ WRCS SG_ 2566802240 Trail2NoOfFrontAxles 24000;
BA_REL_ "GenSigTimeoutTime" BU_SG_REL_ WRCS SG_ 2566802240 Trail2NoOfFrontAxles 6000;
BA_REL_ "GenSigFirstTimeoutTime" BU_SG_REL_ WRCS SG_ 2566802240 Trail1NoOfFrontAxles 24000;
BA_REL_ "GenSigTimeoutTime" BU_SG_REL_ WRCS SG_ 2566802240 Trail1NoOfFrontAxles 6000;
BA_REL_ "GenSigFirstTimeoutTime" BU_SG_REL_ WRCS SG_ 2566802240 Trail4NoOfAxles 24000;
BA_REL_ "GenSigTimeoutTime" BU_SG_REL_ WRCS SG_ 2566802240 Trail4NoOfAxles 6000;
BA_REL_ "GenSigFirstTimeoutTime" BU_SG_REL_ WRCS SG_ 2566802240 Trail3NoOfFrontAxles 24000;
BA_REL_ "GenSigTimeoutTime" BU_SG_REL_ WRCS SG_ 2566802240 Trail3NoOfFrontAxles 6000;
BA_REL_ "GenSigFirstTimeoutTime" BU_SG_REL_ WRCS SG_ 2566802240 Trail4NoOfFrontAxles 24000;
BA_REL_ "GenSigTimeoutTime" BU_SG_REL_ WRCS SG_ 2566802240 Trail4NoOfFrontAxles 6000;
BA_REL_ "GenSigFirstTimeoutTime" BU_SG_REL_ WRCS SG_ 2566802240 Trail2NoOfAxles 24000;
BA_REL_ "GenSigTimeoutTime" BU_SG_REL_ WRCS SG_ 2566802240 Trail2NoOfAxles 6000;
BA_REL_ "GenSigFirstTimeoutTime" BU_SG_REL_ CCM SG_ 2566653760 LECM_BunkClimatePowerRequest 24000;
BA_REL_ "GenSigTimeoutTime" BU_SG_REL_ CCM SG_ 2566653760 LECM_BunkClimatePowerRequest 6000;
BA_REL_ "GenSigFirstTimeoutTime" BU_SG_REL_ WRCS SG_ 2566653760 RelCargoLoadTrailer3 24000;
BA_REL_ "GenSigTimeoutTime" BU_SG_REL_ WRCS SG_ 2566653760 RelCargoLoadTrailer3 6000;
BA_REL_ "GenSigFirstTimeoutTime" BU_SG_REL_ WRCS SG_ 2566653760 RelCargoLoadTrailer5 24000;
BA_REL_ "GenSigTimeoutTime" BU_SG_REL_ WRCS SG_ 2566653760 RelCargoLoadTrailer5 6000;
BA_REL_ "GenSigFirstTimeoutTime" BU_SG_REL_ CCM SG_ 2566653760 LECM_ClimatePowerRequest 24000;
BA_REL_ "GenSigTimeoutTime" BU_SG_REL_ CCM SG_ 2566653760 LECM_ClimatePowerRequest 6000;
BA_REL_ "GenSigFirstTimeoutTime" BU_SG_REL_ WRCS SG_ 2566653760 RelCargoLoadTrailer4 24000;
BA_REL_ "GenSigTimeoutTime" BU_SG_REL_ WRCS SG_ 2566653760 RelCargoLoadTrailer4 6000;
BA_REL_ "GenSigFirstTimeoutTime" BU_SG_REL_ WRCS SG_ 2566579520 RelCargoLoadTrailer1 24000;
BA_REL_ "GenSigTimeoutTime" BU_SG_REL_ WRCS SG_ 2566579520 RelCargoLoadTrailer1 6000;
BA_REL_ "GenSigFirstTimeoutTime" BU_SG_REL_ WRCS SG_ 2566579520 LoadTrailer5 24000;
BA_REL_ "GenSigTimeoutTime" BU_SG_REL_ WRCS SG_ 2566579520 LoadTrailer5 6000;
BA_REL_ "GenSigFirstTimeoutTime" BU_SG_REL_ WRCS SG_ 2566579520 RelCargoLoadTrailer2 24000;
BA_REL_ "GenSigTimeoutTime" BU_SG_REL_ WRCS SG_ 2566579520 RelCargoLoadTrailer2 6000;
BA_REL_ "GenSigFirstTimeoutTime" BU_SG_REL_ WRCS SG_ 2566579520 RelCargoLoadTruck 24000;
BA_REL_ "GenSigTimeoutTime" BU_SG_REL_ WRCS SG_ 2566579520 RelCargoLoadTruck 6000;
BA_REL_ "GenSigFirstTimeoutTime" BU_SG_REL_ WRCS SG_ 2566505280 LoadTrailer4 24000;
BA_REL_ "GenSigTimeoutTime" BU_SG_REL_ WRCS SG_ 2566505280 LoadTrailer4 6000;
BA_REL_ "GenSigFirstTimeoutTime" BU_SG_REL_ WRCS SG_ 2566505280 LoadTrailer3 24000;
BA_REL_ "GenSigTimeoutTime" BU_SG_REL_ WRCS SG_ 2566505280 LoadTrailer3 6000;
BA_REL_ "GenSigFirstTimeoutTime" BU_SG_REL_ WRCS SG_ 2566505280 LoadTrailer2 24000;
BA_REL_ "GenSigTimeoutTime" BU_SG_REL_ WRCS SG_ 2566505280 LoadTrailer2 6000;
BA_REL_ "GenSigFirstTimeoutTime" BU_SG_REL_ WRCS SG_ 2566505280 LoadTrailer1 24000;
BA_REL_ "GenSigTimeoutTime" BU_SG_REL_ WRCS SG_ 2566505280 LoadTrailer1 6000;
BA_REL_ "GenSigFirstTimeoutTime" BU_SG_REL_ WRCS SG_ 2566431040 CalLoadTruckRearAxle2 24000;
BA_REL_ "GenSigTimeoutTime" BU_SG_REL_ WRCS SG_ 2566431040 CalLoadTruckRearAxle2 6000;
BA_REL_ "GenSigFirstTimeoutTime" BU_SG_REL_ WRCS SG_ 2566431040 CalLoadTruckRearAxle3 24000;
BA_REL_ "GenSigTimeoutTime" BU_SG_REL_ WRCS SG_ 2566431040 CalLoadTruckRearAxle3 6000;
BA_REL_ "GenSigFirstTimeoutTime" BU_SG_REL_ WRCS SG_ 2566431040 LoadTruck 24000;
BA_REL_ "GenSigTimeoutTime" BU_SG_REL_ WRCS SG_ 2566431040 LoadTruck 6000;
BA_REL_ "GenSigFirstTimeoutTime" BU_SG_REL_ WRCS SG_ 2566431040 CalLoadTruckRearAxle1 24000;
BA_REL_ "GenSigTimeoutTime" BU_SG_REL_ WRCS SG_ 2566431040 CalLoadTruckRearAxle1 6000;
BA_REL_ "GenSigFirstTimeoutTime" BU_SG_REL_ WRCS SG_ 2566357568 CalLoadTruckFrontAxle2 24000;
BA_REL_ "GenSigTimeoutTime" BU_SG_REL_ WRCS SG_ 2566357568 CalLoadTruckFrontAxle2 6000;
BA_REL_ "GenSigFirstTimeoutTime" BU_SG_REL_ WRCS SG_ 2566357568 CalLoadTruckFrontAxle1 24000;
BA_REL_ "GenSigTimeoutTime" BU_SG_REL_ WRCS SG_ 2566357568 CalLoadTruckFrontAxle1 6000;
BA_REL_ "GenSigFirstTimeoutTime" BU_SG_REL_ WRCS SG_ 2566357568 CalLoadTrailer5Axle6 24000;
BA_REL_ "GenSigTimeoutTime" BU_SG_REL_ WRCS SG_ 2566357568 CalLoadTrailer5Axle6 6000;
BA_REL_ "GenSigFirstTimeoutTime" BU_SG_REL_ WRCS SG_ 2566357568 CalLoadTrailer5Axle5 24000;
BA_REL_ "GenSigTimeoutTime" BU_SG_REL_ WRCS SG_ 2566357568 CalLoadTrailer5Axle5 6000;
BA_REL_ "GenSigFirstTimeoutTime" BU_SG_REL_ WRCS SG_ 2566282560 CalLoadTrailer5Axle1 24000;
BA_REL_ "GenSigTimeoutTime" BU_SG_REL_ WRCS SG_ 2566282560 CalLoadTrailer5Axle1 6000;
BA_REL_ "GenSigFirstTimeoutTime" BU_SG_REL_ WRCS SG_ 2566282560 CalLoadTrailer5Axle2 24000;
BA_REL_ "GenSigTimeoutTime" BU_SG_REL_ WRCS SG_ 2566282560 CalLoadTrailer5Axle2 6000;
BA_REL_ "GenSigFirstTimeoutTime" BU_SG_REL_ WRCS SG_ 2566282560 CalLoadTrailer5Axle4 24000;
BA_REL_ "GenSigTimeoutTime" BU_SG_REL_ WRCS SG_ 2566282560 CalLoadTrailer5Axle4 6000;
BA_REL_ "GenSigFirstTimeoutTime" BU_SG_REL_ WRCS SG_ 2566282560 CalLoadTrailer5Axle3 24000;
BA_REL_ "GenSigTimeoutTime" BU_SG_REL_ WRCS SG_ 2566282560 CalLoadTrailer5Axle3 6000;
BA_REL_ "GenSigFirstTimeoutTime" BU_SG_REL_ WRCS SG_ 2566208320 CalLoadTrailer4Axle5 24000;
BA_REL_ "GenSigTimeoutTime" BU_SG_REL_ WRCS SG_ 2566208320 CalLoadTrailer4Axle5 6000;
BA_REL_ "GenSigFirstTimeoutTime" BU_SG_REL_ WRCS SG_ 2566208320 CalLoadTrailer4Axle4 24000;
BA_REL_ "GenSigTimeoutTime" BU_SG_REL_ WRCS SG_ 2566208320 CalLoadTrailer4Axle4 6000;
BA_REL_ "GenSigFirstTimeoutTime" BU_SG_REL_ WRCS SG_ 2566208320 CalLoadTrailer4Axle3 24000;
BA_REL_ "GenSigTimeoutTime" BU_SG_REL_ WRCS SG_ 2566208320 CalLoadTrailer4Axle3 6000;
BA_REL_ "GenSigFirstTimeoutTime" BU_SG_REL_ WRCS SG_ 2566208320 CalLoadTrailer4Axle6 24000;
BA_REL_ "GenSigTimeoutTime" BU_SG_REL_ WRCS SG_ 2566208320 CalLoadTrailer4Axle6 6000;
BA_REL_ "GenSigFirstTimeoutTime" BU_SG_REL_ WRCS SG_ 2566134080 CalLoadTrailer3Axle6 24000;
BA_REL_ "GenSigTimeoutTime" BU_SG_REL_ WRCS SG_ 2566134080 CalLoadTrailer3Axle6 6000;
BA_REL_ "GenSigFirstTimeoutTime" BU_SG_REL_ WRCS SG_ 2566134080 CalLoadTrailer3Axle5 24000;
BA_REL_ "GenSigTimeoutTime" BU_SG_REL_ WRCS SG_ 2566134080 CalLoadTrailer3Axle5 6000;
BA_REL_ "GenSigFirstTimeoutTime" BU_SG_REL_ WRCS SG_ 2566134080 CalLoadTrailer4Axle1 24000;
BA_REL_ "GenSigTimeoutTime" BU_SG_REL_ WRCS SG_ 2566134080 CalLoadTrailer4Axle1 6000;
BA_REL_ "GenSigFirstTimeoutTime" BU_SG_REL_ WRCS SG_ 2566134080 CalLoadTrailer4Axle2 24000;
BA_REL_ "GenSigTimeoutTime" BU_SG_REL_ WRCS SG_ 2566134080 CalLoadTrailer4Axle2 6000;
BA_REL_ "GenSigFirstTimeoutTime" BU_SG_REL_ WRCS SG_ 2566059840 CalLoadTrailer3Axle1 24000;
BA_REL_ "GenSigTimeoutTime" BU_SG_REL_ WRCS SG_ 2566059840 CalLoadTrailer3Axle1 6000;
BA_REL_ "GenSigFirstTimeoutTime" BU_SG_REL_ WRCS SG_ 2566059840 CalLoadTrailer3Axle3 24000;
BA_REL_ "GenSigTimeoutTime" BU_SG_REL_ WRCS SG_ 2566059840 CalLoadTrailer3Axle3 6000;
BA_REL_ "GenSigFirstTimeoutTime" BU_SG_REL_ WRCS SG_ 2566059840 CalLoadTrailer3Axle4 24000;
BA_REL_ "GenSigTimeoutTime" BU_SG_REL_ WRCS SG_ 2566059840 CalLoadTrailer3Axle4 6000;
BA_REL_ "GenSigFirstTimeoutTime" BU_SG_REL_ WRCS SG_ 2566059840 CalLoadTrailer3Axle2 24000;
BA_REL_ "GenSigTimeoutTime" BU_SG_REL_ WRCS SG_ 2566059840 CalLoadTrailer3Axle2 6000;
BA_REL_ "GenSigFirstTimeoutTime" BU_SG_REL_ WRCS SG_ 2565985600 CalLoadTrailer2Axle4 24000;
BA_REL_ "GenSigTimeoutTime" BU_SG_REL_ WRCS SG_ 2565985600 CalLoadTrailer2Axle4 6000;
BA_REL_ "GenSigFirstTimeoutTime" BU_SG_REL_ WRCS SG_ 2565985600 CalLoadTrailer2Axle5 24000;
BA_REL_ "GenSigTimeoutTime" BU_SG_REL_ WRCS SG_ 2565985600 CalLoadTrailer2Axle5 6000;
BA_REL_ "GenSigFirstTimeoutTime" BU_SG_REL_ WRCS SG_ 2565985600 CalLoadTrailer2Axle3 24000;
BA_REL_ "GenSigTimeoutTime" BU_SG_REL_ WRCS SG_ 2565985600 CalLoadTrailer2Axle3 6000;
BA_REL_ "GenSigFirstTimeoutTime" BU_SG_REL_ WRCS SG_ 2565985600 CalLoadTrailer2Axle6 24000;
BA_REL_ "GenSigTimeoutTime" BU_SG_REL_ WRCS SG_ 2565985600 CalLoadTrailer2Axle6 6000;
BA_REL_ "GenSigFirstTimeoutTime" BU_SG_REL_ WRCS SG_ 2565911360 CalLoadTrailer1Axle6 24000;
BA_REL_ "GenSigTimeoutTime" BU_SG_REL_ WRCS SG_ 2565911360 CalLoadTrailer1Axle6 6000;
BA_REL_ "GenSigFirstTimeoutTime" BU_SG_REL_ WRCS SG_ 2565911360 CalLoadTrailer1Axle5 24000;
BA_REL_ "GenSigTimeoutTime" BU_SG_REL_ WRCS SG_ 2565911360 CalLoadTrailer1Axle5 6000;
BA_REL_ "GenSigFirstTimeoutTime" BU_SG_REL_ WRCS SG_ 2565911360 CalLoadTrailer2Axle1 24000;
BA_REL_ "GenSigTimeoutTime" BU_SG_REL_ WRCS SG_ 2565911360 CalLoadTrailer2Axle1 6000;
BA_REL_ "GenSigFirstTimeoutTime" BU_SG_REL_ WRCS SG_ 2565911360 CalLoadTrailer2Axle2 24000;
BA_REL_ "GenSigTimeoutTime" BU_SG_REL_ WRCS SG_ 2565911360 CalLoadTrailer2Axle2 6000;
VAL_ 2466243731 CMSMenu_stat 7 "CMSMenu_stat_NotAvailable" 6 "CMSMenu_stat_Error" 5 "CMSMenu_stat_Spare3" 4 "CMSMenu_stat_Spare2" 3 "CMSMenu_stat_BrightnessSettingsMenuClosed" 2 "CMSMenu_stat_BrightnessSettingsMenuOpened" 1 "CMSMenu_stat_SettingsMenuOpened" 0 "CMSMenu_stat_SettingsMenuClosed" ;
VAL_ 2466243731 CMSMirrorHeatingMode_stat 7 "MirrorHeat_NotAvailable" 6 "MirrorHeat_ErrorIndicator" 5 "MirrorHeat_SpareValue_02" 4 "MirrorHeat_SpareValue_01" 3 "MirrorHeat_SpareValue" 2 "MirrorHeat_ONExtendedMode" 1 "MirrorHeat_ONNormalMode" 0 "MirrorHeat_OFF" ;
VAL_ 2466243731 CMSDisplayButton1_stat 3 "PushButtonStatus_NotAvailable" 2 "PushButtonStatus_Error" 1 "PushButtonStatus_Pushed" 0 "PushButtonStatus_Neutral" ;
VAL_ 2466243731 CMSElectricalFOV_stat 7 "CMSElectricalFOV_stat_NotAvailable" 6 "CMSElectricalFOV_stat_Error" 5 "CMSElectricalFOV_stat_Spare3" 4 "CMSElectricalFOV_stat_Spare2" 3 "CMSElectricalFOV_stat_Spare1" 2 "CMSElectricalFOV_stat_ActivePassenger" 1 "CMSElectricalFOV_stat_ActiveDriver" 0 "CMSElectricalFOV_stat_Inactive" ;
VAL_ 2466243731 CMSPanning_stat 7 "CMSPanning_stat_NotAvailable" 6 "CMSPanning_stat_Error" 5 "CMSPanning_stat_Spare3" 4 "CMSPanning_stat_Spare2" 3 "CMSPanning_stat_Spare1" 2 "CMSPanning_stat_PanOut" 1 "CMSPanning_stat_On" 0 "CMSPanning_stat_Off" ;
VAL_ 2466243731 CMSEnhancedNightVision_stat 3 "InactiveActive_NotAvailable" 2 "InactiveActive_Error" 1 "InactiveActive_Active" 0 "InactiveActive_Inactive" ;
VAL_ 2466243731 DistanceLines_stat 7 "DistanceLines_stat_NotAvailable" 6 "DistanceLines_stat_Error" 5 "DistanceLines_stat_Spare3" 4 "DistanceLines_stat_Spare2" 3 "DistanceLines_stat_Spare1" 2 "DistanceLines_stat_HighwayLineActive" 1 "DistanceLines_stat_CityLineActive" 0 "DistanceLines_stat_ReverseLineActive" ;
VAL_ 2466243731 CMSLCSWarningLeftStatus_stat 7 "Warning3bit_4_NotAvailable" 6 "Warning3bit_4_Error" 5 "Warning3bit_4_Spare3" 4 "Warning3bit_4_Spare2" 3 "Warning3bit_4_Spare1" 2 "Warning3bit_4_WarningActive" 1 "Warning3bit_4_InformationActive" 0 "Warning3bit_4_NotActive" ;
VAL_ 2466243731 CMSEOVLine_stat 7 "OffOn3bit2_NotAvailable" 6 "OffOn3bit2_Error" 5 "OffOn3bit2_Spare4" 4 "OffOn3bit2_Spare3" 3 "OffOn3bit2_Spare2" 2 "OffOn3bit2_Spare1" 1 "OffOn3bit2_On" 0 "OffOn3bit2_Off" ;
VAL_ 2466243731 FixedReversePanOutView_stat 7 "FixedReversePanOutView_NotAvailable" 6 "FixedReversePanOutView_Error" 5 "FixedReversePanOutView_Spare3" 4 "FixedReversePanOutView_Spare2" 3 "FixedReversePanOutView_Spare1" 2 "FixedReversePanOutView_ActiveOnPassengerSide" 1 "FixedReversePanOutView_ActiveOnDriverSide" 0 "FixedReversePanOutView_Inactive" ;
VAL_ 2466243731 CMSFoldingMenuFeedback_stat 7 "OffOn3bit2_NotAvailable" 6 "OffOn3bit2_Error" 5 "OffOn3bit2_Spare4" 4 "OffOn3bit2_Spare3" 3 "OffOn3bit2_Spare2" 2 "OffOn3bit2_Spare1" 1 "OffOn3bit2_On" 0 "OffOn3bit2_Off" ;
VAL_ 2466243731 CMSAutoBrightnessAdj_stat 3 "InactiveActive_NotAvailable" 2 "InactiveActive_Error" 1 "InactiveActive_Active" 0 "InactiveActive_Inactive" ;
VAL_ 2466243731 CMSClassVActDeact_stat 7 "InactiveActive3bit2_NotAvailable" 6 "InactiveActive3bit2_Error" 5 "InactiveActive3bit2_Spare4" 4 "InactiveActive3bit2_Spare3" 3 "InactiveActive3bit2_Spare2" 2 "InactiveActive3bit2_Spare1" 1 "InactiveActive3bit2_Active" 0 "InactiveActive3bit2_Inactive" ;
VAL_ 2466243731 CMSLCSWarningRightStatus_stat 7 "Warning3bit_4_NotAvailable" 6 "Warning3bit_4_Error" 5 "Warning3bit_4_Spare3" 4 "Warning3bit_4_Spare2" 3 "Warning3bit_4_Spare1" 2 "Warning3bit_4_WarningActive" 1 "Warning3bit_4_InformationActive" 0 "Warning3bit_4_NotActive" ;
VAL_ 2495165760 CMSManualActDeactRqst_Request 3 "OffOn_NotAvailable" 2 "OffOn_Error" 1 "OffOn_On" 0 "OffOn_Off" ;
VAL_ 2495165760 CMSZoomRqst_Request 3 "InactiveActive_NotAvailable" 2 "InactiveActive_Error" 1 "InactiveActive_Active" 0 "InactiveActive_Inactive" ;
VAL_ 2495165760 CMSFoldingRqst_Request 7 "CMSFolding_rqst_NotAvailable" 6 "CMSFolding_rqst_Error" 5 "CMSFolding_rqst_Spare3" 4 "CMSFolding_rqst_OpenWingFoldingMenu" 3 "CMSFolding_rqst_CloseWingFoldingMenu" 2 "CMSFolding_rqst_FoldingRequest" 1 "CMSFolding_rqst_UnfoldingRequest" 0 "CMSFolding_rqst_NoRequest" ;
VAL_ 2495165760 CMSManualAlignmRqst_Request 7 "CMSManualAlignment_rqst_NotAvailable" 6 "CMSManualAlignment_rqst_Error" 5 "CMSManualAlignment_rqst_Close" 4 "CMSManualAlignment_rqst_Down" 3 "CMSManualAlignment_rqst_Up" 2 "CMSManualAlignment_rqst_OK" 1 "CMSManualAlignment_rqst_Active" 0 "CMSManualAlignment_rqst_Inactive" ;
VAL_ 2510689088 CMSEnhancedNightVision_rqst 3 "InactiveActive_NotAvailable" 2 "InactiveActive_Error" 1 "InactiveActive_Active" 0 "InactiveActive_Inactive" ;
VAL_ 2510689088 CMSMenu_rqst 7 "CMSMenu_rqst_NotAvailable" 6 "CMSMenu_rqst_Error" 5 "CMSMenu_rqst_Spare3" 4 "CMSMenu_rqst_Spare2" 3 "CMSMenu_rqst_BrightnessSettingsMenuClose" 2 "CMSMenu_rqst_BrightnessSettingsMenuOpen" 1 "CMSMenu_rqst_SettingsMenuOpen" 0 "CMSMenu_rqst_SettingsMenuClose" ;
VAL_ 2510689088 PanicAlarm_rqst 7 "PanicAlarm_rqst_NotAvailable" 6 "PanicAlarm_rqst_Error" 5 "PanicAlarm_rqst_Spare3" 4 "PanicAlarm_rqst_Spare2" 3 "PanicAlarm_rqst_Spare1" 2 "PanicAlarm_rqst_ActivatedInsideTheCab" 1 "PanicAlarm_rqst_ActivatedFromKeyfob" 0 "PanicAlarm_rqst_NotActivated" ;
VAL_ 2510689088 DoorsAjar_stat 7 "DoorsAjar_stat_NotAvailable" 6 "DoorsAjar_stat_Error" 5 "DoorsAjar_stat_Spare" 4 "DoorsAjar_stat_BothDoorsAreOpen" 3 "DoorsAjar_stat_PassengerDoorIsOpen" 2 "DoorsAjar_stat_DriverDoorIsOpen" 1 "DoorsAjar_stat_BothDoorsAreClosed" 0 "DoorsAjar_stat_Idle" ;
VAL_ 2510689088 CMSNavigation_rqst 7 "CMSNavigation_rqst_NotAvailable" 6 "CMSNavigation_rqst_Error" 5 "CMSNavigation_rqst_Right" 4 "CMSNavigation_rqst_Left" 3 "CMSNavigation_rqst_Down" 2 "CMSNavigation_rqst_Up" 1 "CMSNavigation_rqst_Middle" 0 "CMSNavigation_rqst_Off" ;
VAL_ 2510689088 TrailerConnected 3 "NoYes_NotAvailable" 2 "NoYes_Error" 1 "NoYes_Yes" 0 "NoYes_No" ;
VAL_ 2510689088 CMSAutoBrightnessAdj_rqst 3 "InactiveActive_NotAvailable" 2 "InactiveActive_Error" 1 "InactiveActive_Active" 0 "InactiveActive_Inactive" ;
VAL_ 2510689088 FixedReversePanOutView_rqst 7 "FixedReversePanOutView_NotAvailable" 6 "FixedReversePanOutView_Error" 5 "FixedReversePanOutView_Spare3" 4 "FixedReversePanOutView_Spare2" 3 "FixedReversePanOutView_Spare1" 2 "FixedReversePanOutView_ActiveOnPassengerSide" 1 "FixedReversePanOutView_ActiveOnDriverSide" 0 "FixedReversePanOutView_Inactive" ;
VAL_ 2510689088 CMSSelectedLanguage_stat 63 "PS_Language_NotAvailable" 62 "PS_Language_Spare_27" 61 "PS_Language_Spare_26" 60 "PS_Language_Spare_25" 59 "PS_Language_Spare_24" 58 "PS_Language_Spare_23" 57 "PS_Language_Spare_22" 56 "PS_Language_Spare_21" 55 "PS_Language_Spare_20" 54 "PS_Language_Spare_19" 53 "PS_Language_Spare_18" 52 "PS_Language_Spare_17" 51 "PS_Language_Spare_16" 50 "PS_Language_Spare_15" 49 "PS_Language_Spare_14" 48 "PS_Language_Spare_13" 47 "PS_Language_Spare_12" 46 "PS_Language_Spare_11" 45 "PS_Language_Spare_10" 44 "PS_Language_Spare_09" 43 "PS_Language_Spare_08" 42 "PS_Language_US_English" 41 "PS_Language_MexicanSpanish" 40 "PS_Language_CanadianFrench" 39 "PS_Language_Punjabi" 38 "PS_Language_Malay_Indonesian" 37 "PS_Language_Ukrainian" 36 "PS_Language_Bosnian" 35 "PS_Language_Croatian" 34 "PS_Language_Numeric" 33 "PS_Language_Japanese" 32 "PS_Language_Korean" 31 "PS_Language_Chinese" 30 "PS_Language_Thai" 29 "PS_Language_Arabic" 28 "PS_Language_Farsi" 27 "PS_Language_Hebrew" 26 "PS_Language_Turkish" 25 "PS_Language_Hungarian" 24 "PS_Language_Slovak" 23 "PS_Language_Czech" 22 "PS_Language_Slovenian" 21 "PS_Language_Serbian" 20 "PS_Language_Greek" 19 "PS_Language_Bulgarian" 18 "PS_Language_Italian" 17 "PS_Language_Dutch" 16 "PS_Language_Rumanian" 15 "PS_Language_BrazilianPortugese" 14 "PS_Language_Portugese" 13 "PS_Language_Spanish" 12 "PS_Language_French" 11 "PS_Language_German" 10 "PS_Language_Polish" 9 "PS_Language_Lituanian" 8 "PS_Language_Latvian" 7 "PS_Language_Estonian" 6 "PS_Language_Russian" 5 "PS_Language_Finish" 4 "PS_Language_Icelandic" 3 "PS_Language_Norwegian" 2 "PS_Language_Danish" 1 "PS_Language_Swedish" 0 "PS_Language_English" ;
VAL_ 2510689088 CMSMirrorHeat_rqst 7 "MirrorHeat_NotAvailable" 6 "MirrorHeat_ErrorIndicator" 5 "MirrorHeat_SpareValue_02" 4 "MirrorHeat_SpareValue_01" 3 "MirrorHeat_SpareValue" 2 "MirrorHeat_ONExtendedMode" 1 "MirrorHeat_ONNormalMode" 0 "MirrorHeat_OFF" ;
VAL_ 2510689088 PS_BunkFanSpeedStatus 15 "PS_FanSpeedStatus_NotAvailable" 14 "PS_FanSpeedStatus_Spare4" 13 "PS_FanSpeedStatus_Spare3" 12 "PS_FanSpeedStatus_Spare2" 11 "PS_FanSpeedStatus_Spare1" 10 "PS_FanSpeedStatus_FanSpeed10" 9 "PS_FanSpeedStatus_FanSpeed9" 8 "PS_FanSpeedStatus_FanSpeed8" 7 "PS_FanSpeedStatus_FanSpeed7" 6 "PS_FanSpeedStatus_FanSpeed6" 5 "PS_FanSpeedStatus_FanSpeed5" 4 "PS_FanSpeedStatus_FanSpeed4" 3 "PS_FanSpeedStatus_FanSpeed3" 2 "PS_FanSpeedStatus_FanSpeed2" 1 "PS_FanSpeedStatus_FanSpeed1" 0 "PS_FanSpeedStatus_FanSpeed0" ;
VAL_ 2510689088 PS_CMS_Status 3 "DeactivatedActivated_NotAvailable" 2 "DeactivatedActivated_Spare" 1 "DeactivatedActivated_Activated" 0 "DeactivatedActivated_Deactivated" ;
VAL_ 2510689088 AlarmStatus_stat 15 "AlarmStatus_stat_NotAvailable" 14 "AlarmStatus_stat_Error" 13 "AlarmStatus_stat_Spare_06" 12 "AlarmStatus_stat_Spare_05" 11 "AlarmStatus_stat_Spare_04" 10 "AlarmStatus_stat_Spare_03" 9 "AlarmStatus_stat_Spare_02" 8 "AlarmStatus_stat_Spare_01" 7 "AlarmStatus_stat_TamperMode" 6 "AlarmStatus_stat_ServiceMode" 5 "AlarmStatus_stat_AlarmMode" 4 "AlarmStatus_stat_PanicMode" 3 "AlarmStatus_stat_UnsetMode" 2 "AlarmStatus_stat_ReduceSetMode" 1 "AlarmStatus_stat_SetMode" 0 "AlarmStatus_stat_Idle" ;
VAL_ 2566730048 BunkACRequest 3 "OffOn_NotAvailable" 2 "OffOn_Error" 1 "OffOn_On" 0 "OffOn_Off" ;
VAL_ 2566730048 AirRecirculationRequest 3 "OffOn_NotAvailable" 2 "OffOn_Error" 1 "OffOn_On" 0 "OffOn_Off" ;
VAL_ 2566730048 MaxDefrostRequest 3 "OffOn_NotAvailable" 2 "OffOn_Error" 1 "OffOn_On" 0 "OffOn_Off" ;
VAL_ 2566730048 BunkParkClimateRequest 3 "OffOn_NotAvailable" 2 "OffOn_Error" 1 "OffOn_On" 0 "OffOn_Off" ;
VAL_ 2566730048 ParkingClimateRequest 3 "OffOn_NotAvailable" 2 "OffOn_Error" 1 "OffOn_On" 0 "OffOn_Off" ;
VAL_ 2566730048 BunkClimatePowerRequest 3 "OffOn_NotAvailable" 2 "OffOn_Error" 1 "OffOn_On" 0 "OffOn_Off" ;
VAL_ 2566730048 BunkClimateAutoRequest 3 "OffOn_NotAvailable" 2 "OffOn_Error" 1 "OffOn_On" 0 "OffOn_Off" ;
VAL_ 2566730048 ClimatePowerRequest 3 "OffOn_NotAvailable" 2 "OffOn_Error" 1 "OffOn_On" 0 "OffOn_Off" ;
VAL_ 2566730048 ClimateAutoRequest 3 "OffOn_NotAvailable" 2 "OffOn_Error" 1 "OffOn_On" 0 "OffOn_Off" ;
VAL_ 2566730048 ACRequest 3 "OffOn_NotAvailable" 2 "OffOn_Error" 1 "OffOn_On" 0 "OffOn_Off" ;
VAL_ 2566728000 SelectedSpeedUnit_stat 3 "SpeedUnit_NotAvailable" 2 "SpeedUnit_Error" 1 "SpeedUnit_MilesPerHour" 0 "SpeedUnit_KilometersPerHour" ;
VAL_ 2566728000 SelectedDistanceUnit_stat 3 "DistanceUnit_NotAvailable" 2 "DistanceUnit_Error" 1 "DistanceUnit_Miles" 0 "DistanceUnit_Kilometers" ;
VAL_ 2566728000 SelectedPressureUnit_stat 7 "PressureUnit_NotAvailable" 6 "PressureUnit_Error" 5 "PressureUnit_Spare3" 4 "PressureUnit_Spare2" 3 "PressureUnit_Spare1" 2 "PressureUnit_kPa" 1 "PressureUnit_Psi" 0 "PressureUnit_Bar" ;
VAL_ 2566728000 SelectedLangUnrestricted_stat 63 "Language_NotAvailable" 62 "Language_Error" 61 "Language_Spare_26" 60 "Language_Spare_25" 59 "Language_Spare_24" 58 "Language_Spare_23" 57 "Language_Spare_22" 56 "Language_Spare_21" 55 "Language_Spare_20" 54 "Language_Spare_19" 53 "Language_Spare_18" 52 "Language_Spare_17" 51 "Language_Spare_16" 50 "Language_Spare_15" 49 "Language_Spare_14" 48 "Language_Spare_13" 47 "Language_Spare_12" 46 "Language_Spare_11" 45 "Language_Spare_10" 44 "Language_Spare_09" 43 "Language_Spare_08" 42 "Language_US_English" 41 "Language_MexicanSpanish" 40 "Language_CandianFrench" 39 "Language_Punjabi" 38 "Language_Malay_Indonesian" 37 "Language_Ukrainian" 36 "Language_Bosnian" 35 "Language_Croatian" 34 "Language_Numeric" 33 "Language_Japanese" 32 "Language_Korean" 31 "Language_Chinese" 30 "Language_Thai" 29 "Language_Arabic" 28 "Language_Farsi" 27 "Language_Hebrew" 26 "Language_Turkish" 25 "Language_Hungarian" 24 "Language_Slovak" 23 "Language_Czech" 22 "Language_Slovenian" 21 "Language_Serbian" 20 "Language_Greek" 19 "Language_Bulgarian" 18 "Language_Italian" 17 "Language_Dutch" 16 "Language_Rumanian" 15 "Language_BrazilianPortugese" 14 "Language_Portugese" 13 "Language_Spanish" 12 "Language_French" 11 "Language_German" 10 "Language_Polish" 9 "Language_Lituanian" 8 "Language_Latvian" 7 "Language_Estonian" 6 "Language_Russian" 5 "Language_Finish" 4 "Language_Icelandic" 3 "Language_Norwegian" 2 "Language_Danish" 1 "Language_Swedish" 0 "Language_English" ;
VAL_ 2566728000 SelectedVolumeUnit_stat 7 "VolumeUnit_NotAvailable" 6 "VolumeUnit_Error" 5 "VolumeUnit_Spare_03" 4 "VolumeUnit_Spare_02" 3 "VolumeUnit_Spare_01" 2 "VolumeUnit_ImpGallons" 1 "VolumeUnit_USGallons" 0 "VolumeUnit_Litre" ;
VAL_ 2566728000 SelectedFuelConsumptUnit_stat 7 "SelectedFuelConsumptUnit_stat_NotAvailable" 6 "SelectedFuelConsumptUnit_stat_Error" 5 "SelectedFuelConsumptUnit_stat_Spare_01" 4 "SelectedFuelConsumptUnit_stat_Spare" 3 "SelectedFuelConsumptUnit_stat_MilesPerIMPGallon" 2 "SelectedFuelConsumptUnit_stat_MilesPerUSGallon" 1 "SelectedFuelConsumptUnit_stat_KilometersPerLitre" 0 "SelectedFuelConsumptUnit_stat_LitresPer100Kilometers" ;
VAL_ 2566728000 SelectedTemperatureUnit_stat 3 "TemperatureUnit_NotAvailable" 2 "TemperatureUnit_Error" 1 "TemperatureUnit_Fahrenheit" 0 "TemperatureUnit_Celcius" ;
VAL_ 2549579584 PS_AutoLoadCutOffState 7 "PS_AutoLoadCutOffState_NotAvailable" 6 "PS_AutoLoadCutOffState_Spare3" 5 "PS_AutoLoadCutOffState_Spare2" 4 "PS_AutoLoadCutOffState_Spare1" 3 "PS_AutoLoadCutOffState_Delayed" 2 "PS_AutoLoadCutOffState_Operating" 1 "PS_AutoLoadCutOffState_OnNotOperating" 0 "PS_AutoLoadCutOffState_Off" ;
VAL_ 2549579584 PS_LivingBatterySOCWarning 7 "ChargeWarning_NotAvailable" 6 "ChargeWarning_Spare4" 5 "ChargeWarning_Spare3" 4 "ChargeWarning_Critical" 3 "ChargeWarning_Spare2" 2 "ChargeWarning_Moderate" 1 "ChargeWarning_Spare1" 0 "ChargeWarning_NoWarning" ;
VAL_ 2549579584 PV_AlarmClockNotific_Type 7 "AlarmClkType_NotAvailable" 6 "AlarmClkType_Error" 5 "AlarmClkType_Reserved_02" 4 "AlarmClkType_Reserved_01" 3 "AlarmClkType_Light" 2 "AlarmClkType_Radio" 1 "AlarmClkType_Buzzer" 0 "AlarmClkType_NoAudibleNotification" ;
VAL_ 2549579584 PV_AlarmClockNotific_ID 127 "AlarmClkID_NotAvailable" 126 "AlarmClkID_Error" 10 "AlarmClkID_Alarm10" 9 "AlarmClkID_Alarm9" 8 "AlarmClkID_Alarm8" 7 "AlarmClkID_Alarm7" 6 "AlarmClkID_Alarm6" 5 "AlarmClkID_Alarm5" 4 "AlarmClkID_Alarm4" 3 "AlarmClkID_Alarm3" 2 "AlarmClkID_Alarm2" 1 "AlarmClkID_Alarm1" 0 "AlarmClkID_NotUsed" ;
VAL_ 2549579584 PS_AutoLoadCutOff 3 "RequestSpare_NotAvailable" 2 "RequestSpare_Spare" 1 "RequestSpare_RequestActive" 0 "RequestSpare_NotRequested" ;
VAL_ 2549579584 PS_LivingBatteryTempWarning 7 "ChargeWarning_NotAvailable" 6 "ChargeWarning_Spare4" 5 "ChargeWarning_Spare3" 4 "ChargeWarning_Critical" 3 "ChargeWarning_Spare2" 2 "ChargeWarning_Moderate" 1 "ChargeWarning_Spare1" 0 "ChargeWarning_NoWarning" ;
VAL_ 2549579584 PV_AlarmClockNotific_Stat 3 "AlarmClkStat_Spare" 2 "AlarmClkStat_NoUsed" 1 "AlarmClkStat_Active" 0 "AlarmClkStat_Inactive" ;
VAL_ 2499772480 BlackOutandConvoyMode_rqst 7 "BlackOutandConvoyMode_rqst_NotAvailable" 6 "BlackOutandConvoyMode_rqst_Error" 5 "BlackOutandConvoyMode_rqst_SpareValue_02" 4 "BlackOutandConvoyMode_rqst_SpareValue_01" 3 "BlackOutandConvoyMode_rqst_SpareValue" 2 "BlackOutandConvoyMode_rqst_ConvoyMode" 1 "BlackOutandConvoyMode_rqst_BlackOutMode" 0 "BlackOutandConvoyMode_rqst_NormalMode" ;
VAL_ 2499772480 ChillerPumpFault 7 "ChillerPumpFault_NotAvailable" 6 "ChillerPumpFault_Error" 5 "ChillerPumpFault_Spare3" 4 "ChillerPumpFault_Spare2" 3 "ChillerPumpFault_Spare1" 2 "ChillerPumpFault_DegradedMode" 1 "ChillerPumpFault_FaultActive" 0 "ChillerPumpFault_NoFault" ;
VAL_ 2499772480 LECM_BunkPanicInd_cmd 3 "InactiveActiveSpare_NotAvailable" 2 "InactiveActiveSpare_Spare" 1 "InactiveActiveSpare_Active" 0 "InactiveActiveSpare_Inactive" ;
VAL_ 2499772480 AuxFunCabPrecondition_Rqst 7 "AuxFunCabPreCondition_Rqst_NotAvailable" 6 "AuxFunCabPreCondition_Rqst_Spare4" 5 "AuxFunCabPreCondition_Rqst_Spare3" 4 "AuxFunCabPreCondition_Rqst_Spare2" 3 "AuxFunCabPreCondition_Rqst_Spare1" 2 "AuxFunCabPreCondition_Rqst_ClimatefeatureOff" 1 "AuxFunCabPreCondition_Rqst_Climatefeaturerequested" 0 "AuxFunCabPreCondition_Rqst_Idle" ;
VAL_ 2549294912 PS_InverterOverTemp 3 "PSOverTemp_NotAvailable" 2 "PSOverTemp_Spare" 1 "PSOverTemp_TemperatureTooHigh" 0 "PSOverTemp_TempWithinOperationalRange" ;
VAL_ 2549294912 PS_InverterOverVoltage 3 "PSOverVoltage_NotAvailable" 2 "PSOverVoltage_Spare" 1 "PSOverVoltage_OvervoltageCondition" 0 "PSOverVoltage_NoOvervoltageCondition" ;
VAL_ 2549294912 PS_MaxDefrostStatus 3 "InactiveActiveSpare_NotAvailable" 2 "InactiveActiveSpare_Spare" 1 "InactiveActiveSpare_Active" 0 "InactiveActiveSpare_Inactive" ;
VAL_ 2549294912 PS_ParkingClimateReqDenied 3 "NoYesSpare_NotAvailable" 2 "NoYesSpare_Spare" 1 "NoYesSpare_Yes" 0 "NoYesSpare_No" ;
VAL_ 2549294912 PS_InverterOutputMode 3 "OffOnSpare_NotAvailable" 2 "OffOnSpare_Spare" 1 "OffOnSpare_On" 0 "OffOnSpare_Off" ;
VAL_ 2549294912 PS_InverterShorePower 3 "ConnectionStatusSpare_NotAvailable" 2 "ConnectionStatusSpare_Spare" 1 "ConnectionStatusSpare_Connected" 0 "ConnectionStatusSpare_NotConnected" ;
VAL_ 2549294912 PS_InverterOverload 3 "PSOverload_NotAvailable" 2 "PSOverload_Spare" 1 "PSOverload_Overloaded" 0 "PSOverload_NotOverloaded" ;
VAL_ 2549307200 PSACModeStatus 7 "ACMode_NotAvailable" 6 "ACMode_Error" 5 "ACMode_Spare_01" 4 "ACMode_Spare" 3 "ACMode_ExtraDryCabAir" 2 "ACMode_HumidCabAir" 1 "ACMode_Standard" 0 "ACMode_Economy" ;
VAL_ 2549307200 PS_FrontFanSpeedStatus 15 "PS_FanSpeedStatus_NotAvailable" 14 "PS_FanSpeedStatus_Spare4" 13 "PS_FanSpeedStatus_Spare3" 12 "PS_FanSpeedStatus_Spare2" 11 "PS_FanSpeedStatus_Spare1" 10 "PS_FanSpeedStatus_FanSpeed10" 9 "PS_FanSpeedStatus_FanSpeed9" 8 "PS_FanSpeedStatus_FanSpeed8" 7 "PS_FanSpeedStatus_FanSpeed7" 6 "PS_FanSpeedStatus_FanSpeed6" 5 "PS_FanSpeedStatus_FanSpeed5" 4 "PS_FanSpeedStatus_FanSpeed4" 3 "PS_FanSpeedStatus_FanSpeed3" 2 "PS_FanSpeedStatus_FanSpeed2" 1 "PS_FanSpeedStatus_FanSpeed1" 0 "PS_FanSpeedStatus_FanSpeed0" ;
VAL_ 2549307200 PS_FrontACStatus 3 "InactiveActiveSpare_NotAvailable" 2 "InactiveActiveSpare_Spare" 1 "InactiveActiveSpare_Active" 0 "InactiveActiveSpare_Inactive" ;
VAL_ 2549307200 PS_BunkPowerStatus 3 "InactiveActiveSpare_NotAvailable" 2 "InactiveActiveSpare_Spare" 1 "InactiveActiveSpare_Active" 0 "InactiveActiveSpare_Inactive" ;
VAL_ 2549307200 PS_BunkACStatus 3 "InactiveActiveSpare_NotAvailable" 2 "InactiveActiveSpare_Spare" 1 "InactiveActiveSpare_Active" 0 "InactiveActiveSpare_Inactive" ;
VAL_ 2549307200 PV_FrontTemperatureStatus 31 "PV_TemperatureStatus_NotAvailable" 30 "PV_TemperatureStatus_Spare3" 29 "PV_TemperatureStatus_Spare2" 28 "PV_TemperatureStatus_Spare1" 27 "PV_TemperatureStatus_Max" 26 "PV_TemperatureStatus_29C" 25 "PV_TemperatureStatus_28C" 24 "PV_TemperatureStatus_27C" 23 "PV_TemperatureStatus_26C" 22 "PV_TemperatureStatus_25_5C" 21 "PV_TemperatureStatus_25C" 20 "PV_TemperatureStatus_24_5C" 19 "PV_TemperatureStatus_24C" 18 "PV_TemperatureStatus_23_5C" 17 "PV_TemperatureStatus_23C" 16 "PV_TemperatureStatus_22_5C" 15 "PV_TemperatureStatus_22C" 14 "PV_TemperatureStatus_21_5C" 13 "PV_TemperatureStatus_21C" 12 "PV_TemperatureStatus_20_5C" 11 "PV_TemperatureStatus_20C" 10 "PV_TemperatureStatus_19_5C" 9 "PV_TemperatureStatus_19C" 8 "PV_TemperatureStatus_18_5C" 7 "PV_TemperatureStatus_18C" 6 "PV_TemperatureStatus_17_5C" 5 "PV_TemperatureStatus_17C" 4 "PV_TemperatureStatus_16_5C" 3 "PV_TemperatureStatus_16C" 2 "PV_TemperatureStatus_15C" 1 "PV_TemperatureStatus_Min" 0 "PV_TemperatureStatus_NoTemperatureDisplayed" ;
VAL_ 2549307200 PS_AutoModeStatus 3 "InactiveActiveSpare_NotAvailable" 2 "InactiveActiveSpare_Spare" 1 "InactiveActiveSpare_Active" 0 "InactiveActiveSpare_Inactive" ;
VAL_ 2549307200 PS_BunkSyncStatus 3 "InactiveActiveSpare_NotAvailable" 2 "InactiveActiveSpare_Spare" 1 "InactiveActiveSpare_Active" 0 "InactiveActiveSpare_Inactive" ;
VAL_ 2549307200 PS_FrontHVACPowerStatus 3 "InactiveActiveSpare_NotAvailable" 2 "InactiveActiveSpare_Spare" 1 "InactiveActiveSpare_Active" 0 "InactiveActiveSpare_Inactive" ;
VAL_ 2549307200 PS_ParkingClimateStatus 3 "InactiveActiveSpare_NotAvailable" 2 "InactiveActiveSpare_Spare" 1 "InactiveActiveSpare_Active" 0 "InactiveActiveSpare_Inactive" ;
VAL_ 2549307200 PS_FrontSyncStatus 3 "InactiveActiveSpare_NotAvailable" 2 "InactiveActiveSpare_Spare" 1 "InactiveActiveSpare_Active" 0 "InactiveActiveSpare_Inactive" ;
VAL_ 2549307200 PS_BunkAutoStatus 3 "InactiveActiveSpare_NotAvailable" 2 "InactiveActiveSpare_Spare" 1 "InactiveActiveSpare_Active" 0 "InactiveActiveSpare_Inactive" ;
VAL_ 2549307200 PS_DoorLockStatusTimed 3 "DeviceIndication_SpareValue" 2 "DeviceIndication_Blink" 1 "DeviceIndication_On" 0 "DeviceIndication_Off" ;
VAL_ 2549307200 PV_BunkTemperatureStatus 31 "PV_TemperatureStatus_NotAvailable" 30 "PV_TemperatureStatus_Spare3" 29 "PV_TemperatureStatus_Spare2" 28 "PV_TemperatureStatus_Spare1" 27 "PV_TemperatureStatus_Max" 26 "PV_TemperatureStatus_29C" 25 "PV_TemperatureStatus_28C" 24 "PV_TemperatureStatus_27C" 23 "PV_TemperatureStatus_26C" 22 "PV_TemperatureStatus_25_5C" 21 "PV_TemperatureStatus_25C" 20 "PV_TemperatureStatus_24_5C" 19 "PV_TemperatureStatus_24C" 18 "PV_TemperatureStatus_23_5C" 17 "PV_TemperatureStatus_23C" 16 "PV_TemperatureStatus_22_5C" 15 "PV_TemperatureStatus_22C" 14 "PV_TemperatureStatus_21_5C" 13 "PV_TemperatureStatus_21C" 12 "PV_TemperatureStatus_20_5C" 11 "PV_TemperatureStatus_20C" 10 "PV_TemperatureStatus_19_5C" 9 "PV_TemperatureStatus_19C" 8 "PV_TemperatureStatus_18_5C" 7 "PV_TemperatureStatus_18C" 6 "PV_TemperatureStatus_17_5C" 5 "PV_TemperatureStatus_17C" 4 "PV_TemperatureStatus_16_5C" 3 "PV_TemperatureStatus_16C" 2 "PV_TemperatureStatus_15C" 1 "PV_TemperatureStatus_Min" 0 "PV_TemperatureStatus_NoTemperatureDisplayed" ;
VAL_ 2549326400 PV_EntAudioLevels_Type 15 "EntAudioLevelsType_NotAvailable" 14 "EntAudioLevelsType_Error" 13 "EntAudioLevelsType_Spare9" 12 "EntAudioLevelsType_Spare8" 11 "EntAudioLevelsType_Spare7" 10 "EntAudioLevelsType_Spare6" 9 "EntAudioLevelsType_Spare5" 8 "EntAudioLevelsType_Spare4" 7 "EntAudioLevelsType_Spare3" 6 "EntAudioLevelsType_Spare2" 5 "EntAudioLevelsType_Mid" 4 "EntAudioLevelsType_Fader" 3 "EntAudioLevelsType_Balance" 2 "EntAudioLevelsType_Treble" 1 "EntAudioLevelsType_Bass" 0 "EntAudioLevelsType_None" ;
VAL_ 2549326400 PS_EntAudioSourceStat 63 "PS_EntAudioSourceStat_NotAvailable" 62 "PS_EntAudioSourceStat_Error" 61 "PS_EntAudioSourceStat_Spare49" 60 "PS_EntAudioSourceStat_Spare48" 59 "PS_EntAudioSourceStat_Spare47" 58 "PS_EntAudioSourceStat_Spare46" 57 "PS_EntAudioSourceStat_Spare45" 56 "PS_EntAudioSourceStat_Spare44" 55 "PS_EntAudioSourceStat_Spare43" 54 "PS_EntAudioSourceStat_Spare42" 53 "PS_EntAudioSourceStat_Spare41" 52 "PS_EntAudioSourceStat_Spare40" 51 "PS_EntAudioSourceStat_Spare39" 50 "PS_EntAudioSourceStat_Spare38" 49 "PS_EntAudioSourceStat_Spare37" 48 "PS_EntAudioSourceStat_Spare36" 47 "PS_EntAudioSourceStat_Spare35" 46 "PS_EntAudioSourceStat_Spare34" 45 "PS_EntAudioSourceStat_Spare33" 44 "PS_EntAudioSourceStat_Spare32" 43 "PS_EntAudioSourceStat_Spare31" 42 "PS_EntAudioSourceStat_Spare30" 41 "PS_EntAudioSourceStat_Spare29" 40 "PS_EntAudioSourceStat_Spare28" 39 "PS_EntAudioSourceStat_Spare27" 38 "PS_EntAudioSourceStat_Spare26" 37 "PS_EntAudioSourceStat_Spare25" 36 "PS_EntAudioSourceStat_Spare24" 35 "PS_EntAudioSourceStat_Spare23" 34 "PS_EntAudioSourceStat_Spare22" 33 "PS_EntAudioSourceStat_Spare21" 32 "PS_EntAudioSourceStat_Spare20" 31 "PS_EntAudioSourceStat_Spare19" 30 "PS_EntAudioSourceStat_Spare18" 29 "PS_EntAudioSourceStat_Spare17" 28 "PS_EntAudioSourceStat_Spare16" 27 "PS_EntAudioSourceStat_Spare15" 26 "PS_EntAudioSourceStat_Spare14" 25 "PS_EntAudioSourceStat_Spare13" 24 "PS_EntAudioSourceStat_Spare12" 23 "PS_EntAudioSourceStat_Spare11" 22 "PS_EntAudioSourceStat_Spare10" 21 "PS_EntAudioSourceStat_Spare09" 20 "PS_EntAudioSourceStat_Spare08" 19 "PS_EntAudioSourceStat_Spare07" 18 "PS_EntAudioSourceStat_Spare06" 17 "PS_EntAudioSourceStat_Spare05" 16 "PS_EntAudioSourceStat_Spare04" 15 "PS_EntAudioSourceStat_Spare03" 14 "PS_EntAudioSourceStat_Spare02" 13 "PS_EntAudioSourceStat_Spare01" 12 "PS_EntAudioSourceStat_OtherUnknown" 11 "PS_EntAudioSourceStat_Alexa" 10 "PS_EntAudioSourceStat_ACP" 9 "PS_EntAudioSourceStat_AAP" 8 "PS_EntAudioSourceStat_Bt" 7 "PS_EntAudioSourceStat_AUX" 6 "PS_EntAudioSourceStat_USB" 5 "PS_EntAudioSourceStat_SiriusXM" 4 "PS_EntAudioSourceStat_WeatherBand" 3 "PS_EntAudioSourceStat_DAB" 2 "PS_EntAudioSourceStat_FM" 1 "PS_EntAudioSourceStat_AM" 0 "PS_EntAudioSourceStat_NoActiveSource" ;
VAL_ 2549326400 PS_EntBunkSilentSts 3 "PS_EntBunkSilentSts_NotAvailable" 2 "PS_EntBunkSilentSts_Spare" 1 "PS_EntBunkSilentSts_Silent" 0 "PS_EntBunkSilentSts_Normal" ;
VAL_ 2566293568 PSPClimTimStatus_Tue 1 "NotSelectedSelected_Selected" 0 "NotSelectedSelected_NotSelected" ;
VAL_ 2566293568 PSPClimTimStatus_Rec 1 "Rec_Recurrent" 0 "Rec_Once" ;
VAL_ 2566293568 PSPClimTimStatus_Status 3 "ParkHeaterTimer_Status_NotAvailable" 2 "ParkHeaterTimer_Status_TimerDeleted" 1 "ParkHeaterTimer_Status_TimerNotActivated" 0 "ParkHeaterTimer_Status_TimerActivated" ;
VAL_ 2566293568 PSPClimTimStatus_Type 7 "TimerType_NotAvailable" 6 "TimerType_Error" 5 "TimerType_Spare3" 4 "TimerType_Spare2" 3 "TimerType_Spare1" 2 "TimerType_CabClimateTimerWithStartTime" 1 "TimerType_EngineTimerWithReadyTime" 0 "TimerType_CabClimateTimerWithReadyTime" ;
VAL_ 2566293568 PSPClimTimStatus_Wed 1 "NotSelectedSelected_Selected" 0 "NotSelectedSelected_NotSelected" ;
VAL_ 2566293568 PSPClimTimStatus_Fri 1 "NotSelectedSelected_Selected" 0 "NotSelectedSelected_NotSelected" ;
VAL_ 2566293568 PSPClimTimStatus_Thu 1 "NotSelectedSelected_Selected" 0 "NotSelectedSelected_NotSelected" ;
VAL_ 2566293568 PSPClimTimStatus_Sat 1 "NotSelectedSelected_Selected" 0 "NotSelectedSelected_NotSelected" ;
VAL_ 2566293568 PSPClimTimStatus_MinRes 7 "MinRes_NotAvailable" 6 "MinRes_Error" 5 "MinRes_NoMinutesResolution" 4 "MinRes_30Minutes" 3 "MinRes_15Minutes" 2 "MinRes_10Minutes" 1 "MinRes_5Minutes" 0 "MinRes_1Minutes" ;
VAL_ 2566293568 PSPClimTimStatus_Sun 1 "NotSelectedSelected_Selected" 0 "NotSelectedSelected_NotSelected" ;
VAL_ 2566293568 PSPClimTimStatus_Mon 1 "NotSelectedSelected_Selected" 0 "NotSelectedSelected_NotSelected" ;
VAL_ 2566359616 PV_AlarmClockAlarms_Type 7 "AlarmClkType_NotAvailable" 6 "AlarmClkType_Error" 5 "AlarmClkType_Reserved_02" 4 "AlarmClkType_Reserved_01" 3 "AlarmClkType_Light" 2 "AlarmClkType_Radio" 1 "AlarmClkType_Buzzer" 0 "AlarmClkType_NoAudibleNotification" ;
VAL_ 2566359616 PV_AlarmClockAlarms_Stat 3 "AlarmClkStat2_Snoozed" 2 "AlarmClkStat2_Ringing" 1 "AlarmClkStat2_Active" 0 "AlarmClkStat2_Inactive" ;
VAL_ 2566359616 PV_AlmClkCurAlarm_Stat 3 "AlarmClkStat_Spare" 2 "AlarmClkStat_NoUsed" 1 "AlarmClkStat_Active" 0 "AlarmClkStat_Inactive" ;
VAL_ 2566359616 PV_AlarmClockAlarms_ID 127 "AlarmClkID_NotAvailable" 126 "AlarmClkID_Error" 10 "AlarmClkID_Alarm10" 9 "AlarmClkID_Alarm9" 8 "AlarmClkID_Alarm8" 7 "AlarmClkID_Alarm7" 6 "AlarmClkID_Alarm6" 5 "AlarmClkID_Alarm5" 4 "AlarmClkID_Alarm4" 3 "AlarmClkID_Alarm3" 2 "AlarmClkID_Alarm2" 1 "AlarmClkID_Alarm1" 0 "AlarmClkID_NotUsed" ;
VAL_ 2566359616 PV_AlmClkCurAlarm_Type 7 "AlarmClkType_NotAvailable" 6 "AlarmClkType_Error" 5 "AlarmClkType_Reserved_02" 4 "AlarmClkType_Reserved_01" 3 "AlarmClkType_Light" 2 "AlarmClkType_Radio" 1 "AlarmClkType_Buzzer" 0 "AlarmClkType_NoAudibleNotification" ;
VAL_ 2566359616 PV_AlmClkCurAlarm_ID 127 "AlarmClkID_NotAvailable" 126 "AlarmClkID_Error" 10 "AlarmClkID_Alarm10" 9 "AlarmClkID_Alarm9" 8 "AlarmClkID_Alarm8" 7 "AlarmClkID_Alarm7" 6 "AlarmClkID_Alarm6" 5 "AlarmClkID_Alarm5" 4 "AlarmClkID_Alarm4" 3 "AlarmClkID_Alarm3" 2 "AlarmClkID_Alarm2" 1 "AlarmClkID_Alarm1" 0 "AlarmClkID_NotUsed" ;
VAL_ 2566359616 PS_AlarmClockAlarmSet 3 "InactiveActiveSpare_NotAvailable" 2 "InactiveActiveSpare_Spare" 1 "InactiveActiveSpare_Active" 0 "InactiveActiveSpare_Inactive" ;
VAL_ 2566359616 PV_AlarmClockAlarms_Mode 3 "AlarmClkMode_Spare" 2 "AlarmClkMode_Timer" 1 "AlarmClkMode_Recurrent" 0 "AlarmClkMode_OneTime" ;
VAL_ 2549793856 PV_LocalWeekday 15 "DayOfWeekSpare_NotAvailable" 14 "DayOfWeekSpare_Spare" 13 "DayOfWeekSpare_Spare_7" 12 "DayOfWeekSpare_Spare_6" 11 "DayOfWeekSpare_Spare_5" 10 "DayOfWeekSpare_Spare_4" 9 "DayOfWeekSpare_Spare_3" 8 "DayOfWeekSpare_Spare_2" 7 "DayOfWeekSpare_Spare_1" 6 "DayOfWeekSpare_Sunday" 5 "DayOfWeekSpare_Saturday" 4 "DayOfWeekSpare_Friday" 3 "DayOfWeekSpare_Thursday" 2 "DayOfWeekSpare_Wednesday" 1 "DayOfWeekSpare_Tuesday" 0 "DayOfWeekSpare_Monday" ;
VAL_ 2561225792 ChlrVlvPsnFlt 3 "FalseTrue_NotAvaiable" 2 "FalseTrue_Error" 1 "FalseTrue_True" 0 "FalseTrue_False" ;
VAL_ 2561225792 RadrFnStatus 7 "RadrFnStatus_NotAvailable" 6 "RadrFnStatus_Error" 5 "RadrFnStatus_Spare2" 4 "RadrFnStatus_Spare1" 3 "RadrFnStatus_AllFansFaulty" 2 "RadrFnStatus_Fan2Faulty" 1 "RadrFnStatus_Fan1Faulty" 0 "RadrFnStatus_AllFansOk" ;
VAL_ 2566357824 CCtrlRemActTmpOpRqst_Act 7 "CabParkingClimateAct_NotAvailable" 6 "CabParkingClimateAct_Error" 5 "CabParkingClimateAct_spare3" 4 "CabParkingClimateAct_spare2" 3 "CabParkingClimateAct_spare1" 2 "CabParkingClimateAct_Deactivate" 1 "CabParkingClimateAct_Activate" 0 "CabParkingClimateAct_NoAction" ;
VAL_ 2566357824 Trail4Type_Towing 1 "Towing_TowingPossible" 0 "Towing_NoTowingOrOldTrailer" ;
VAL_ 2566357824 Trail1Type_Towing 1 "Towing_TowingPossible" 0 "Towing_NoTowingOrOldTrailer" ;
VAL_ 2566357824 Trail3Type_Towing 1 "Towing_TowingPossible" 0 "Towing_NoTowingOrOldTrailer" ;
VAL_ 2566357824 Trail5Type_TrailType 7 "TrailerType2_NotAvailable" 6 "TrailerType2_Spare" 5 "TrailerType2_NotConnected" 4 "TrailerType2_LinkTrailer" 3 "TrailerType2_Dolly" 2 "TrailerType2_DrawbarTrailer" 1 "TrailerType2_CentreAxleTrailer" 0 "TrailerType2_SemiTrailer" ;
VAL_ 2566357824 Trail1Type_TrailType 7 "TrailerType2_NotAvailable" 6 "TrailerType2_Spare" 5 "TrailerType2_NotConnected" 4 "TrailerType2_LinkTrailer" 3 "TrailerType2_Dolly" 2 "TrailerType2_DrawbarTrailer" 1 "TrailerType2_CentreAxleTrailer" 0 "TrailerType2_SemiTrailer" ;
VAL_ 2566357824 Trail3Type_TrailType 7 "TrailerType2_NotAvailable" 6 "TrailerType2_Spare" 5 "TrailerType2_NotConnected" 4 "TrailerType2_LinkTrailer" 3 "TrailerType2_Dolly" 2 "TrailerType2_DrawbarTrailer" 1 "TrailerType2_CentreAxleTrailer" 0 "TrailerType2_SemiTrailer" ;
VAL_ 2566357824 Trail5Type_Towing 1 "Towing_TowingPossible" 0 "Towing_NoTowingOrOldTrailer" ;
VAL_ 2566357824 Trail4Type_TrailType 7 "TrailerType2_NotAvailable" 6 "TrailerType2_Spare" 5 "TrailerType2_NotConnected" 4 "TrailerType2_LinkTrailer" 3 "TrailerType2_Dolly" 2 "TrailerType2_DrawbarTrailer" 1 "TrailerType2_CentreAxleTrailer" 0 "TrailerType2_SemiTrailer" ;
VAL_ 2566357824 Trail2Type_Towing 1 "Towing_TowingPossible" 0 "Towing_NoTowingOrOldTrailer" ;
VAL_ 2566357824 Trail2Type_TrailType 7 "TrailerType2_NotAvailable" 6 "TrailerType2_Spare" 5 "TrailerType2_NotConnected" 4 "TrailerType2_LinkTrailer" 3 "TrailerType2_Dolly" 2 "TrailerType2_DrawbarTrailer" 1 "TrailerType2_CentreAxleTrailer" 0 "TrailerType2_SemiTrailer" ;
VAL_ 2566653760 LECM_BunkClimatePowerRequest 3 "OffOn_NotAvailable" 2 "OffOn_Error" 1 "OffOn_On" 0 "OffOn_Off" ;
VAL_ 2566653760 LECM_ClimatePowerRequest 3 "OffOn_NotAvailable" 2 "OffOn_Error" 1 "OffOn_On" 0 "OffOn_Off" ;
SIG_GROUP_ 2495165760 CMSManualActDeactRqst_sg 1 : CMSManualActDeactRqst_Request CMSManualActDeactRqst_SqC CMSManualActDeactRqst_CRC;
SIG_GROUP_ 2495165760 CMSManualAlignmRqst_sg 1 : CMSManualAlignmRqst_SqC CMSManualAlignmRqst_CRC CMSManualAlignmRqst_Request;
SIG_GROUP_ 2495165760 CMSFoldingRqst_sg 1 : CMSFoldingRqst_CRC CMSFoldingRqst_Request CMSFoldingRqst_SqC;
SIG_GROUP_ 2495165760 CMSZoomRqst_sg 1 : CMSZoomRqst_SqC CMSZoomRqst_Request CMSZoomRqst_CRC;
SIG_GROUP_ 2566730048 ClimateAirDistRequest_sg 1 : ClimateAirDistRequest_Vent ClimateAirDistRequest_Defrost ClimateAirDistRequest_Floor;
SIG_GROUP_ 2549579584 PV_AlarmClockNotific_sg 1 : PV_AlarmClockNotific_Type PV_AlarmClockNotific_ID PV_AlarmClockNotific_Stat;
SIG_GROUP_ 2549326400 PV_EntAudioLevels_sg 1 : PV_EntAudioLevels_Type PV_EntAudioLevels_Level;
SIG_GROUP_ 2566293568 PSPClimTimStatus_sg 1 : PSPClimTimStatus_Tue PSPClimTimStatus_Min PSPClimTimStatus_TotalNoTimers PSPClimTimStatus_TimerNr PSPClimTimStatus_Rec PSPClimTimStatus_Status PSPClimTimStatus_Dur PSPClimTimStatus_Type PSPClimTimStatus_Wed PSPClimTimStatus_Fri PSPClimTimStatus_Thu PSPClimTimStatus_Sat PSPClimTimStatus_Hrs PSPClimTimStatus_MinRes PSPClimTimStatus_Temp PSPClimTimStatus_Sun PSPClimTimStatus_Mon;
SIG_GROUP_ 2566359616 PV_AlmClkCurAlarm_sg 1 : PV_AlmClkCurAlarm_SetHr PV_AlmClkCurAlarm_Stat PV_AlmClkCurAlarm_Type PV_AlmClkCurAlarm_ID PV_AlmClkCurAlarm_SetMin;
SIG_GROUP_ 2566359616 PV_AlarmClockAlarms_sg 1 : PV_AlarmClockAlarms_Type PV_AlarmClockAlarms_Stat PV_AlarmClockAlarms_DaySet PV_AlarmClockAlarms_ID PV_AlarmClockAlarms_SetMin PV_AlarmClockAlarms_Mode PV_AlarmClockAlarms_SetHr;
SIG_GROUP_ 2566357824 Trail1Type_sg 1 : Trail1Type_Towing Trail1Type_TrailType;
SIG_GROUP_ 2566357824 CCtrlRemActTmpOpRqst_sg 1 : CCtrlRemActTmpOpRqst_Act CCtrlRemActTmpOpRqst_Temp;
SIG_GROUP_ 2566357824 Trail2Type_sg 1 : Trail2Type_Towing Trail2Type_TrailType;
SIG_GROUP_ 2566357824 Trail3Type_sg 1 : Trail3Type_Towing Trail3Type_TrailType;
SIG_GROUP_ 2566357824 Trail5Type_sg 1 : Trail5Type_TrailType Trail5Type_Towing;
SIG_GROUP_ 2566357824 Trail4Type_sg 1 : Trail4Type_Towing Trail4Type_TrailType;
